VERSION ""

NS_ :

BS_:

BU_: Antilock_Brake_Module AudioControlModule AudioInterfaceModule Audio_Control_Module Audio_Interface_Module BluetoothPhoneModule Bluetooth_Phone_Module BodyElectricModule Body_Electronic_Module Data_Request Data_Response Diagnostic_Tester FrontDisplayInterfaceModule Front_Display_Interface_Module HVAC_Integrated_Module HvacIntegratedModule InstrumentCluster Instrument_Cluster NegativeResponseError OnBoardDiagnostics On_Board_Diagnostics ParkingAidModule Parking_Aid_Module PowertrainControlModule Powertrain_Control_Module RestraintsControlModule Restraints_Control_Module SteeringAngleSensor Steering_Angle_Sensor TDC Transmission_Control_Module Vector__XXX before

CM_ "FG Falcon Combined CAN DBC. Generated from uploaded highSpeedCAN.dbc and BigFalconSheet(1).xlsx. Byte-level overview signals are conservative placeholders where exact scaling/bit layout was not available.";
BA_DEF_ BO_  "Bus" STRING ;
BA_DEF_DEF_  "Bus" "" ;

VAL_TABLE_ Inst_Econ_Mode 1 "L per Hr" 0 "L per 100Km" ;
VAL_TABLE_ Transmission_Configuration 1 "Copperhead" 0 "Barra_E265" ;
VAL_TABLE_ Fuel_Type_And_Delivery 12 "Petrol LPG Dual Fuel" 11 "LPG EFI" 2 "Petrol EFI" ;
VAL_TABLE_ Induction_Type 9 "Unknown" 4 "None" 3 "Supercharged" 2 "Turbocharged" 1 "Naturally Aspirated" ;
VAL_TABLE_ Dash_Ind_State 2 "Flash" 1 "On" 0 "Off" ;
VAL_TABLE_ Gear_Position_Target 15 "Invalid" 12 "Reverse" 6 "Sixth" 5 "Fifth" 4 "Fourth" 3 "Third" 2 "Second" 1 "First" 0 "Neutral" ;
VAL_TABLE_ Required_NotRequired 1 "Not Required" 0 "Required" ;
VAL_TABLE_ Engaged_Disengaged 1 "Engaged" 0 "Disengaged" ;
VAL_TABLE_ Transmission_Shift_Map 7 "Cruise " 6 "Manual" 5 "Traction" 4 "Gradient" 3 "Hot" 2 "Not Used" 1 "Sports" 0 "Normal" ;
VAL_TABLE_ Gear_Position_Actual 15 "Gear Shift In Progress" 12 "Reverse" 6 "Sixth" 5 "Fifth" 4 "Fourth" 3 "Third" 2 "Second" 1 "First" 0 "Neutral" ;
VAL_TABLE_ Gear_Position_Selected 15 "Intermediate" 7 "Fifth" 6 "Second" 5 "Third" 4 "Fourth" 3 "Drive" 2 "Neutral" 1 "Reverse" 0 "Park" ;
VAL_TABLE_ Off_On 1 "On" 0 "Off" ;
VAL_TABLE_ Transmission_Mode 6 "Reserved - Creep" 5 "Economy" 4 "Reserved - Winter" 3 "Manual Shift Mode" 2 "Performance" 1 "ADP" 0 "Blank" ;
VAL_TABLE_ Trans_Gear_Pos 255 "Invalid" 241 "Neutral" 240 "Park" 19 "Forward Gear 9" 18 "Forward Gear 8" 17 "Forward Gear 7" 16 "Forward Gear 6" 11 "Reserved" 10 "Reverse" 6 "Forward Gear D" 5 "Forward Gear 5" 4 "Forward Gear 4" 3 "Forward Gear 3" 2 "Forward Gear 2" 1 "Forward Gear 1" 0 "Blank" ;
VAL_TABLE_ Eng_Crank_Status 3 "Low Voltage Crank Attempt" 2 "Crank In Progress" 1 "Crank Pending" 0 "No Action" ;
VAL_TABLE_ Torque_Type 1 "Engine Torque" 0 "Axle Torque" ;
VAL_TABLE_ Brake_State 3 "Reserved2" 2 "Reserved1" 1 "Brake Pedal Pressed" 0 "Brake Pedal Off" ;
VAL_TABLE_ Cruise_Status 7 "Cruise Active" 2 "Cruise Resume" 1 "Cruise On" 0 "Cruise Off" ;
VAL_TABLE_ Active_Inactive 1 "Active" 0 "Inactive" ;
VAL_TABLE_ True_False 1 "True" 0 "False" ;

BO_ 0 AudioInterfaceModule: 8 AudioInterfaceModule
 SG_ IPOD_FRMVER : 0|8@1+ (1,0) [0|0] "" AudioInterfaceModule
 SG_ AUTHENT_DEVER : 0|8@1+ (1,0) [0|0] "" AudioInterfaceModule
 SG_ CON_DEVERR : 0|8@1+ (1,0) [0|0] "" AudioInterfaceModule
 SG_ CON_DEVMODID : 0|8@1+ (1,0) [0|0] "" AudioInterfaceModule
 SG_ SEC_STAT : 0|8@1+ (1,0) [0|0] "" AudioInterfaceModule
 SG_ NUM_DTC : 0|8@1+ (1,0) [0|0] "" AudioInterfaceModule

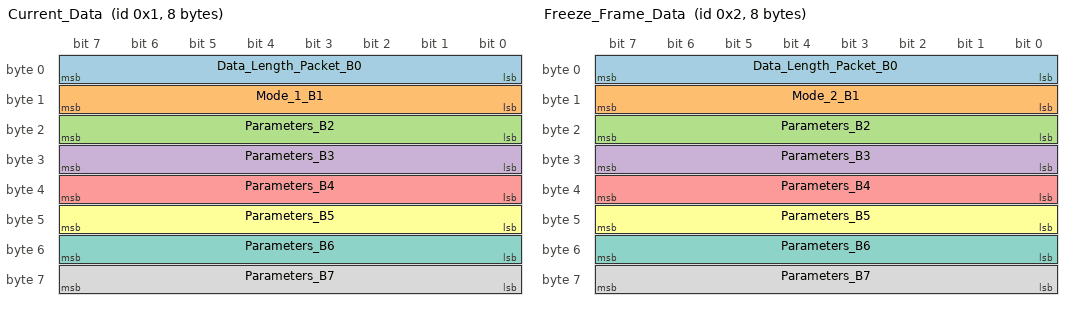
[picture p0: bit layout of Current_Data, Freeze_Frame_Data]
BO_ 1 Current_Data: 8 On_Board_Diagnostics
 SG_ Data_Length_Packet_B0 : 0|8@1+ (1,0) [0|255] "" Vector__XXX
 SG_ Mode_1_B1 : 8|8@1+ (1,0) [0|255] "" Vector__XXX
 SG_ Parameters_B2 : 16|8@1+ (1,0) [0|255] "" Vector__XXX
 SG_ Parameters_B3 : 24|8@1+ (1,0) [0|255] "" Vector__XXX
 SG_ Parameters_B4 : 32|8@1+ (1,0) [0|255] "" Vector__XXX
 SG_ Parameters_B5 : 40|8@1+ (1,0) [0|255] "" Vector__XXX
 SG_ Parameters_B6 : 48|8@1+ (1,0) [0|255] "" Vector__XXX
 SG_ Parameters_B7 : 56|8@1+ (1,0) [0|255] "" Vector__XXX

BO_ 2 Freeze_Frame_Data: 8 On_Board_Diagnostics
 SG_ Data_Length_Packet_B0 : 0|8@1+ (1,0) [0|255] "" Vector__XXX
 SG_ Mode_2_B1 : 8|8@1+ (1,0) [0|255] "" Vector__XXX
 SG_ Parameters_B2 : 16|8@1+ (1,0) [0|255] "" Vector__XXX
 SG_ Parameters_B3 : 24|8@1+ (1,0) [0|255] "" Vector__XXX
 SG_ Parameters_B4 : 32|8@1+ (1,0) [0|255] "" Vector__XXX
 SG_ Parameters_B5 : 40|8@1+ (1,0) [0|255] "" Vector__XXX
 SG_ Parameters_B6 : 48|8@1+ (1,0) [0|255] "" Vector__XXX
 SG_ Parameters_B7 : 56|8@1+ (1,0) [0|255] "" Vector__XXX

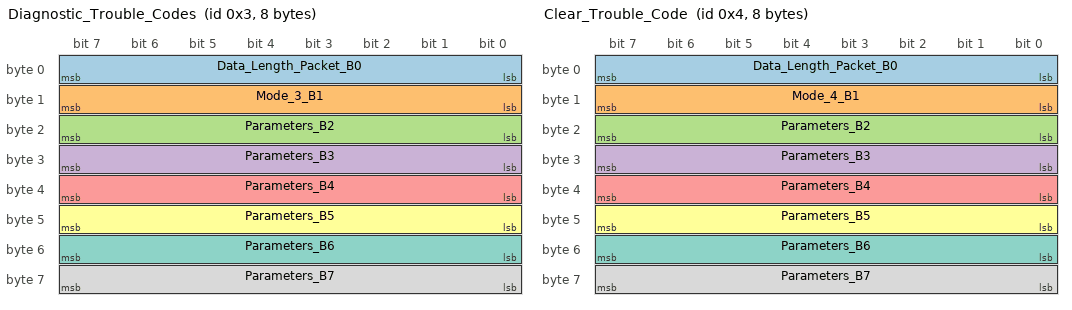
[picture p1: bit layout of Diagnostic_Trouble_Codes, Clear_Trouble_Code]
BO_ 3 Diagnostic_Trouble_Codes: 8 On_Board_Diagnostics
 SG_ Data_Length_Packet_B0 : 0|8@1+ (1,0) [0|255] "" Vector__XXX
 SG_ Mode_3_B1 : 8|8@1+ (1,0) [0|255] "" Vector__XXX
 SG_ Parameters_B2 : 16|8@1+ (1,0) [0|255] "" Vector__XXX
 SG_ Parameters_B3 : 24|8@1+ (1,0) [0|255] "" Vector__XXX
 SG_ Parameters_B4 : 32|8@1+ (1,0) [0|255] "" Vector__XXX
 SG_ Parameters_B5 : 40|8@1+ (1,0) [0|255] "" Vector__XXX
 SG_ Parameters_B6 : 48|8@1+ (1,0) [0|255] "" Vector__XXX
 SG_ Parameters_B7 : 56|8@1+ (1,0) [0|255] "" Vector__XXX

BO_ 4 Clear_Trouble_Code: 8 On_Board_Diagnostics
 SG_ Data_Length_Packet_B0 : 0|8@1+ (1,0) [0|255] "" Vector__XXX
 SG_ Mode_4_B1 : 8|8@1+ (1,0) [0|255] "" Vector__XXX
 SG_ Parameters_B2 : 16|8@1+ (1,0) [0|255] "" Vector__XXX
 SG_ Parameters_B3 : 24|8@1+ (1,0) [0|255] "" Vector__XXX
 SG_ Parameters_B4 : 32|8@1+ (1,0) [0|255] "" Vector__XXX
 SG_ Parameters_B5 : 40|8@1+ (1,0) [0|255] "" Vector__XXX
 SG_ Parameters_B6 : 48|8@1+ (1,0) [0|255] "" Vector__XXX
 SG_ Parameters_B7 : 56|8@1+ (1,0) [0|255] "" Vector__XXX

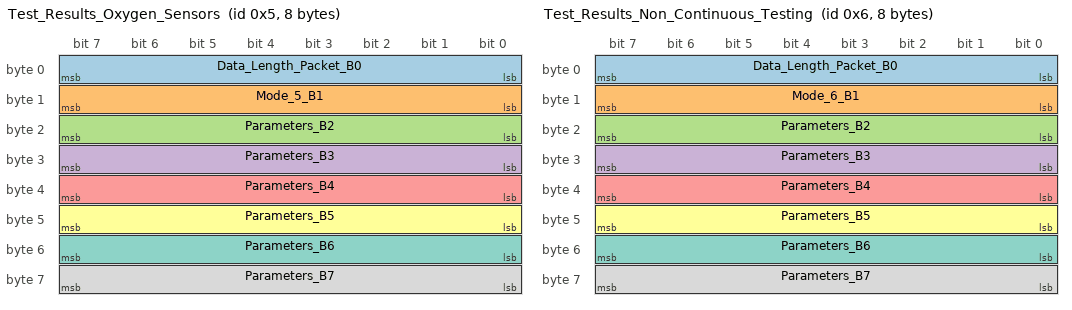
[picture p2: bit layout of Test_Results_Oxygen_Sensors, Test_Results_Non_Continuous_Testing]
BO_ 5 Test_Results_Oxygen_Sensors: 8 On_Board_Diagnostics
 SG_ Data_Length_Packet_B0 : 0|8@1+ (1,0) [0|255] "" Vector__XXX
 SG_ Mode_5_B1 : 8|8@1+ (1,0) [0|255] "" Vector__XXX
 SG_ Parameters_B2 : 16|8@1+ (1,0) [0|255] "" Vector__XXX
 SG_ Parameters_B3 : 24|8@1+ (1,0) [0|255] "" Vector__XXX
 SG_ Parameters_B4 : 32|8@1+ (1,0) [0|255] "" Vector__XXX
 SG_ Parameters_B5 : 40|8@1+ (1,0) [0|255] "" Vector__XXX
 SG_ Parameters_B6 : 48|8@1+ (1,0) [0|255] "" Vector__XXX
 SG_ Parameters_B7 : 56|8@1+ (1,0) [0|255] "" Vector__XXX

BO_ 6 Test_Results_Non_Continuous_Testing: 8 On_Board_Diagnostics
 SG_ Data_Length_Packet_B0 : 0|8@1+ (1,0) [0|255] "" Vector__XXX
 SG_ Mode_6_B1 : 8|8@1+ (1,0) [0|255] "" Vector__XXX
 SG_ Parameters_B2 : 16|8@1+ (1,0) [0|255] "" Vector__XXX
 SG_ Parameters_B3 : 24|8@1+ (1,0) [0|255] "" Vector__XXX
 SG_ Parameters_B4 : 32|8@1+ (1,0) [0|255] "" Vector__XXX
 SG_ Parameters_B5 : 40|8@1+ (1,0) [0|255] "" Vector__XXX
 SG_ Parameters_B6 : 48|8@1+ (1,0) [0|255] "" Vector__XXX
 SG_ Parameters_B7 : 56|8@1+ (1,0) [0|255] "" Vector__XXX

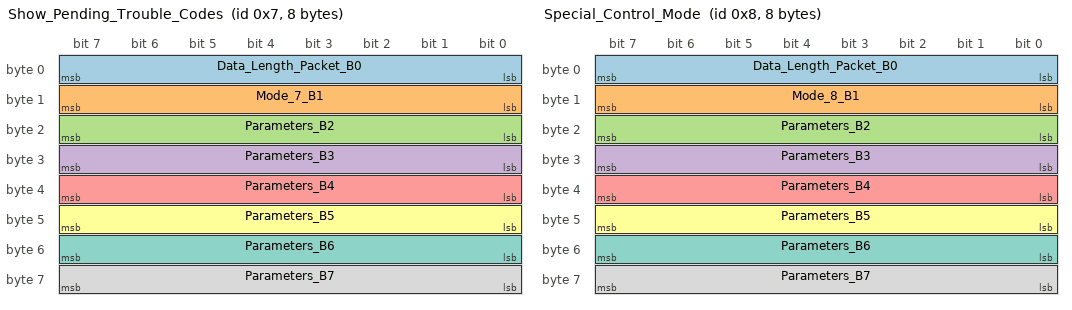
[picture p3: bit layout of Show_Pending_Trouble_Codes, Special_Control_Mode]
BO_ 7 Show_Pending_Trouble_Codes: 8 On_Board_Diagnostics
 SG_ Data_Length_Packet_B0 : 0|8@1+ (1,0) [0|255] "" Vector__XXX
 SG_ Mode_7_B1 : 8|8@1+ (1,0) [0|255] "" Vector__XXX
 SG_ Parameters_B2 : 16|8@1+ (1,0) [0|255] "" Vector__XXX
 SG_ Parameters_B3 : 24|8@1+ (1,0) [0|255] "" Vector__XXX
 SG_ Parameters_B4 : 32|8@1+ (1,0) [0|255] "" Vector__XXX
 SG_ Parameters_B5 : 40|8@1+ (1,0) [0|255] "" Vector__XXX
 SG_ Parameters_B6 : 48|8@1+ (1,0) [0|255] "" Vector__XXX
 SG_ Parameters_B7 : 56|8@1+ (1,0) [0|255] "" Vector__XXX

BO_ 8 Special_Control_Mode: 8 On_Board_Diagnostics
 SG_ Data_Length_Packet_B0 : 0|8@1+ (1,0) [0|255] "" Vector__XXX
 SG_ Mode_8_B1 : 8|8@1+ (1,0) [0|255] "" Vector__XXX
 SG_ Parameters_B2 : 16|8@1+ (1,0) [0|255] "" Vector__XXX
 SG_ Parameters_B3 : 24|8@1+ (1,0) [0|255] "" Vector__XXX
 SG_ Parameters_B4 : 32|8@1+ (1,0) [0|255] "" Vector__XXX
 SG_ Parameters_B5 : 40|8@1+ (1,0) [0|255] "" Vector__XXX
 SG_ Parameters_B6 : 48|8@1+ (1,0) [0|255] "" Vector__XXX
 SG_ Parameters_B7 : 56|8@1+ (1,0) [0|255] "" Vector__XXX

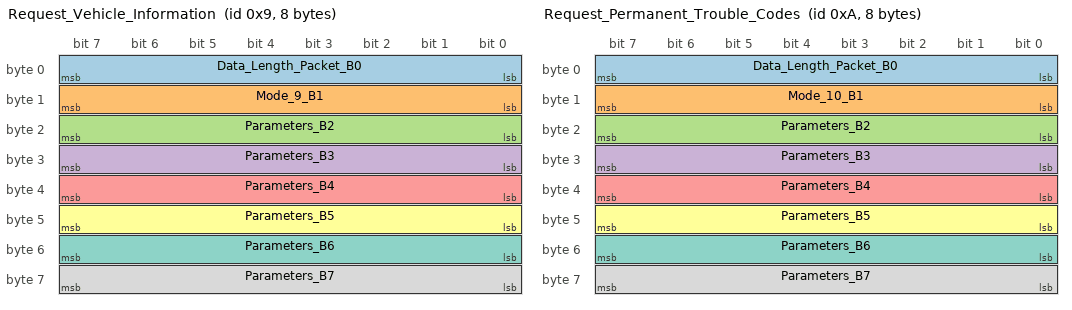
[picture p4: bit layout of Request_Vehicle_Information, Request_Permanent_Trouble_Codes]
BO_ 9 Request_Vehicle_Information: 8 On_Board_Diagnostics
 SG_ Data_Length_Packet_B0 : 0|8@1+ (1,0) [0|255] "" Vector__XXX
 SG_ Mode_9_B1 : 8|8@1+ (1,0) [0|255] "" Vector__XXX
 SG_ Parameters_B2 : 16|8@1+ (1,0) [0|255] "" Vector__XXX
 SG_ Parameters_B3 : 24|8@1+ (1,0) [0|255] "" Vector__XXX
 SG_ Parameters_B4 : 32|8@1+ (1,0) [0|255] "" Vector__XXX
 SG_ Parameters_B5 : 40|8@1+ (1,0) [0|255] "" Vector__XXX
 SG_ Parameters_B6 : 48|8@1+ (1,0) [0|255] "" Vector__XXX
 SG_ Parameters_B7 : 56|8@1+ (1,0) [0|255] "" Vector__XXX

BO_ 10 Request_Permanent_Trouble_Codes: 8 On_Board_Diagnostics
 SG_ Data_Length_Packet_B0 : 0|8@1+ (1,0) [0|255] "" Vector__XXX
 SG_ Mode_10_B1 : 8|8@1+ (1,0) [0|255] "" Vector__XXX
 SG_ Parameters_B2 : 16|8@1+ (1,0) [0|255] "" Vector__XXX
 SG_ Parameters_B3 : 24|8@1+ (1,0) [0|255] "" Vector__XXX
 SG_ Parameters_B4 : 32|8@1+ (1,0) [0|255] "" Vector__XXX
 SG_ Parameters_B5 : 40|8@1+ (1,0) [0|255] "" Vector__XXX
 SG_ Parameters_B6 : 48|8@1+ (1,0) [0|255] "" Vector__XXX
 SG_ Parameters_B7 : 56|8@1+ (1,0) [0|255] "" Vector__XXX

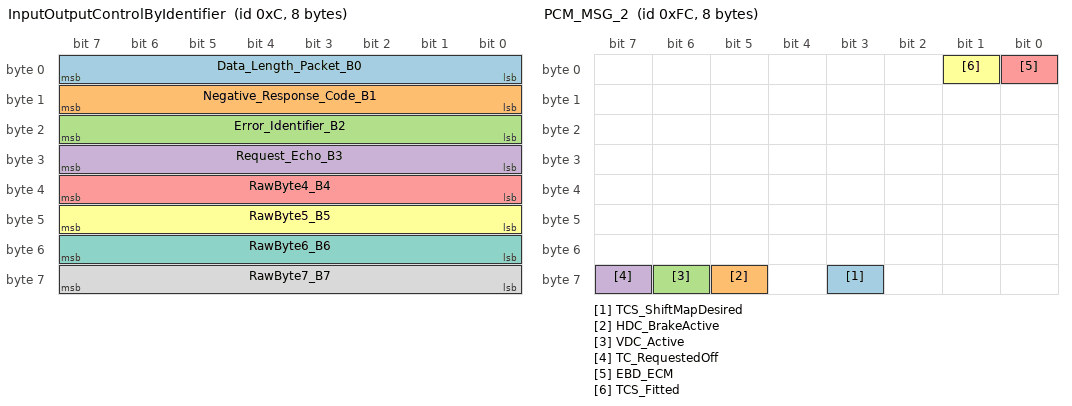
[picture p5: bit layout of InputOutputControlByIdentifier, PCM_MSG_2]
BO_ 12 InputOutputControlByIdentifier: 8 NegativeResponseError
 SG_ Data_Length_Packet_B0 : 0|8@1+ (1,0) [0|255] "" Vector__XXX
 SG_ Negative_Response_Code_B1 : 8|8@1+ (1,0) [0|255] "" Vector__XXX
 SG_ Error_Identifier_B2 : 16|8@1+ (1,0) [0|255] "" Vector__XXX
 SG_ Request_Echo_B3 : 24|8@1+ (1,0) [0|255] "" Vector__XXX
 SG_ RawByte4_B4 : 32|8@1+ (1,0) [0|255] "" Vector__XXX
 SG_ RawByte5_B5 : 40|8@1+ (1,0) [0|255] "" Vector__XXX
 SG_ RawByte6_B6 : 48|8@1+ (1,0) [0|255] "" Vector__XXX
 SG_ RawByte7_B7 : 56|8@1+ (1,0) [0|255] "" Vector__XXX

BO_ 80 SteeringAngleSensor: 8 SteeringAngleSensor

BO_ 112 YAW_MSG_1: 8 Vector__XXX

BO_ 117 YAW_MSG_2: 8 Vector__XXX

BO_ 128 SAS_MSG_1: 8 Vector__XXX

BO_ 133 YAW_MSG_3: 8 Vector__XXX

BO_ 144 SAS_MSG_2: 8 Vector__XXX
 SG_ Steering_Wheel_Angle : 7|16@0- (0.1,0) [0|0] "deg" Vector__XXX

BO_ 151 PCM_MSG_1: 8 Vector__XXX
 SG_ Indicated_Eng_Torque : 7|16@0+ (1,0) [0|0] "Nm" Vector__XXX
 SG_ Eng_Friction_Torque : 23|16@0+ (1,0) [0|0] "Nm" Vector__XXX
 SG_ Driver_Demand_Torque : 55|16@0+ (1,0) [0|0] "Nm" Vector__XXX
 SG_ Actual_Eng_Torque : 39|16@0+ (1,0) [0|0] "Nm" Vector__XXX

BO_ 201 TCM_MSG_1: 8 Vector__XXX
 SG_ Transmission_Output_Speed : 55|16@0+ (1,0) [0|0] "rpm" Vector__XXX
 SG_ Transmission_Input_Speed : 39|16@0+ (1,0) [0|0] "rpm" Vector__XXX
 SG_ Torque_Conv_Slip : 31|8@0+ (1,0) [0|0] "" Vector__XXX
 SG_ Transmission_Torque_Limit : 23|8@0+ (4,0) [0|0] "Nm" Vector__XXX
 SG_ Torque_Reduction : 7|16@0+ (1,0) [0|0] "" Vector__XXX

BO_ 252 PCM_MSG_2: 8 Vector__XXX
 SG_ TCS_ShiftMapDesired : 59|1@0+ (1,0) [0|0] "" Vector__XXX
 SG_ HDC_BrakeActive : 61|1@0+ (1,0) [0|0] "" Vector__XXX
 SG_ VDC_Active : 62|1@0+ (1,0) [0|0] "" Vector__XXX
 SG_ TC_RequestedOff : 63|1@0+ (1,0) [0|0] "" Vector__XXX
 SG_ EBD_ECM : 0|1@0+ (1,0) [0|0] "" Vector__XXX
 SG_ TCS_Fitted : 1|1@0+ (1,0) [0|0] "" Vector__XXX

BO_ 288 PCM_MSG_3: 8 Vector__XXX
 SG_ Indicated_Eng_Torque : 7|16@0+ (1,0) [0|0] "Nm" Vector__XXX
 SG_ Estimated_Eng_Torque : 23|16@0+ (1,0) [0|0] "Nm" Vector__XXX

BO_ 296 BEM_MSG_3: 8 Vector__XXX
 SG_ Interior_Dimmer_Low : 15|8@0+ (1,0) [0|0] "" Vector__XXX
 SG_ Interior_Dimmer_High : 23|8@0+ (1,0) [0|0] "" Vector__XXX
 SG_ Lights_Auto : 0|1@0+ (1,0) [0|0] "" Vector__XXX
 SG_ Lights_Fog : 2|1@0+ (1,0) [0|0] "" Vector__XXX
 SG_ Lights_Parker : 1|1@0+ (1,0) [0|0] "" Vector__XXX
 SG_ Lights_HighBeam : 3|1@0+ (1,0) [0|0] "" Vector__XXX
 SG_ Right_Indicator : 28|1@0+ (1,0) [0|0] "" Vector__XXX
 SG_ Left_Indicator : 27|1@0+ (1,0) [0|0] "" Vector__XXX
 SG_ HighBeamStatus : 0|1@1+ (1,0) [0|0] "" BodyElectricModule
 SG_ IllumLevelDisplay : 8|8@1+ (1,0) [0|0] "" FrontDisplayInterfaceModule
 SG_ IllumLevelSwitch : 24|8@1+ (1,0) [0|0] "" BodyElectricModule
 SG_ AutoHeadlampSwitchStatus : 0|8@1+ (1,0) [0|0] "" BodyElectricModule
 SG_ FogLampStatus : 0|8@1+ (1,0) [0|0] "" BodyElectricModule
 SG_ ParkAndLowBeamStatus : 0|1@1+ (1,0) [0|0] "" BodyElectricModule
 SG_ TurnStalkSwitchSatus : 16|8@1+ (1,0) [0|0] "" BodyElectricModule
 SG_ RearBeltMinderStatus : 56|8@1+ (1,0) [0|0] "" RestraintsControlModule

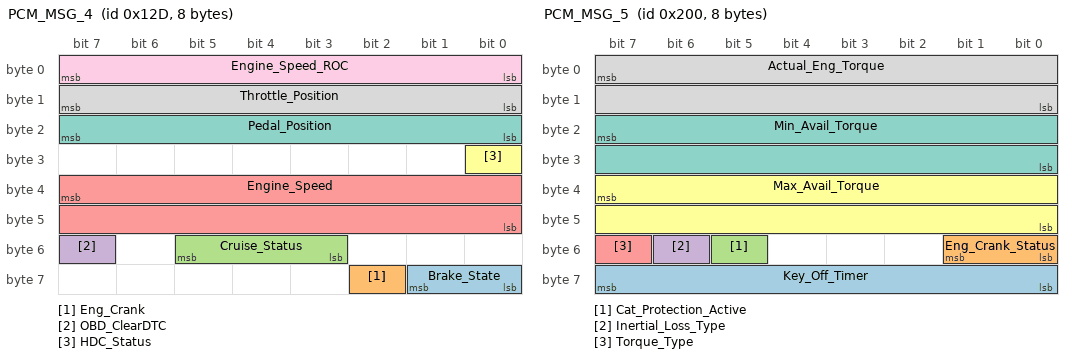
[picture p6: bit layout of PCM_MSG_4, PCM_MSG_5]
BO_ 301 PCM_MSG_4: 8 Vector__XXX
 SG_ Brake_State : 57|2@0+ (1,0) [0|0] "" Vector__XXX
 SG_ Eng_Crank : 58|1@0+ (1,0) [0|0] "" Vector__XXX
 SG_ Cruise_Status : 53|3@0+ (1,0) [0|0] "" Vector__XXX
 SG_ OBD_ClearDTC : 55|1@0+ (1,0) [0|0] "" Vector__XXX
 SG_ Engine_Speed : 39|16@0+ (0.25,0) [0|0] "rpm" Vector__XXX
 SG_ HDC_Status : 24|1@0+ (1,0) [0|0] "" Vector__XXX
 SG_ Pedal_Position : 23|8@0+ (0.5,0) [0|0] "%" Vector__XXX
 SG_ Throttle_Position : 15|8@0+ (0.5,0) [0|0] "%" Vector__XXX
 SG_ Engine_Speed_ROC : 7|8@0+ (0.015625,-2) [0|0] "rpm/s" Vector__XXX

BO_ 471 FE_9D_DF_E6_63_F4_B6: 7 Instrument_Cluster
 SG_ RawByte0_B0 : 0|8@1+ (1,0) [0|255] "" Vector__XXX
 SG_ RawByte1_B1 : 8|8@1+ (1,0) [0|255] "" Vector__XXX
 SG_ RawByte2_B2 : 16|8@1+ (1,0) [0|255] "" Vector__XXX
 SG_ RawByte3_B3 : 24|8@1+ (1,0) [0|255] "" Vector__XXX
 SG_ RawByte4_B4 : 32|8@1+ (1,0) [0|255] "" Vector__XXX
 SG_ RawByte5_B5 : 40|8@1+ (1,0) [0|255] "" Vector__XXX
 SG_ RawByte6_B6 : 48|8@1+ (1,0) [0|255] "" Vector__XXX
 SG_ Remote_Request_Frame_B0 : 0|8@1+ (1,0) [0|255] "" Vector__XXX

BO_ 512 PCM_MSG_5: 8 Vector__XXX
 SG_ Key_Off_Timer : 63|8@0+ (1,0) [0|0] "Min" Vector__XXX
 SG_ Eng_Crank_Status : 49|2@0+ (1,0) [0|0] "" Vector__XXX
 SG_ Cat_Protection_Active : 53|1@0+ (1,0) [0|0] "" Vector__XXX
 SG_ Inertial_Loss_Type : 54|1@0+ (1,0) [0|0] "" Vector__XXX
 SG_ Torque_Type : 55|1@0+ (1,0) [0|0] "" Vector__XXX
 SG_ Max_Avail_Torque : 39|16@0+ (1,-512) [0|0] "Nm" Vector__XXX
 SG_ Min_Avail_Torque : 23|16@0+ (1,-512) [0|0] "Nm" Vector__XXX
 SG_ Actual_Eng_Torque : 7|16@0+ (1,-512) [0|0] "Nm" Vector__XXX

BO_ 519 PCM_MSG_6: 8 Vector__XXX
 SG_ Throttle_Position_ROC : 63|8@0- (1,0) [0|0] "%/s" Vector__XXX
 SG_ Throttle_Position : 55|8@0+ (0.5,0) [0|0] "%" Vector__XXX
 SG_ Vehicle_Speed : 39|16@0+ (0.0078125,0) [0|0] "km/h" Vector__XXX
 SG_ Engine_Speed_ROC : 23|16@0- (0.25,0) [0|0] "rpm/s" Vector__XXX
 SG_ Engine_Speed : 7|16@0+ (0.25,0) [0|0] "rpm" Vector__XXX

BO_ 528 ABS_MSG_1: 8 Vector__XXX
 SG_ Gear_Shift_Inhibit : 35|1@0+ (1,0) [0|0] "" Vector__XXX
 SG_ BTM_Clear_EngOff_Timer : 36|1@0+ (1,0) [0|0] "" Vector__XXX
 SG_ HDC_Failed : 37|1@0+ (1,0) [0|0] "" Vector__XXX
 SG_ HDC_Active : 38|1@0+ (1,0) [0|0] "" Vector__XXX
 SG_ HDC_Enabled : 39|1@0+ (1,0) [0|0] "" Vector__XXX
 SG_ VDC_Failed : 24|1@0+ (1,0) [0|0] "" Vector__XXX
 SG_ VDC_Active : 25|1@0+ (1,0) [0|0] "" Vector__XXX
 SG_ VDC_Disabled_ByUser : 26|1@0+ (1,0) [0|0] "" Vector__XXX
 SG_ TCS_Failed : 27|1@0+ (1,0) [0|0] "" Vector__XXX
 SG_ TCS_Active : 28|1@0+ (1,0) [0|0] "" Vector__XXX
 SG_ TCS_Disabled_ByUser : 29|1@0+ (1,0) [0|0] "" Vector__XXX
 SG_ ABS_Failed : 30|1@0+ (1,0) [0|0] "" Vector__XXX
 SG_ EBD_Failed : 31|1@0+ (1,0) [0|0] "" Vector__XXX
 SG_ ABS_Active : 16|1@0+ (1,0) [0|0] "" Vector__XXX
 SG_ Split_SlowFast_Torque_Req : 17|1@0+ (1,0) [0|0] "" Vector__XXX
 SG_ ABD_Fitted : 18|1@0+ (1,0) [0|0] "" Vector__XXX
 SG_ VDC_Fitted : 19|1@0+ (1,0) [0|0] "" Vector__XXX
 SG_ TCS_Fitted : 20|1@0+ (1,0) [0|0] "" Vector__XXX
 SG_ ABS_Fitted : 21|1@0+ (1,0) [0|0] "" Vector__XXX
 SG_ EBD_Fitted : 22|1@0+ (1,0) [0|0] "" Vector__XXX
 SG_ Torque_Type : 23|1@0+ (1,0) [0|0] "" Vector__XXX
 SG_ Desired_Torque_Command_Slow : 47|16@0+ (1,-512) [0|0] "Nm" Vector__XXX
 SG_ Desired_Torque_Command : 7|16@0+ (1,-512) [0|0] "Nm" Vector__XXX

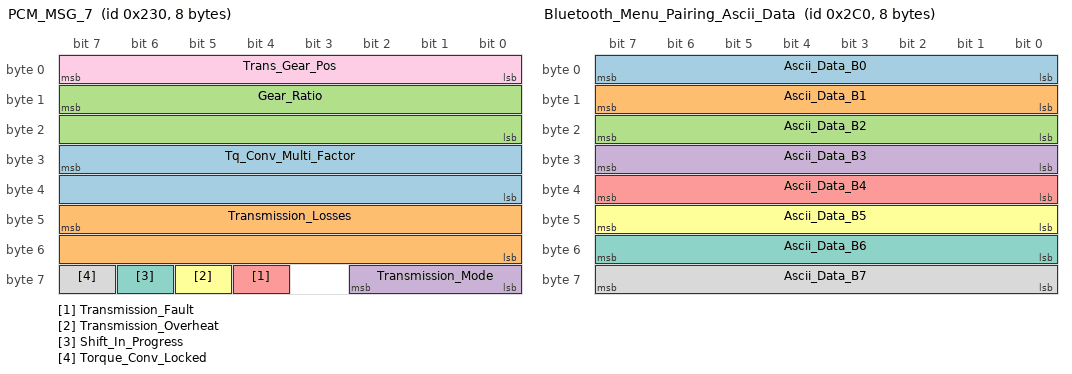
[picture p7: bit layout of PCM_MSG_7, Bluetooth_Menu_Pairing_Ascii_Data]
BO_ 560 PCM_MSG_7: 8 Vector__XXX
 SG_ Tq_Conv_Multi_Factor : 31|16@0+ (6.1035E-005,0.01) [0|0] "ratio" Vector__XXX
 SG_ Transmission_Losses : 47|16@0+ (1,0) [0|0] "" Vector__XXX
 SG_ Gear_Ratio : 15|16@0+ (6.1035E-005,0) [0|0] "ratio" Vector__XXX
 SG_ Transmission_Mode : 58|3@0+ (1,0) [0|0] "" Vector__XXX
 SG_ Transmission_Fault : 60|1@0+ (1,0) [0|0] "" Vector__XXX
 SG_ Transmission_Overheat : 61|1@0+ (1,0) [0|0] "" Vector__XXX
 SG_ Shift_In_Progress : 62|1@0+ (1,0) [0|0] "" Vector__XXX
 SG_ Torque_Conv_Locked : 63|1@0+ (1,0) [0|0] "" Vector__XXX
 SG_ Trans_Gear_Pos : 7|8@0+ (1,0) [0|0] "" Vector__XXX

BO_ 704 Bluetooth_Menu_Pairing_Ascii_Data: 8 Bluetooth_Phone_Module
 SG_ Ascii_Data_B0 : 0|8@1+ (1,0) [0|255] "" Vector__XXX
 SG_ Ascii_Data_B1 : 8|8@1+ (1,0) [0|255] "" Vector__XXX
 SG_ Ascii_Data_B2 : 16|8@1+ (1,0) [0|255] "" Vector__XXX
 SG_ Ascii_Data_B3 : 24|8@1+ (1,0) [0|255] "" Vector__XXX
 SG_ Ascii_Data_B4 : 32|8@1+ (1,0) [0|255] "" Vector__XXX
 SG_ Ascii_Data_B5 : 40|8@1+ (1,0) [0|255] "" Vector__XXX
 SG_ Ascii_Data_B6 : 48|8@1+ (1,0) [0|255] "" Vector__XXX
 SG_ Ascii_Data_B7 : 56|8@1+ (1,0) [0|255] "" Vector__XXX

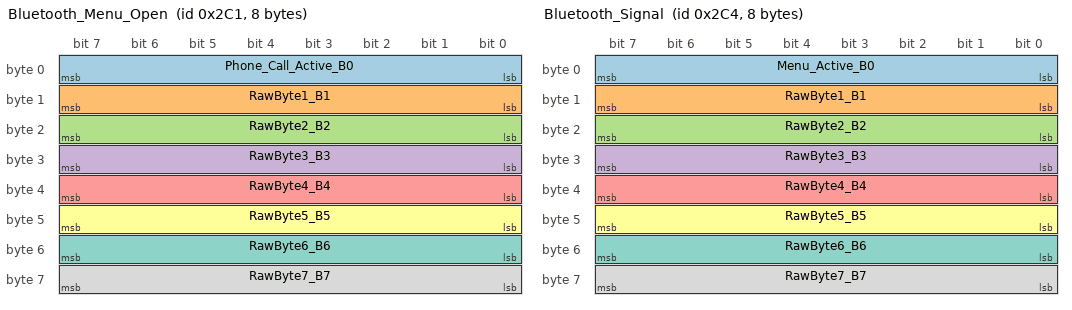
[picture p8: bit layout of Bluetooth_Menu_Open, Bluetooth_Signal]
BO_ 705 Bluetooth_Menu_Open: 8 Bluetooth_Phone_Module
 SG_ Phone_Call_Active_B0 : 0|8@1+ (1,0) [0|255] "" Vector__XXX
 SG_ RawByte1_B1 : 8|8@1+ (1,0) [0|255] "" Vector__XXX
 SG_ RawByte2_B2 : 16|8@1+ (1,0) [0|255] "" Vector__XXX
 SG_ RawByte3_B3 : 24|8@1+ (1,0) [0|255] "" Vector__XXX
 SG_ RawByte4_B4 : 32|8@1+ (1,0) [0|255] "" Vector__XXX
 SG_ RawByte5_B5 : 40|8@1+ (1,0) [0|255] "" Vector__XXX
 SG_ RawByte6_B6 : 48|8@1+ (1,0) [0|255] "" Vector__XXX
 SG_ RawByte7_B7 : 56|8@1+ (1,0) [0|255] "" Vector__XXX

BO_ 708 Bluetooth_Signal: 8 Bluetooth_Phone_Module
 SG_ Menu_Active_B0 : 0|8@1+ (1,0) [0|255] "" Vector__XXX
 SG_ RawByte1_B1 : 8|8@1+ (1,0) [0|255] "" Vector__XXX
 SG_ RawByte2_B2 : 16|8@1+ (1,0) [0|255] "" Vector__XXX
 SG_ RawByte3_B3 : 24|8@1+ (1,0) [0|255] "" Vector__XXX
 SG_ RawByte4_B4 : 32|8@1+ (1,0) [0|255] "" Vector__XXX
 SG_ RawByte5_B5 : 40|8@1+ (1,0) [0|255] "" Vector__XXX
 SG_ RawByte6_B6 : 48|8@1+ (1,0) [0|255] "" Vector__XXX
 SG_ RawByte7_B7 : 56|8@1+ (1,0) [0|255] "" Vector__XXX

BO_ 714 MSG1: 8 BluetoothPhoneModule
 SG_ BpmContinuousTroubleCodes : 0|8@1+ (1,0) [0|255] "" BluetoothPhoneModule
 SG_ BpmOperatingState : 0|8@1+ (1,0) [0|255] "" BluetoothPhoneModule
 SG_ BpmOnDemandDtcs : 0|8@1+ (1,0) [0|255] "" BluetoothPhoneModule
 SG_ SecurityStatusBpm : 8|8@1+ (1,0) [0|255] "" BluetoothPhoneModule
 SG_ BTH_CONTD : 0|8@1+ (1,0) [0|255] "" BluetoothPhoneModule

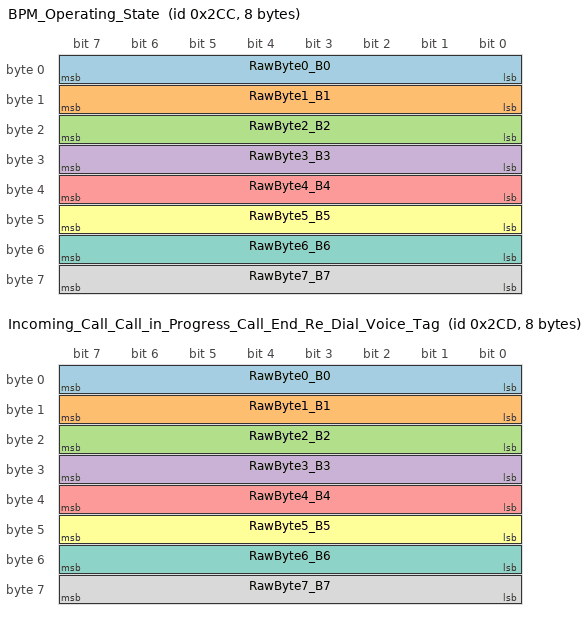
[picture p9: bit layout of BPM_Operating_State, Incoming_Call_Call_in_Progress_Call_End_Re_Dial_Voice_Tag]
BO_ 716 BPM_Operating_State: 8 Bluetooth_Phone_Module
 SG_ RawByte0_B0 : 0|8@1+ (1,0) [0|255] "" Vector__XXX
 SG_ RawByte1_B1 : 8|8@1+ (1,0) [0|255] "" Vector__XXX
 SG_ RawByte2_B2 : 16|8@1+ (1,0) [0|255] "" Vector__XXX
 SG_ RawByte3_B3 : 24|8@1+ (1,0) [0|255] "" Vector__XXX
 SG_ RawByte4_B4 : 32|8@1+ (1,0) [0|255] "" Vector__XXX
 SG_ RawByte5_B5 : 40|8@1+ (1,0) [0|255] "" Vector__XXX
 SG_ RawByte6_B6 : 48|8@1+ (1,0) [0|255] "" Vector__XXX
 SG_ RawByte7_B7 : 56|8@1+ (1,0) [0|255] "" Vector__XXX

BO_ 717 Incoming_Call_Call_in_Progress_Call_End_Re_Dial_Voice_Tag: 8 Bluetooth_Phone_Module
 SG_ RawByte0_B0 : 0|8@1+ (1,0) [0|255] "" Vector__XXX
 SG_ RawByte1_B1 : 8|8@1+ (1,0) [0|255] "" Vector__XXX
 SG_ RawByte2_B2 : 16|8@1+ (1,0) [0|255] "" Vector__XXX
 SG_ RawByte3_B3 : 24|8@1+ (1,0) [0|255] "" Vector__XXX
 SG_ RawByte4_B4 : 32|8@1+ (1,0) [0|255] "" Vector__XXX
 SG_ RawByte5_B5 : 40|8@1+ (1,0) [0|255] "" Vector__XXX
 SG_ RawByte6_B6 : 48|8@1+ (1,0) [0|255] "" Vector__XXX
 SG_ RawByte7_B7 : 56|8@1+ (1,0) [0|255] "" Vector__XXX

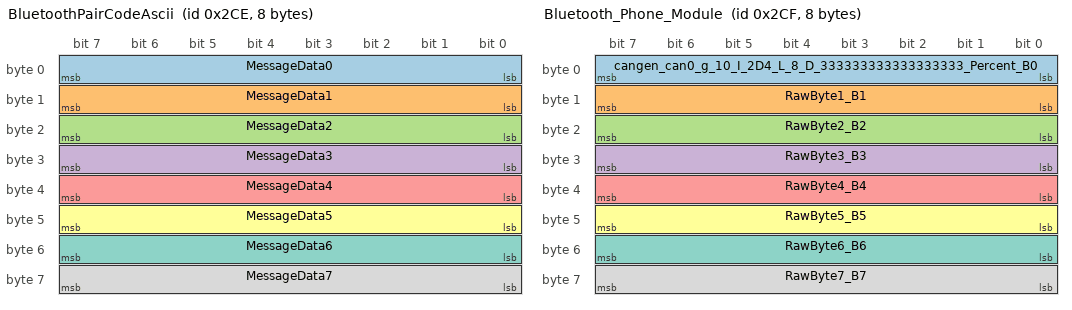
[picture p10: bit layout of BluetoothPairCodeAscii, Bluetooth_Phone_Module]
BO_ 718 BluetoothPairCodeAscii: 8 BluetoothPhoneModule
 SG_ MessageData0 : 0|8@1+ (1,0) [0|255] "" FrontDisplayInterfaceModule
 SG_ MessageData1 : 8|8@1+ (1,0) [0|255] "" FrontDisplayInterfaceModule
 SG_ MessageData2 : 16|8@1+ (1,0) [0|255] "" FrontDisplayInterfaceModule
 SG_ MessageData3 : 24|8@1+ (1,0) [0|255] "" FrontDisplayInterfaceModule
 SG_ MessageData4 : 32|8@1+ (1,0) [0|255] "" FrontDisplayInterfaceModule
 SG_ MessageData5 : 40|8@1+ (1,0) [0|255] "" FrontDisplayInterfaceModule
 SG_ MessageData6 : 48|8@1+ (1,0) [0|255] "" FrontDisplayInterfaceModule
 SG_ MessageData7 : 56|8@1+ (1,0) [0|255] "" FrontDisplayInterfaceModule

BO_ 719 Bluetooth_Phone_Module: 8 Bluetooth_Phone_Module
 SG_ cangen_can0_g_10_I_2D4_L_8_D_333333333333333333_Percent_B0 : 0|8@1+ (1,0) [0|255] "" Vector__XXX
 SG_ RawByte1_B1 : 8|8@1+ (1,0) [0|255] "" Vector__XXX
 SG_ RawByte2_B2 : 16|8@1+ (1,0) [0|255] "" Vector__XXX
 SG_ RawByte3_B3 : 24|8@1+ (1,0) [0|255] "" Vector__XXX
 SG_ RawByte4_B4 : 32|8@1+ (1,0) [0|255] "" Vector__XXX
 SG_ RawByte5_B5 : 40|8@1+ (1,0) [0|255] "" Vector__XXX
 SG_ RawByte6_B6 : 48|8@1+ (1,0) [0|255] "" Vector__XXX
 SG_ RawByte7_B7 : 56|8@1+ (1,0) [0|255] "" Vector__XXX

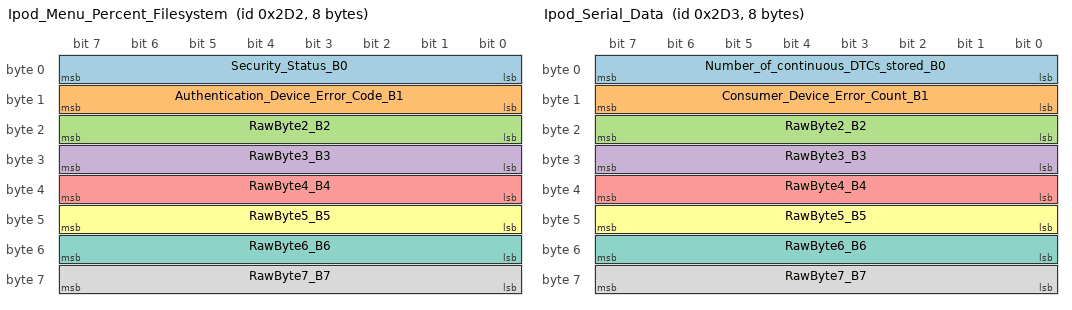
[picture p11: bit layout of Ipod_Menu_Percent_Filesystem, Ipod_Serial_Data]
BO_ 722 Ipod_Menu_Percent_Filesystem: 8 Audio_Interface_Module
 SG_ Security_Status_B0 : 0|8@1+ (1,0) [0|255] "" Vector__XXX
 SG_ Authentication_Device_Error_Code_B1 : 8|8@1+ (1,0) [0|255] "" Vector__XXX
 SG_ RawByte2_B2 : 16|8@1+ (1,0) [0|255] "" Vector__XXX
 SG_ RawByte3_B3 : 24|8@1+ (1,0) [0|255] "" Vector__XXX
 SG_ RawByte4_B4 : 32|8@1+ (1,0) [0|255] "" Vector__XXX
 SG_ RawByte5_B5 : 40|8@1+ (1,0) [0|255] "" Vector__XXX
 SG_ RawByte6_B6 : 48|8@1+ (1,0) [0|255] "" Vector__XXX
 SG_ RawByte7_B7 : 56|8@1+ (1,0) [0|255] "" Vector__XXX

BO_ 723 Ipod_Serial_Data: 8 Audio_Interface_Module
 SG_ Number_of_continuous_DTCs_stored_B0 : 0|8@1+ (1,0) [0|255] "" Vector__XXX
 SG_ Consumer_Device_Error_Count_B1 : 8|8@1+ (1,0) [0|255] "" Vector__XXX
 SG_ RawByte2_B2 : 16|8@1+ (1,0) [0|255] "" Vector__XXX
 SG_ RawByte3_B3 : 24|8@1+ (1,0) [0|255] "" Vector__XXX
 SG_ RawByte4_B4 : 32|8@1+ (1,0) [0|255] "" Vector__XXX
 SG_ RawByte5_B5 : 40|8@1+ (1,0) [0|255] "" Vector__XXX
 SG_ RawByte6_B6 : 48|8@1+ (1,0) [0|255] "" Vector__XXX
 SG_ RawByte7_B7 : 56|8@1+ (1,0) [0|255] "" Vector__XXX

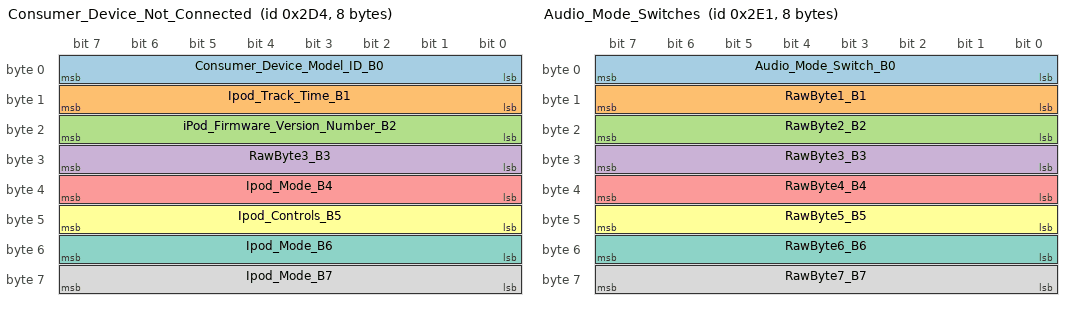
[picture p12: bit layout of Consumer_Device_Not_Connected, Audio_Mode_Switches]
BO_ 724 Consumer_Device_Not_Connected: 8 Audio_Interface_Module
 SG_ Consumer_Device_Model_ID_B0 : 0|8@1+ (1,0) [0|255] "" Vector__XXX
 SG_ Ipod_Track_Time_B1 : 8|8@1+ (1,0) [0|255] "" Vector__XXX
 SG_ iPod_Firmware_Version_Number_B2 : 16|8@1+ (1,0) [0|255] "" Vector__XXX
 SG_ RawByte3_B3 : 24|8@1+ (1,0) [0|255] "" Vector__XXX
 SG_ Ipod_Mode_B4 : 32|8@1+ (1,0) [0|255] "" Vector__XXX
 SG_ Ipod_Controls_B5 : 40|8@1+ (1,0) [0|255] "" Vector__XXX
 SG_ Ipod_Mode_B6 : 48|8@1+ (1,0) [0|255] "" Vector__XXX
 SG_ Ipod_Mode_B7 : 56|8@1+ (1,0) [0|255] "" Vector__XXX

BO_ 725 MessageLabel: 8 Vector__XXX

BO_ 737 Audio_Mode_Switches: 8 Audio_Control_Module
 SG_ Audio_Mode_Switch_B0 : 0|8@1+ (1,0) [0|255] "" Vector__XXX
 SG_ RawByte1_B1 : 8|8@1+ (1,0) [0|255] "" Vector__XXX
 SG_ RawByte2_B2 : 16|8@1+ (1,0) [0|255] "" Vector__XXX
 SG_ RawByte3_B3 : 24|8@1+ (1,0) [0|255] "" Vector__XXX
 SG_ RawByte4_B4 : 32|8@1+ (1,0) [0|255] "" Vector__XXX
 SG_ RawByte5_B5 : 40|8@1+ (1,0) [0|255] "" Vector__XXX
 SG_ RawByte6_B6 : 48|8@1+ (1,0) [0|255] "" Vector__XXX
 SG_ RawByte7_B7 : 56|8@1+ (1,0) [0|255] "" Vector__XXX

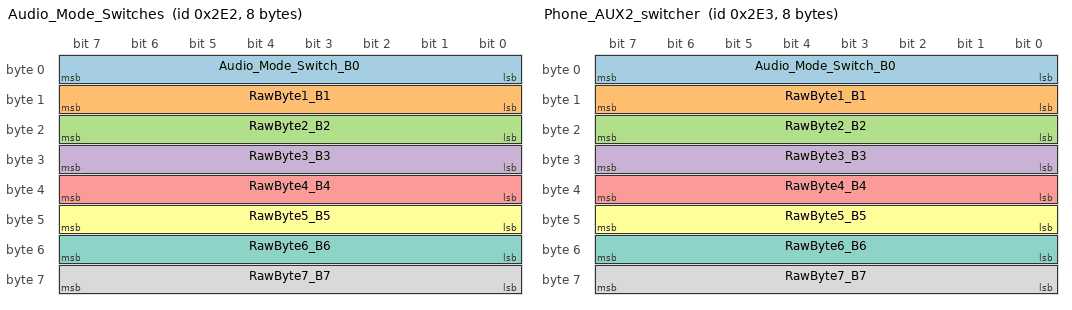
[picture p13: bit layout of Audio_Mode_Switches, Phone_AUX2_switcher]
BO_ 738 Audio_Mode_Switches: 8 Audio_Control_Module
 SG_ Audio_Mode_Switch_B0 : 0|8@1+ (1,0) [0|255] "" Vector__XXX
 SG_ RawByte1_B1 : 8|8@1+ (1,0) [0|255] "" Vector__XXX
 SG_ RawByte2_B2 : 16|8@1+ (1,0) [0|255] "" Vector__XXX
 SG_ RawByte3_B3 : 24|8@1+ (1,0) [0|255] "" Vector__XXX
 SG_ RawByte4_B4 : 32|8@1+ (1,0) [0|255] "" Vector__XXX
 SG_ RawByte5_B5 : 40|8@1+ (1,0) [0|255] "" Vector__XXX
 SG_ RawByte6_B6 : 48|8@1+ (1,0) [0|255] "" Vector__XXX
 SG_ RawByte7_B7 : 56|8@1+ (1,0) [0|255] "" Vector__XXX

BO_ 739 Phone_AUX2_switcher: 8 Audio_Control_Module
 SG_ Audio_Mode_Switch_B0 : 0|8@1+ (1,0) [0|255] "" Vector__XXX
 SG_ RawByte1_B1 : 8|8@1+ (1,0) [0|255] "" Vector__XXX
 SG_ RawByte2_B2 : 16|8@1+ (1,0) [0|255] "" Vector__XXX
 SG_ RawByte3_B3 : 24|8@1+ (1,0) [0|255] "" Vector__XXX
 SG_ RawByte4_B4 : 32|8@1+ (1,0) [0|255] "" Vector__XXX
 SG_ RawByte5_B5 : 40|8@1+ (1,0) [0|255] "" Vector__XXX
 SG_ RawByte6_B6 : 48|8@1+ (1,0) [0|255] "" Vector__XXX
 SG_ RawByte7_B7 : 56|8@1+ (1,0) [0|255] "" Vector__XXX

BO_ 742 AudioTunedFreqRadioDataService: 8 AudioControlModule
 SG_ AudioFMFrequencyStep : 8|8@1+ (0.01,0) [0|255] "" InstrumentCluster
 SG_ AudioTunedFreqency : 0|8@1+ (2,0) [0|255] "" InstrumentCluster
 SG_ AudioTunerBandPreset : 16|8@1+ (1,0) [0|255] "" InstrumentCluster
 SG_ RDS_PSN_State : 56|8@1+ (1,0) [0|0] "" FrontDisplayInterfaceModule

BO_ 748 MessageLabel: 8 Vector__XXX

BO_ 751 Unknown: 8 AudioControlModule

BO_ 754 SWCMediaControlBtns: 8 AudioControlModule
 SG_ AudioCurrentMediaMode : 48|8@1+ (1,0) [0|0] "" FrontDisplayInterfaceModule
 SG_ SteeringWheelControlsLeft_ms : 56|8@1+ (1,0) [0|255] "ACTIVE/INACTIVE" FrontDisplayInterfaceModule
 SG_ AudioVolumeLevel : 0|8@1+ (2,0) [0|15] "Vol" FrontDisplayInterfaceModule

BO_ 756 RDS_MESSAGE: 8 AudioControlModule
 SG_ RDS_MessageData0 : 0|8@1+ (1,0) [0|255] "" FrontDisplayInterfaceModule
 SG_ RDS_MessageData1 : 8|8@1+ (1,0) [0|255] "" FrontDisplayInterfaceModule
 SG_ RDS_MessageData2 : 16|8@1+ (1,0) [0|255] "" FrontDisplayInterfaceModule
 SG_ RDS_MessageData3 : 24|8@1+ (1,0) [0|255] "" FrontDisplayInterfaceModule
 SG_ RDS_MessageData4 : 32|8@1+ (1,0) [0|255] "" FrontDisplayInterfaceModule
 SG_ RDS_MessageData5 : 40|8@1+ (1,0) [0|255] "" FrontDisplayInterfaceModule
 SG_ RDS_MessageData6 : 48|8@1+ (1,0) [0|255] "" FrontDisplayInterfaceModule
 SG_ RDS_MessageData7 : 56|8@1+ (1,0) [0|255] "" FrontDisplayInterfaceModule

BO_ 757 RDS_MESSAGE: 8 AudioControlModule
 SG_ RDS_MessageData0 : 0|8@1+ (1,0) [0|255] "" FrontDisplayInterfaceModule
 SG_ RDS_MessageData1 : 8|8@1+ (1,0) [0|255] "" FrontDisplayInterfaceModule
 SG_ RDS_MessageData2 : 16|8@1+ (1,0) [0|255] "" FrontDisplayInterfaceModule
 SG_ RDS_MessageData3 : 24|8@1+ (1,0) [0|255] "" FrontDisplayInterfaceModule
 SG_ RDS_MessageData4 : 32|8@1+ (1,0) [0|255] "" FrontDisplayInterfaceModule
 SG_ RDS_MessageData5 : 40|8@1+ (1,0) [0|255] "" FrontDisplayInterfaceModule
 SG_ RDS_MessageData6 : 48|8@1+ (1,0) [0|255] "" FrontDisplayInterfaceModule
 SG_ RDS_MessageData7 : 56|8@1+ (1,0) [0|255] "" FrontDisplayInterfaceModule

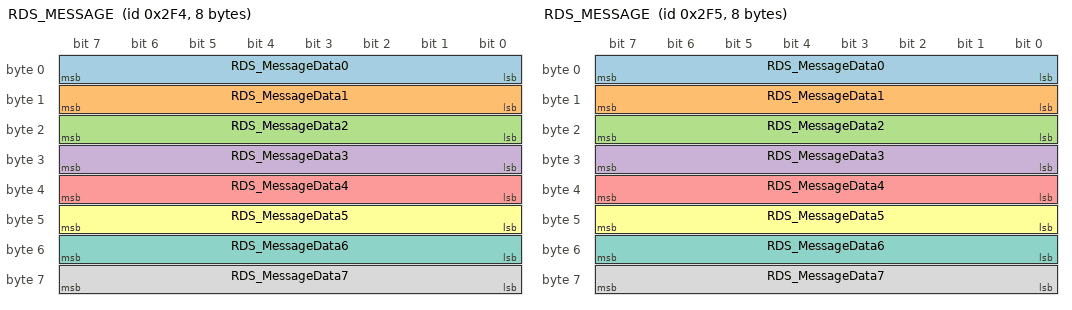
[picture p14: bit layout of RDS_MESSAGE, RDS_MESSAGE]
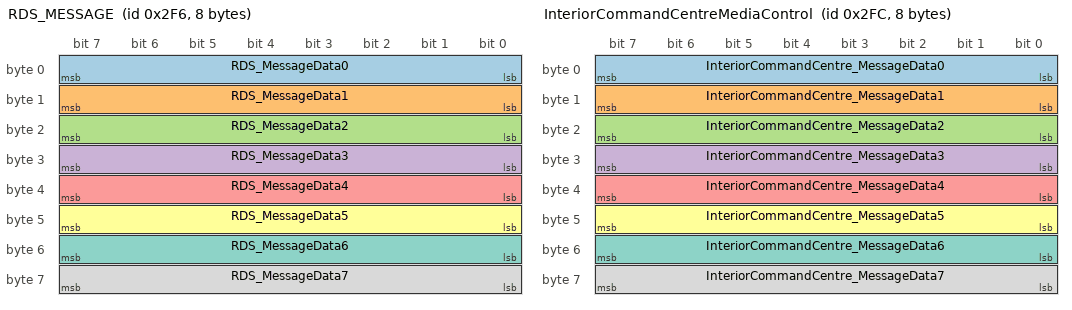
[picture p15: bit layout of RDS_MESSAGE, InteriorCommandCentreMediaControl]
BO_ 758 RDS_MESSAGE: 8 AudioControlModule
 SG_ RDS_MessageData0 : 0|8@1+ (1,0) [0|255] "" FrontDisplayInterfaceModule
 SG_ RDS_MessageData1 : 8|8@1+ (1,0) [0|255] "" FrontDisplayInterfaceModule
 SG_ RDS_MessageData2 : 16|8@1+ (1,0) [0|255] "" FrontDisplayInterfaceModule
 SG_ RDS_MessageData3 : 24|8@1+ (1,0) [0|255] "" FrontDisplayInterfaceModule
 SG_ RDS_MessageData4 : 32|8@1+ (1,0) [0|255] "" FrontDisplayInterfaceModule
 SG_ RDS_MessageData5 : 40|8@1+ (1,0) [0|255] "" FrontDisplayInterfaceModule
 SG_ RDS_MessageData6 : 48|8@1+ (1,0) [0|255] "" FrontDisplayInterfaceModule
 SG_ RDS_MessageData7 : 56|8@1+ (1,0) [0|255] "" FrontDisplayInterfaceModule

BO_ 761 CdMp3Data: 8 FrontDisplayInterfaceModule

BO_ 764 InteriorCommandCentreMediaControl: 8 FrontDisplayInterfaceModule
 SG_ InteriorCommandCentre_MessageData0 : 0|8@1+ (1,0) [0|255] "" FrontDisplayInterfaceModule
 SG_ InteriorCommandCentre_MessageData1 : 8|8@1+ (1,0) [0|255] "" FrontDisplayInterfaceModule
 SG_ InteriorCommandCentre_MessageData2 : 16|8@1+ (1,0) [0|255] "" FrontDisplayInterfaceModule
 SG_ InteriorCommandCentre_MessageData3 : 24|8@1+ (1,0) [0|255] "" FrontDisplayInterfaceModule
 SG_ InteriorCommandCentre_MessageData4 : 32|8@1+ (1,0) [0|255] "" FrontDisplayInterfaceModule
 SG_ InteriorCommandCentre_MessageData5 : 40|8@1+ (1,0) [0|255] "" FrontDisplayInterfaceModule
 SG_ InteriorCommandCentre_MessageData6 : 48|8@1+ (1,0) [0|255] "" FrontDisplayInterfaceModule
 SG_ InteriorCommandCentre_MessageData7 : 56|8@1+ (1,0) [0|255] "" FrontDisplayInterfaceModule

BO_ 775 ICC_MSG_1: 8 Vector__XXX
 SG_ Reset_Trip_Timer : 32|1@0+ (1,0) [0|0] "" Vector__XXX
 SG_ Reset_Avg_Fuel : 33|1@0+ (1,0) [0|0] "" Vector__XXX
 SG_ Reset_Avg_Speed : 35|1@0+ (1,0) [0|0] "" Vector__XXX
 SG_ Overspeed_Down : 36|1@0+ (1,0) [0|0] "" Vector__XXX
 SG_ Overspeed_Up : 37|1@0+ (1,0) [0|0] "" Vector__XXX
 SG_ M_Overspeed_On : 38|1@0+ (1,0) [0|0] "" Vector__XXX
 SG_ Overspeed_Active_Adjust : 39|1@0+ (1,0) [0|0] "" Vector__XXX
 SG_ Blower_Position : 55|8@0+ (1,0) [0|0] "" Vector__XXX
 SG_ Temperature_Position : 47|8@0+ (1,0) [0|0] "" Vector__XXX
 SG_ Diff_Lock_Switch : 27|1@0+ (1,0) [0|0] "" Vector__XXX
 SG_ Traction_VDC_Switch : 28|1@0+ (1,0) [0|0] "" Vector__XXX
 SG_ Driver_Temp_Down_Switch : 22|1@0+ (1,0) [0|0] "" Vector__XXX
 SG_ Driver_Temp_Up_Switch : 23|1@0+ (1,0) [0|0] "" Vector__XXX
 SG_ Pass_Temp_Down_Switch : 8|1@0+ (1,0) [0|0] "" Vector__XXX
 SG_ Pass_Temp_Up_Switch : 9|1@0+ (1,0) [0|0] "" Vector__XXX
 SG_ Fan_Spd_Down_Switch : 10|1@0+ (1,0) [0|0] "" Vector__XXX
 SG_ Fan_Spd_Up_Switch : 11|1@0+ (1,0) [0|0] "" Vector__XXX
 SG_ Climate_Ctrl_Off_Switch : 12|1@0+ (1,0) [0|0] "" Vector__XXX
 SG_ Auto_ACC_On_Switch : 13|1@0+ (1,0) [0|0] "" Vector__XXX
 SG_ Air_Dist_Down_Switch : 14|1@0+ (1,0) [0|0] "" Vector__XXX
 SG_ Air_Dist_Up_Switch : 15|1@0+ (1,0) [0|0] "" Vector__XXX
 SG_ Screen_Floor_Switch : 0|1@0+ (1,0) [0|0] "" Vector__XXX
 SG_ Screen_Switch : 1|1@0+ (1,0) [0|0] "" Vector__XXX
 SG_ Face_Floor_Switch : 2|1@0+ (1,0) [0|0] "" Vector__XXX
 SG_ Floor_Switch : 3|1@0+ (1,0) [0|0] "" Vector__XXX
 SG_ Face_Switch : 4|1@0+ (1,0) [0|0] "" Vector__XXX
 SG_ Recirc_Switch : 6|1@0+ (1,0) [0|0] "" Vector__XXX
 SG_ AC_Switch : 7|1@0+ (1,0) [0|0] "" Vector__XXX
 SG_ InteriorCommandCentreBem_MessageData0 : 0|8@1+ (1,0) [0|255] "" BodyElectricModule
 SG_ InteriorCommandCentreBem_MessageData1 : 8|8@1+ (1,0) [0|255] "" BodyElectricModule
 SG_ InteriorCommandCentreBem_MessageData2 : 16|8@1+ (1,0) [0|255] "" BodyElectricModule
 SG_ InteriorCommandCentreBem_MessageData3 : 24|8@1+ (1,0) [0|255] "" BodyElectricModule
 SG_ InteriorCommandCentreBem_MessageData4 : 32|8@1+ (1,0) [0|255] "" BodyElectricModule
 SG_ InteriorCommandCentreBem_MessageData5 : 40|8@1+ (1,0) [0|255] "" BodyElectricModule
 SG_ InteriorCommandCentreBem_MessageData6 : 48|8@1+ (1,0) [0|255] "" BodyElectricModule
 SG_ InteriorCommandCentreBem_MessageData7 : 56|8@1+ (1,0) [0|255] "" BodyElectricModule
 SG_ IllumBatsaverRequest_MS_0x307 : 16|8@1+ (1,0) [0|255] "" BodyElectricModule

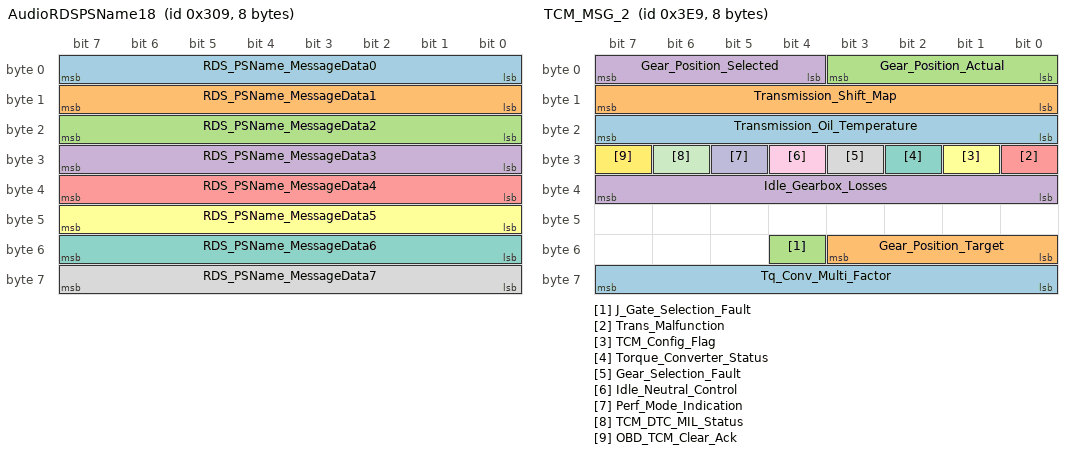
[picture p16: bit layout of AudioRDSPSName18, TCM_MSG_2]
BO_ 777 AudioRDSPSName18: 8 AudioControlModule
 SG_ RDS_PSName_MessageData0 : 0|8@1+ (1,0) [0|255] "" FrontDisplayInterfaceModule
 SG_ RDS_PSName_MessageData1 : 8|8@1+ (1,0) [0|255] "" FrontDisplayInterfaceModule
 SG_ RDS_PSName_MessageData2 : 16|8@1+ (1,0) [0|255] "" FrontDisplayInterfaceModule
 SG_ RDS_PSName_MessageData3 : 24|8@1+ (1,0) [0|255] "" FrontDisplayInterfaceModule
 SG_ RDS_PSName_MessageData4 : 32|8@1+ (1,0) [0|255] "" FrontDisplayInterfaceModule
 SG_ RDS_PSName_MessageData5 : 40|8@1+ (1,0) [0|255] "" FrontDisplayInterfaceModule
 SG_ RDS_PSName_MessageData6 : 48|8@1+ (1,0) [0|255] "" FrontDisplayInterfaceModule
 SG_ RDS_PSName_MessageData7 : 56|8@1+ (1,0) [0|255] "" FrontDisplayInterfaceModule

BO_ 779 Unknown: 8 BodyElectricModule
 SG_ CCNTABS : 46|8@1+ (1,0) [0|0] "" Vector__XXX

BO_ 781 CD_TRACK_TYPE_PLAYING: 8 AudioControlModule
 SG_ CD_PlayingNow : 16|8@1+ (1,0) [0|0] "" FrontDisplayInterfaceModule
 SG_ CD_TrackNumber : 8|8@1+ (1,0) [0|0] "" FrontDisplayInterfaceModule
 SG_ CD_Type : 0|8@1+ (1,0) [0|0] "" FrontDisplayInterfaceModule

BO_ 783 Unknown: 8 BodyElectricModule

BO_ 785 BeltMinderStatus: 8 BodyElectricModule
 SG_ RearBeltMinderStatus : 0|8@1+ (1,0) [0|0] "" BodyElectricModule
 SG_ SeatbeltIndicatorState : 48|8@1+ (1,0) [0|0] "" BodyElectricModule
 SG_ SeatBeltStatusFrontLeft : 32|8@1+ (1,0) [0|0] "" BodyElectricModule
 SG_ SeatBeltStatusFrontRight : 0|8@1+ (1,0) [0|0] "" BodyElectricModule
 SG_ SeatBeltStatusRearLeft : 16|8@1+ (1,0) [0|0] "" BodyElectricModule
 SG_ SeatBeltStatusRearRight : 16|8@1+ (1,0) [0|0] "" BodyElectricModule

BO_ 787 IntActTemp: 8 FrontDisplayInterfaceModule
 SG_ InteriorActualTemperature : 0|8@1+ (0.166667,0) [0|255] "Degrees_C" HvacIntegratedModule

BO_ 789 MenuOptionsICC: 8 FrontDisplayInterfaceModule
 SG_ CycleLockSetting : 0|8@1+ (1,0) [0|255] "" BodyElectricModule
 SG_ Ignition : 16|8@1+ (1,0) [0|0] "" BodyElectricModule
 SG_ FollowMeHomeLighting : 24|8@1+ (0.1,0) [0|255] "" BodyElectricModule
 SG_ InteriorLightStatus : 0|8@1+ (1,0) [0|0] "" FrontDisplayInterfaceModule
 SG_ CabLightSetting : 8|8@1+ (1,0) [0|255] "" FrontDisplayInterfaceModule
 SG_ IgnitionState : 8|8@1+ (1,0) [0|0] "" BodyElectricModule
 SG_ AutoHeadlightAdjustment : 32|8@1+ (1,0) [0|255] "" BodyElectricModule

BO_ 791 VehicleIdentificationNumber: 8 BodyElectricModule
 SG_ VIN : 0|63@1+ (1,0) [0|0] "" AudioControlModule

BO_ 816 ParkBrakeOn_MS: 8 InstrumentCluster

BO_ 829 Unknown: 8 AudioControlModule

BO_ 832 CLU_MSG_2: 8 Vector__XXX
 SG_ FuelCutOffStatus : 8|8@1+ (1,0) [0|255] "" InstrumentCluster
 SG_ SeatBeltWarningRequest : 8|8@1+ (1,0) [0|255] "" InstrumentCluster
 SG_ SeatBeltChineRequest : 8|8@1+ (1,0) [0|255] "" InstrumentCluster
 SG_ AirBagFault : 8|8@1+ (1,0) [0|255] "" InstrumentCluster
 SG_ AirBagWarningLight : 8|8@1+ (1,0) [0|255] "" InstrumentCluster

BO_ 848 CLU_MSG_3: 8 Vector__XXX

BO_ 851 HIM_MSG_1: 8 Vector__XXX
 SG_ Blower_Speed : 59|4@0+ (1,0) [0|0] "" Vector__XXX
 SG_ AC_Max_Request : 60|1@0+ (1,0) [0|0] "" Vector__XXX
 SG_ AC_Clutch_Request : 63|1@0+ (1,0) [0|0] "" Vector__XXX
 SG_ Blower_Voltage : 55|8@0+ (0.1,0) [0|0] "V" Vector__XXX
 SG_ Evap_Temp : 47|8@0+ (0.33333333333333,-30) [0|0] "C" Vector__XXX
 SG_ Ambient_Temp : 39|8@0+ (1,0) [0|0] "" Vector__XXX
 SG_ Driver_Temp : 31|8@0+ (1,0) [0|0] "" Vector__XXX
 SG_ Passenger_Temp : 23|8@0+ (1,0) [0|0] "" Vector__XXX
 SG_ Off_Seg : 8|1@0+ (1,0) [0|0] "" Vector__XXX
 SG_ Semi_Seg : 9|1@0+ (1,0) [0|0] "" Vector__XXX
 SG_ Auto_Seg : 10|1@0+ (1,0) [0|0] "" Vector__XXX
 SG_ Driver_Seg : 11|1@0+ (1,0) [0|0] "" Vector__XXX
 SG_ Pass_Seg : 12|1@0+ (1,0) [0|0] "" Vector__XXX
 SG_ Driver_Temp_Seg : 13|1@0+ (1,0) [0|0] "" Vector__XXX
 SG_ Pass_Temp_Seg : 14|1@0+ (1,0) [0|0] "" Vector__XXX
 SG_ OS_Temp_Seg : 15|1@0+ (1,0) [0|0] "" Vector__XXX
 SG_ Fanblade_Seg : 0|1@0+ (1,0) [0|0] "" Vector__XXX
 SG_ Person_Seg : 1|1@0+ (1,0) [0|0] "" Vector__XXX
 SG_ Screen_Seg : 2|1@0+ (1,0) [0|0] "" Vector__XXX
 SG_ Floor_Seg : 3|1@0+ (1,0) [0|0] "" Vector__XXX
 SG_ Face_Seg : 4|1@0+ (1,0) [0|0] "" Vector__XXX
 SG_ Fresh_Seg : 5|1@0+ (1,0) [0|0] "" Vector__XXX
 SG_ Recirc_Seg : 6|1@0+ (1,0) [0|0] "" Vector__XXX
 SG_ AC_Seg : 7|1@0+ (1,0) [0|0] "" Vector__XXX
 SG_ VentStatus_B0 : 0|8@1+ (1,0) [0|255] "" Vector__XXX
 SG_ PassengerTargetTemp_B1 : 8|8@1+ (1,0) [0|255] "" Vector__XXX
 SG_ PassengerTemp_B2 : 16|8@1+ (1,0) [0|255] "" Vector__XXX
 SG_ DriverTargetTemp_B3 : 24|8@1+ (1,0) [0|255] "" Vector__XXX
 SG_ DriverTemp_B4 : 32|8@1+ (1,0) [0|255] "" Vector__XXX
 SG_ ExteriorAmbientTemp_B5 : 40|8@1+ (1,0) [0|255] "" Vector__XXX
 SG_ FanSpeedActual_B6 : 48|8@1+ (1,0) [0|255] "" Vector__XXX
 SG_ FanSpeedTarget_B7 : 56|8@1+ (1,0) [0|255] "" Vector__XXX

BO_ 864 ReverseParkingSenseSystem: 8 ParkingAidModule
 SG_ PRK_BRAKE : 16|8@1+ (1,0) [0|0] "" ParkingAidModule
 SG_ RC_DIST : 8|8@1+ (1,0) [0|0] "" ParkingAidModule
 SG_ REAR_SENS : 58|8@1+ (1,0) [0|0] "" ParkingAidModule
 SG_ REAR_TONE : 40|8@1+ (1,0) [0|0] "" ParkingAidModule
 SG_ VBAT : 0|8@1+ (1,0) [0|0] "" ParkingAidModule
 SG_ TRAILINS : 0|8@1+ (1,0) [0|0] "" ParkingAidModule
 SG_ TRANSRV : 0|8@1+ (1,0) [0|0] "" ParkingAidModule
 SG_ SYS_OZ : 16|8@1+ (1,0) [0|0] "" ParkingAidModule
 SG_ RM_DIST : 24|8@1+ (1,0) [0|0] "" ParkingAidModule
 SG_ PARK_SYS : 0|8@1+ (1,0) [0|0] "" ParkingAidModule

BO_ 869 ReverseGearEngaged: 8 BodyElectricModule
 SG_ ReverseGearSelected : 0|8@1+ (1,0) [0|0] "" ParkingAidModule

BO_ 1001 TCM_MSG_2: 8 Vector__XXX
 SG_ Tq_Conv_Multi_Factor : 63|8@0+ (0.01,0.01) [0|0] "ratio" Vector__XXX
 SG_ Gear_Position_Target : 51|4@0+ (1,0) [0|0] "" Vector__XXX
 SG_ J_Gate_Selection_Fault : 52|1@0+ (1,0) [0|0] "" Vector__XXX
 SG_ Idle_Gearbox_Losses : 39|8@0+ (1,0) [0|0] "Nm" Vector__XXX
 SG_ Trans_Malfunction : 24|1@0+ (1,0) [0|0] "" Vector__XXX
 SG_ TCM_Config_Flag : 25|1@0+ (1,0) [0|0] "" Vector__XXX
 SG_ Torque_Converter_Status : 26|1@0+ (1,0) [0|0] "" Vector__XXX
 SG_ Gear_Selection_Fault : 27|1@0+ (1,0) [0|0] "" Vector__XXX
 SG_ Idle_Neutral_Control : 28|1@0+ (1,0) [0|0] "" Vector__XXX
 SG_ Perf_Mode_Indication : 29|1@0+ (1,0) [0|0] "" Vector__XXX
 SG_ TCM_DTC_MIL_Status : 30|1@0+ (1,0) [0|0] "" Vector__XXX
 SG_ OBD_TCM_Clear_Ack : 31|1@0+ (1,0) [0|0] "" Vector__XXX
 SG_ Transmission_Oil_Temperature : 23|8@0+ (1,-40) [0|0] "C" Vector__XXX
 SG_ Transmission_Shift_Map : 15|8@0+ (1,0) [0|0] "" Vector__XXX
 SG_ Gear_Position_Actual : 3|4@0+ (1,0) [0|0] "" Vector__XXX
 SG_ Gear_Position_Selected : 7|4@0+ (1,0) [0|0] "" Vector__XXX

BO_ 1027 BEM_MSG_1: 8 Vector__XXX
 SG_ Sun_Load_Passenger : 39|8@0+ (1,0) [0|0] "C" Vector__XXX
 SG_ Sun_Load_Driver : 31|8@0+ (1,0) [0|0] "C" Vector__XXX
 SG_ Cabin_Temperature : 23|8@0+ (0.5,-40) [0|0] "C" Vector__XXX
 SG_ Priority_Key_1 : 9|1@0+ (1,0) [0|0] "" Vector__XXX
 SG_ Priority_Key_2 : 10|1@0+ (1,0) [0|0] "" Vector__XXX
 SG_ Lights_On_Warning : 14|1@0+ (1,0) [0|0] "" Vector__XXX
 SG_ Trailer_Connected : 0|1@0+ (1,0) [0|0] "" Vector__XXX
 SG_ Accessories_Switch : 1|1@0+ (1,0) [0|0] "" Vector__XXX
 SG_ Rear_Demist : 2|1@0+ (1,0) [0|0] "" Vector__XXX
 SG_ Rear_Door_Ajar : 3|1@0+ (1,0) [0|0] "" Vector__XXX
 SG_ LR_Door_Ajar : 4|1@0+ (1,0) [0|0] "" Vector__XXX
 SG_ RR_Door_Ajar : 5|1@0+ (1,0) [0|0] "" Vector__XXX
 SG_ LF_Door_Ajar : 6|1@0+ (1,0) [0|0] "" Vector__XXX
 SG_ RF_Door_Ajar : 7|1@0+ (1,0) [0|0] "" Vector__XXX
 SG_ DoorStatus_Accessories_TrailerConnected_B0 : 0|8@1+ (1,0) [0|255] "" Vector__XXX
 SG_ PriorityKey_LightsOn_RearDemist_B1 : 8|8@1+ (1,0) [0|255] "" Vector__XXX
 SG_ CabinTemperature_B2 : 16|8@1+ (1,0) [0|255] "" Vector__XXX
 SG_ SunloadDriver_B3 : 24|8@1+ (1,0) [0|255] "" Vector__XXX
 SG_ SunloadPassenger_B4 : 32|8@1+ (1,0) [0|255] "" Vector__XXX
 SG_ Boot_B5 : 40|8@1+ (1,0) [0|255] "" Vector__XXX
 SG_ Windscreen_Wipers_B6 : 48|8@1+ (1,0) [0|255] "" Vector__XXX
 SG_ Locking_State_B7 : 56|8@1+ (1,0) [0|255] "" Vector__XXX

BO_ 1030 SeatBeltStatus: 8 BodyElectricModule
 SG_ SeatBeltStatusFrontRight : 0|8@1+ (1,0) [0|0] "" InstrumentCluster
 SG_ SeatBeltStatusFrontLeft : 32|8@1+ (1,0) [0|0] "" InstrumentCluster
 SG_ SeatBeltStatusRearLeft : 16|8@1+ (1,0) [0|0] "" InstrumentCluster
 SG_ SeatBeltStatusRearRight : 16|8@1+ (1,0) [0|0] "" InstrumentCluster
 SG_ SeatBeltStatusRearCentre : 16|8@1+ (1,0) [0|0] "" InstrumentCluster
 SG_ IgnitionState : 8|8@1+ (1,0) [0|0] "" BodyElectricModule
 SG_ InteriorLightStatus : 16|8@1+ (1,0) [0|0] "" BodyElectricModule

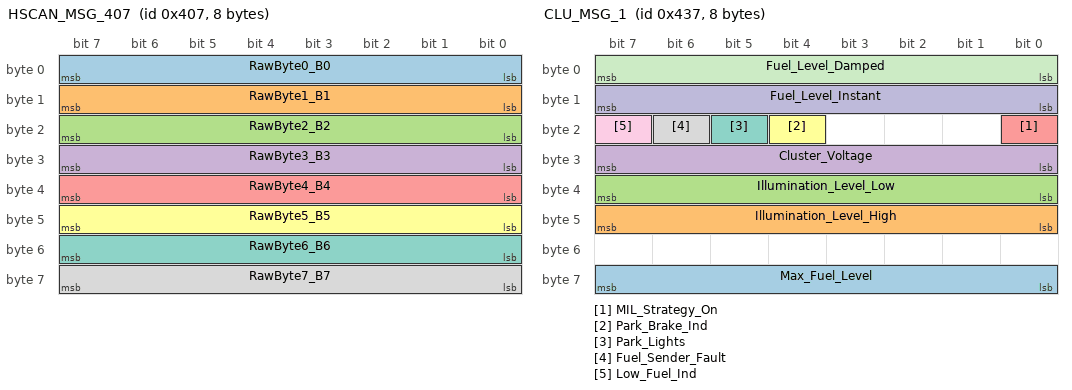
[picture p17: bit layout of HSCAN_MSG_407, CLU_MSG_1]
BO_ 1031 HSCAN_MSG_407: 8 Body_Electronic_Module
 SG_ RawByte0_B0 : 0|8@1+ (1,0) [0|255] "" Vector__XXX
 SG_ RawByte1_B1 : 8|8@1+ (1,0) [0|255] "" Vector__XXX
 SG_ RawByte2_B2 : 16|8@1+ (1,0) [0|255] "" Vector__XXX
 SG_ RawByte3_B3 : 24|8@1+ (1,0) [0|255] "" Vector__XXX
 SG_ RawByte4_B4 : 32|8@1+ (1,0) [0|255] "" Vector__XXX
 SG_ RawByte5_B5 : 40|8@1+ (1,0) [0|255] "" Vector__XXX
 SG_ RawByte6_B6 : 48|8@1+ (1,0) [0|255] "" Vector__XXX
 SG_ RawByte7_B7 : 56|8@1+ (1,0) [0|255] "" Vector__XXX

BO_ 1033 AdditionalBodyInformation: 8 BodyElectricModule

BO_ 1061 PCM_MSG_15: 8 Vector__XXX
 SG_ Fuel_Level : 47|8@0+ (1,0) [0|0] "" Vector__XXX
 SG_ Inst_Fuel_Consumption : 55|16@0+ (1,0) [0|0] "" Vector__XXX
 SG_ Cruise_Set : 1|1@0+ (1,0) [0|0] "" Vector__XXX
 SG_ Cruise_Enable : 0|1@0+ (1,0) [0|0] "" Vector__XXX
 SG_ Cruise_Set_Speed : 15|16@0+ (1,0) [0|0] "km/h" Vector__XXX
 SG_ Boost_Pressure : 31|16@0+ (1,0) [0|0] "kPa" Vector__XXX

BO_ 1063 PCM_MSG_8: 8 Vector__XXX
 SG_ Immobiliser_Ind : 53|2@0+ (1,0) [0|0] "" Vector__XXX
 SG_ Fuel_Pulse : 63|8@0+ (7.88519E-005,0) [0|0] "L" Vector__XXX
 SG_ DTC_Logging : 48|1@0+ (1,0) [0|0] "" Vector__XXX
 SG_ AC_Shed_Load : 49|1@0+ (1,0) [0|0] "" Vector__XXX
 SG_ MIL_Ind : 51|2@0+ (1,0) [0|0] "" Vector__XXX
 SG_ ETC_Warning_Ind : 55|2@0+ (1,0) [0|0] "" Vector__XXX
 SG_ AC_Compressor_State : 40|1@0+ (1,0) [0|0] "" Vector__XXX
 SG_ Idle_Mode : 41|1@0+ (1,0) [0|0] "" Vector__XXX
 SG_ Diff_Lock_Ind : 42|1@0+ (1,0) [0|0] "" Vector__XXX
 SG_ Engine_Overheat_Warn_Ind : 43|1@0+ (1,0) [0|0] "" Vector__XXX
 SG_ Oil_Pressure_Warn_Ind : 44|1@0+ (1,0) [0|0] "" Vector__XXX
 SG_ Alternator_Fail_Ind : 45|1@0+ (1,0) [0|0] "" Vector__XXX
 SG_ Cruise_Set_Ind : 46|1@0+ (1,0) [0|0] "" Vector__XXX
 SG_ Oil_Low_Ind : 47|1@0+ (1,0) [0|0] "" Vector__XXX
 SG_ Odometer_Count : 39|8@0+ (0.000201167,0) [0|0] "km" Vector__XXX
 SG_ PCM_Battery_Voltage : 31|8@0+ (0.1,0) [0|0] "V" Vector__XXX
 SG_ AC_Pressure : 11|12@0+ (1,-100) [0|0] "kPa" Vector__XXX
 SG_ Eng_Oil_Pressure : 15|4@0+ (1,0) [0|0] "" Vector__XXX
 SG_ Coolant_Temperature : 7|8@0+ (1,-40) [0|0] "C" Vector__XXX

BO_ 1079 CLU_MSG_1: 8 Vector__XXX
 SG_ Max_Fuel_Level : 63|8@0+ (0.51,0) [0|0] "L" Vector__XXX
 SG_ Illumination_Level_High : 47|8@0+ (1,0) [0|0] "" Vector__XXX
 SG_ Illumination_Level_Low : 39|8@0+ (1,0) [0|0] "" Vector__XXX
 SG_ Cluster_Voltage : 31|8@0+ (0.1,0) [0|0] "V" Vector__XXX
 SG_ MIL_Strategy_On : 16|1@0+ (1,0) [0|0] "" Vector__XXX
 SG_ Park_Brake_Ind : 20|1@0+ (1,0) [0|0] "" Vector__XXX
 SG_ Park_Lights : 21|1@0+ (1,0) [0|0] "" Vector__XXX
 SG_ Fuel_Sender_Fault : 22|1@0+ (1,0) [0|0] "" Vector__XXX
 SG_ Low_Fuel_Ind : 23|1@0+ (1,0) [0|0] "" Vector__XXX
 SG_ Fuel_Level_Instant : 15|8@0+ (0.51,0) [0|0] "L" Vector__XXX
 SG_ Fuel_Level_Damped : 7|8@0+ (0.51,0) [0|0] "L" Vector__XXX

BO_ 1101 PCM_MSG_9: 8 Vector__XXX
 SG_ Baro_Pressure : 63|8@0+ (0.5,0) [0|0] "%" Vector__XXX
 SG_ Eng_Oil_Temperature : 55|8@0+ (1,-40) [0|0] "C" Vector__XXX
 SG_ Coolant_Temperature : 39|12@0+ (0.1,-40) [0|0] "C" Vector__XXX
 SG_ MIL_Status : 14|1@0+ (1,0) [0|0] "" Vector__XXX
 SG_ CylinderHeadTemp4 : 32|8@1+ (0.5,0) [0|255] "Degrees_C" PowertrainControlModule
 SG_ CylinderHeadTemp5 : 40|8@1+ (0.5,0) [0|255] "Degrees_C" PowertrainControlModule
 SG_ EngineOilTemperature6 : 48|8@1+ (0.5,0) [0|255] "Degrees_C" InstrumentCluster
 SG_ AtmosphericAbsolutePressure7 : 56|8@1+ (0.5,0) [0|255] "KPa" PowertrainControlModule

BO_ 1107 ODO_MSG_1: 8 Vector__XXX
 SG_ Odometer : 39|24@0+ (1,0) [0|0] "km" Vector__XXX
 SG_ RawByte0_B0 : 0|8@1+ (1,0) [0|255] "" Vector__XXX
 SG_ RawByte1_B1 : 8|8@1+ (1,0) [0|255] "" Vector__XXX
 SG_ RawByte2_B2 : 16|8@1+ (1,0) [0|255] "" Vector__XXX
 SG_ RawByte3_B3 : 24|8@1+ (1,0) [0|255] "" Vector__XXX
 SG_ RawByte4_B4 : 32|8@1+ (1,0) [0|255] "" Vector__XXX
 SG_ RawByte5_B5 : 40|8@1+ (1,0) [0|255] "" Vector__XXX
 SG_ RawByte6_B6 : 48|8@1+ (1,0) [0|255] "" Vector__XXX
 SG_ RawByte7_B7 : 56|8@1+ (1,0) [0|255] "" Vector__XXX

BO_ 1108 MessageLabel: 8 Vector__XXX

BO_ 1200 TCS_MSG_1: 8 Vector__XXX
 SG_ Wheel_Speed_RR : 55|16@0+ (0.01,0) [0|0] "km/h" Vector__XXX
 SG_ Wheel_Speed_RL : 39|16@0+ (0.01,0) [0|0] "km/h" Vector__XXX
 SG_ Wheel_Speed_FR : 23|16@0+ (0.01,0) [0|0] "km/h" Vector__XXX
 SG_ Wheel_Speed_FL : 7|16@0+ (0.01,0) [0|0] "km/h" Vector__XXX

BO_ 1216 PCM_MSG_10: 8 Vector__XXX
 SG_ Odometer : 7|24@0+ (0.1,0) [0|0] "Km" Vector__XXX

BO_ 1280 CLU_MSG_4: 8 Vector__XXX
 SG_ Travel_Time : 55|16@0+ (1,0) [0|0] "min" Vector__XXX
 SG_ Average_Economy_Mode : 15|8@0+ (1,0) [0|0] "" Vector__XXX
 SG_ Average_Economy : 23|8@0+ (1,0) [0|0] "" Vector__XXX
 SG_ Average_Speed : 7|8@0+ (1,0) [0|0] "km/h" Vector__XXX

BO_ 1281 MessageLabel: 8 Vector__XXX

BO_ 1292 ACM_KeepAlive: 8 AudioControlModule
 SG_ KeepAliveACM : 0|63@1+ (0,0) [0|0] "" InstrumentCluster

BO_ 1297 Unknown: 8 Vector__XXX

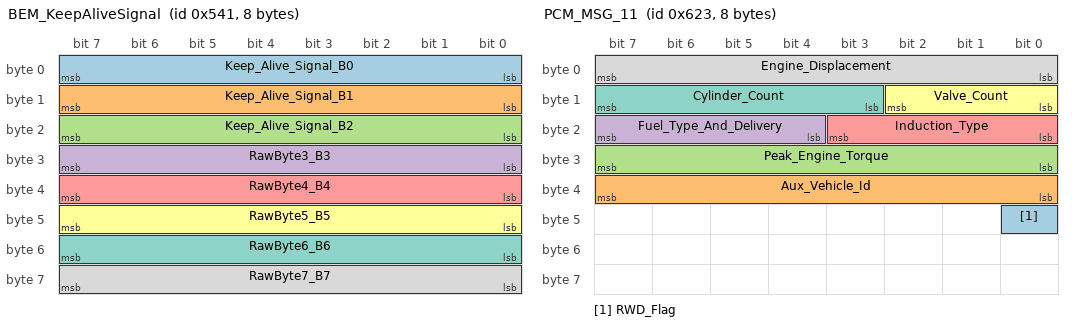
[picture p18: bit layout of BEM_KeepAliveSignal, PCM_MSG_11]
BO_ 1345 BEM_KeepAliveSignal: 8 Body_Electronic_Module
 SG_ Keep_Alive_Signal_B0 : 0|8@1+ (1,0) [0|255] "" Vector__XXX
 SG_ Keep_Alive_Signal_B1 : 8|8@1+ (1,0) [0|255] "" Vector__XXX
 SG_ Keep_Alive_Signal_B2 : 16|8@1+ (1,0) [0|255] "" Vector__XXX
 SG_ RawByte3_B3 : 24|8@1+ (1,0) [0|255] "" Vector__XXX
 SG_ RawByte4_B4 : 32|8@1+ (1,0) [0|255] "" Vector__XXX
 SG_ RawByte5_B5 : 40|8@1+ (1,0) [0|255] "" Vector__XXX
 SG_ RawByte6_B6 : 48|8@1+ (1,0) [0|255] "" Vector__XXX
 SG_ RawByte7_B7 : 56|8@1+ (1,0) [0|255] "" Vector__XXX

BO_ 1363 CLU_MSG_5: 8 Vector__XXX
 SG_ Odometer : 39|24@0+ (1,0) [0|0] "km" Vector__XXX
 SG_ Inst_Econ : 31|8@0+ (0.1,0) [0|0] "" Vector__XXX
 SG_ Inst_Econ_Mode : 23|1@0+ (1,0) [0|0] "" Vector__XXX
 SG_ Fuel_Range : 7|16@0+ (1,0) [0|0] "km" Vector__XXX

BO_ 1365 Unknown: 8 InstrumentCluster

BO_ 1372 FDIM_KeepAlive: 8 FrontDisplayInterfaceModule
 SG_ KeepAliveFDIM : 0|8@1+ (0.1,0) [0|0] "" InstrumentCluster

BO_ 1571 PCM_MSG_11: 8 Vector__XXX
 SG_ RWD_Flag : 40|1@0+ (1,0) [0|0] "" Vector__XXX
 SG_ Aux_Vehicle_Id : 39|8@0+ (1,0) [0|0] "" Vector__XXX
 SG_ Peak_Engine_Torque : 31|8@0+ (4,0) [0|0] "Nm" Vector__XXX
 SG_ Fuel_Type_And_Delivery : 23|4@0+ (1,0) [0|0] "" Vector__XXX
 SG_ Induction_Type : 19|4@0+ (1,0) [0|0] "" Vector__XXX
 SG_ Valve_Count : 10|3@0+ (1,0) [0|0] "" Vector__XXX
 SG_ Cylinder_Count : 15|5@0+ (1,0) [0|0] "" Vector__XXX
 SG_ Engine_Displacement : 7|8@0+ (0.1,0) [0|0] "L" Vector__XXX

BO_ 1600 PCM_MSG_12: 8 Vector__XXX
 SG_ RWD_Flag : 6|1@0+ (1,0) [0|0] "" Vector__XXX
 SG_ Forward_Gear_Count : 51|4@0+ (1,0) [0|0] "" Vector__XXX
 SG_ Transmission_Configuration : 54|1@0+ (1,0) [0|0] "" Vector__XXX
 SG_ Base_Torque_Split : 47|8@0+ (0.0078125,0) [0|0] "ratio" Vector__XXX
 SG_ Fraction_Portion_Ratio : 15|16@0+ (0.00012207,0) [0|0] "ratio" Vector__XXX
 SG_ Axle_Ratio : 31|16@0+ (0.00012207,0) [0|0] "ratio" Vector__XXX
 SG_ AutoTransTCMControl_Flag : 2|1@0+ (1,0) [0|0] "" Vector__XXX
 SG_ AutoTransPCMControl_Flag : 3|1@0+ (1,0) [0|0] "" Vector__XXX
 SG_ ManualTrans_Flag : 4|1@0+ (1,0) [0|0] "" Vector__XXX
 SG_ AWD_Flag : 5|1@0+ (1,0) [0|0] "" Vector__XXX
 SG_ FWD_Flag : 7|1@0+ (1,0) [0|0] "" Vector__XXX
 SG_ ManualTransFlag_B0 : 0|8@1+ (1,0) [0|255] "" Vector__XXX
 SG_ RawByte1_B1 : 8|8@1+ (1,0) [0|255] "" Vector__XXX
 SG_ RawByte2_B2 : 16|8@1+ (1,0) [0|255] "" Vector__XXX
 SG_ RawByte3_B3 : 24|8@1+ (1,0) [0|255] "" Vector__XXX
 SG_ RawByte4_B4 : 32|8@1+ (1,0) [0|255] "" Vector__XXX
 SG_ RawByte5_B5 : 40|8@1+ (1,0) [0|255] "" Vector__XXX
 SG_ RawByte6_B6 : 48|8@1+ (1,0) [0|255] "" Vector__XXX
 SG_ RawByte7_B7 : 56|8@1+ (1,0) [0|255] "" Vector__XXX

BO_ 1616 PCM_MSG_13: 8 Vector__XXX

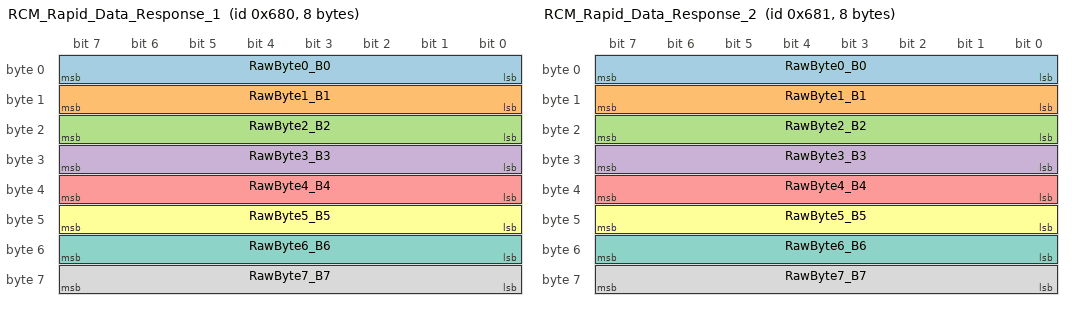
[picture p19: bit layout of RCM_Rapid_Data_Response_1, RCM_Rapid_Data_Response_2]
BO_ 1664 RCM_Rapid_Data_Response_1: 8 Restraints_Control_Module
 SG_ RawByte0_B0 : 0|8@1+ (1,0) [0|255] "" Vector__XXX
 SG_ RawByte1_B1 : 8|8@1+ (1,0) [0|255] "" Vector__XXX
 SG_ RawByte2_B2 : 16|8@1+ (1,0) [0|255] "" Vector__XXX
 SG_ RawByte3_B3 : 24|8@1+ (1,0) [0|255] "" Vector__XXX
 SG_ RawByte4_B4 : 32|8@1+ (1,0) [0|255] "" Vector__XXX
 SG_ RawByte5_B5 : 40|8@1+ (1,0) [0|255] "" Vector__XXX
 SG_ RawByte6_B6 : 48|8@1+ (1,0) [0|255] "" Vector__XXX
 SG_ RawByte7_B7 : 56|8@1+ (1,0) [0|255] "" Vector__XXX

BO_ 1665 RCM_Rapid_Data_Response_2: 8 Restraints_Control_Module
 SG_ RawByte0_B0 : 0|8@1+ (1,0) [0|255] "" Vector__XXX
 SG_ RawByte1_B1 : 8|8@1+ (1,0) [0|255] "" Vector__XXX
 SG_ RawByte2_B2 : 16|8@1+ (1,0) [0|255] "" Vector__XXX
 SG_ RawByte3_B3 : 24|8@1+ (1,0) [0|255] "" Vector__XXX
 SG_ RawByte4_B4 : 32|8@1+ (1,0) [0|255] "" Vector__XXX
 SG_ RawByte5_B5 : 40|8@1+ (1,0) [0|255] "" Vector__XXX
 SG_ RawByte6_B6 : 48|8@1+ (1,0) [0|255] "" Vector__XXX
 SG_ RawByte7_B7 : 56|8@1+ (1,0) [0|255] "" Vector__XXX

BO_ 1696 PCM_Rapid_Data_Response_1: 8 Powertrain_Control_Module
 SG_ PCM_Live_Data_Stream_B0 : 0|8@1+ (1,0) [0|255] "" Vector__XXX
 SG_ PCM_Live_Data_Stream_B1 : 8|8@1+ (1,0) [0|255] "" Vector__XXX
 SG_ PCM_Live_Data_Stream_B2 : 16|8@1+ (1,0) [0|255] "" Vector__XXX
 SG_ PCM_Live_Data_Stream_B3 : 24|8@1+ (1,0) [0|255] "" Vector__XXX
 SG_ PCM_Live_Data_Stream_B4 : 32|8@1+ (1,0) [0|255] "" Vector__XXX
 SG_ PCM_Live_Data_Stream_B5 : 40|8@1+ (1,0) [0|255] "" Vector__XXX
 SG_ PCM_Live_Data_Stream_B6 : 48|8@1+ (1,0) [0|255] "" Vector__XXX
 SG_ PCM_Live_Data_Stream_B7 : 56|8@1+ (1,0) [0|255] "" Vector__XXX

BO_ 1697 PCM_Rapid_Data_Response_2: 8 Powertrain_Control_Module
 SG_ PCM_Live_Data_Stream_B0 : 0|8@1+ (1,0) [0|255] "" Vector__XXX
 SG_ PCM_Live_Data_Stream_B1 : 8|8@1+ (1,0) [0|255] "" Vector__XXX
 SG_ PCM_Live_Data_Stream_B2 : 16|8@1+ (1,0) [0|255] "" Vector__XXX
 SG_ PCM_Live_Data_Stream_B3 : 24|8@1+ (1,0) [0|255] "" Vector__XXX
 SG_ PCM_Live_Data_Stream_B4 : 32|8@1+ (1,0) [0|255] "" Vector__XXX
 SG_ PCM_Live_Data_Stream_B5 : 40|8@1+ (1,0) [0|255] "" Vector__XXX
 SG_ PCM_Live_Data_Stream_B6 : 48|8@1+ (1,0) [0|255] "" Vector__XXX
 SG_ PCM_Live_Data_Stream_B7 : 56|8@1+ (1,0) [0|255] "" Vector__XXX

BO_ 1698 PCM_Rapid_Data_Response_3: 8 Powertrain_Control_Module
 SG_ PCM_Live_Data_Stream_B0 : 0|8@1+ (1,0) [0|255] "" Vector__XXX
 SG_ PCM_Live_Data_Stream_B1 : 8|8@1+ (1,0) [0|255] "" Vector__XXX
 SG_ PCM_Live_Data_Stream_B2 : 16|8@1+ (1,0) [0|255] "" Vector__XXX
 SG_ PCM_Live_Data_Stream_B3 : 24|8@1+ (1,0) [0|255] "" Vector__XXX
 SG_ PCM_Live_Data_Stream_B4 : 32|8@1+ (1,0) [0|255] "" Vector__XXX
 SG_ PCM_Live_Data_Stream_B5 : 40|8@1+ (1,0) [0|255] "" Vector__XXX
 SG_ PCM_Live_Data_Stream_B6 : 48|8@1+ (1,0) [0|255] "" Vector__XXX
 SG_ PCM_Live_Data_Stream_B7 : 56|8@1+ (1,0) [0|255] "" Vector__XXX

BO_ 1699 PCM_Rapid_Data_Response_4: 8 Powertrain_Control_Module
 SG_ PCM_Live_Data_Stream_B0 : 0|8@1+ (1,0) [0|255] "" Vector__XXX
 SG_ PCM_Live_Data_Stream_B1 : 8|8@1+ (1,0) [0|255] "" Vector__XXX
 SG_ PCM_Live_Data_Stream_B2 : 16|8@1+ (1,0) [0|255] "" Vector__XXX
 SG_ PCM_Live_Data_Stream_B3 : 24|8@1+ (1,0) [0|255] "" Vector__XXX
 SG_ PCM_Live_Data_Stream_B4 : 32|8@1+ (1,0) [0|255] "" Vector__XXX
 SG_ PCM_Live_Data_Stream_B5 : 40|8@1+ (1,0) [0|255] "" Vector__XXX
 SG_ PCM_Live_Data_Stream_B6 : 48|8@1+ (1,0) [0|255] "" Vector__XXX
 SG_ PCM_Live_Data_Stream_B7 : 56|8@1+ (1,0) [0|255] "" Vector__XXX

BO_ 1700 TCM_Rapid_Data_Response_1: 8 Powertrain_Control_Module
 SG_ TCM_Live_Data_Steam_B0 : 0|8@1+ (1,0) [0|255] "" Vector__XXX
 SG_ TCM_Live_Data_Steam_B1 : 8|8@1+ (1,0) [0|255] "" Vector__XXX
 SG_ TCM_Live_Data_Steam_B2 : 16|8@1+ (1,0) [0|255] "" Vector__XXX
 SG_ TCM_Live_Data_Steam_B3 : 24|8@1+ (1,0) [0|255] "" Vector__XXX
 SG_ TCM_Live_Data_Steam_B4 : 32|8@1+ (1,0) [0|255] "" Vector__XXX
 SG_ TCM_Live_Data_Steam_B5 : 40|8@1+ (1,0) [0|255] "" Vector__XXX
 SG_ TCM_Live_Data_Steam_B6 : 48|8@1+ (1,0) [0|255] "" Vector__XXX
 SG_ TCM_Live_Data_Steam_B7 : 56|8@1+ (1,0) [0|255] "" Vector__XXX

BO_ 1701 TCM_Rapid_Data_Response_2: 8 Powertrain_Control_Module
 SG_ TCM_Live_Data_Stream_B0 : 0|8@1+ (1,0) [0|255] "" Vector__XXX
 SG_ TCM_Live_Data_Stream_B1 : 8|8@1+ (1,0) [0|255] "" Vector__XXX
 SG_ TCM_Live_Data_Stream_B2 : 16|8@1+ (1,0) [0|255] "" Vector__XXX
 SG_ TCM_Live_Data_Stream_B3 : 24|8@1+ (1,0) [0|255] "" Vector__XXX
 SG_ TCM_Live_Data_Stream_B4 : 32|8@1+ (1,0) [0|255] "" Vector__XXX
 SG_ TCM_Live_Data_Stream_B5 : 40|8@1+ (1,0) [0|255] "" Vector__XXX
 SG_ TCM_Live_Data_Stream_B6 : 48|8@1+ (1,0) [0|255] "" Vector__XXX
 SG_ TCM_Live_Data_Stream_B7 : 56|8@1+ (1,0) [0|255] "" Vector__XXX

BO_ 1712 ABS_Rapid_Data_Response_1: 8 Antilock_Brake_Module
 SG_ ABS_Live_Data_Stream_B0 : 0|8@1+ (1,0) [0|255] "" Vector__XXX
 SG_ ABS_Live_Data_Stream_B1 : 8|8@1+ (1,0) [0|255] "" Vector__XXX
 SG_ ABS_Live_Data_Stream_B2 : 16|8@1+ (1,0) [0|255] "" Vector__XXX
 SG_ ABS_Live_Data_Stream_B3 : 24|8@1+ (1,0) [0|255] "" Vector__XXX
 SG_ ABS_Live_Data_Stream_B4 : 32|8@1+ (1,0) [0|255] "" Vector__XXX
 SG_ ABS_Live_Data_Stream_B5 : 40|8@1+ (1,0) [0|255] "" Vector__XXX
 SG_ ABS_Live_Data_Stream_B6 : 48|8@1+ (1,0) [0|255] "" Vector__XXX
 SG_ ABS_Live_Data_Stream_B7 : 56|8@1+ (1,0) [0|255] "" Vector__XXX

BO_ 1713 ABS_Rapid_Data_Response_2: 8 Antilock_Brake_Module
 SG_ ABS_Live_Data_Stream_B0 : 0|8@1+ (1,0) [0|255] "" Vector__XXX
 SG_ ABS_Live_Data_Stream_B1 : 8|8@1+ (1,0) [0|255] "" Vector__XXX
 SG_ ABS_Live_Data_Stream_B2 : 16|8@1+ (1,0) [0|255] "" Vector__XXX
 SG_ ABS_Live_Data_Stream_B3 : 24|8@1+ (1,0) [0|255] "" Vector__XXX
 SG_ ABS_Live_Data_Stream_B4 : 32|8@1+ (1,0) [0|255] "" Vector__XXX
 SG_ ABS_Live_Data_Stream_B5 : 40|8@1+ (1,0) [0|255] "" Vector__XXX
 SG_ ABS_Live_Data_Stream_B6 : 48|8@1+ (1,0) [0|255] "" Vector__XXX
 SG_ ABS_Live_Data_Stream_B7 : 56|8@1+ (1,0) [0|255] "" Vector__XXX

BO_ 1782 PCM_MSG_14: 8 Vector__XXX
 SG_ Immobiliser_Byte_7 : 63|8@0+ (1,0) [0|0] "" Vector__XXX
 SG_ Immobiliser_Byte_6 : 55|8@0+ (1,0) [0|0] "" Vector__XXX
 SG_ Immobiliser_Byte_5 : 47|8@0+ (1,0) [0|0] "" Vector__XXX
 SG_ Immobiliser_Byte_4 : 39|8@0+ (1,0) [0|0] "" Vector__XXX
 SG_ Immobiliser_Byte_3 : 31|8@0+ (1,0) [0|0] "" Vector__XXX
 SG_ Immobiliser_Byte_2 : 23|8@0+ (1,0) [0|0] "" Vector__XXX
 SG_ Immobiliser_Byte_1 : 15|8@0+ (1,0) [0|0] "" Vector__XXX
 SG_ Immobiliser_Byte_0 : 7|8@0+ (1,0) [0|0] "" Vector__XXX
 SG_ ImmobTransfer_PCM_1_to_8_PATS_B0 : 0|8@1+ (1,0) [0|255] "" Vector__XXX
 SG_ ImmobTransfer_PCM_1_to_8_PATS_B1 : 8|8@1+ (1,0) [0|255] "" Vector__XXX
 SG_ ImmobTransfer_PCM_1_to_8_PATS_B2 : 16|8@1+ (1,0) [0|255] "" Vector__XXX
 SG_ ImmobTransfer_PCM_1_to_8_PATS_B3 : 24|8@1+ (1,0) [0|255] "" Vector__XXX
 SG_ ImmobTransfer_PCM_1_to_8_PATS_B4 : 32|8@1+ (1,0) [0|255] "" Vector__XXX
 SG_ ImmobTransfer_PCM_1_to_8_PATS_B5 : 40|8@1+ (1,0) [0|255] "" Vector__XXX
 SG_ ImmobTransfer_PCM_1_to_8_PATS_B6 : 48|8@1+ (1,0) [0|255] "" Vector__XXX
 SG_ ImmobTransfer_PCM_1_to_8_PATS_B7 : 56|8@1+ (1,0) [0|255] "" Vector__XXX

BO_ 1784 BEM_MSG_2: 8 Vector__XXX
 SG_ Immobiliser_Byte_7 : 63|8@0+ (1,0) [0|0] "" Vector__XXX
 SG_ Immobiliser_Byte_6 : 55|8@0+ (1,0) [0|0] "" Vector__XXX
 SG_ Immobiliser_Byte_5 : 47|8@0+ (1,0) [0|0] "" Vector__XXX
 SG_ Immobiliser_Byte_4 : 39|8@0+ (1,0) [0|0] "" Vector__XXX
 SG_ Immobiliser_Byte_3 : 31|8@0+ (1,0) [0|0] "" Vector__XXX
 SG_ Immobiliser_Byte_2 : 23|8@0+ (1,0) [0|0] "" Vector__XXX
 SG_ Immobiliser_Byte_1 : 15|8@0+ (1,0) [0|0] "" Vector__XXX
 SG_ Immobiliser_Byte_0 : 7|8@0+ (1,0) [0|0] "" Vector__XXX
 SG_ ImmobTransfer_BEM_1_to_8_PATS_B0 : 0|8@1+ (1,0) [0|255] "" Vector__XXX
 SG_ ImmobTransfer_BEM_1_to_8_PATS_B1 : 8|8@1+ (1,0) [0|255] "" Vector__XXX
 SG_ ImmobTransfer_BEM_1_to_8_PATS_B2 : 16|8@1+ (1,0) [0|255] "" Vector__XXX
 SG_ ImmobTransfer_BEM_1_to_8_PATS_B3 : 24|8@1+ (1,0) [0|255] "" Vector__XXX
 SG_ ImmobTransfer_BEM_1_to_8_PATS_B4 : 32|8@1+ (1,0) [0|255] "" Vector__XXX
 SG_ ImmobTransfer_BEM_1_to_8_PATS_B5 : 40|8@1+ (1,0) [0|255] "" Vector__XXX
 SG_ ImmobTransfer_BEM_1_to_8_PATS_B6 : 48|8@1+ (1,0) [0|255] "" Vector__XXX
 SG_ ImmobTransfer_BEM_1_to_8_PATS_B7 : 56|8@1+ (1,0) [0|255] "" Vector__XXX

BO_ 1786 IpcImmob_0x720: 8 Instrument_Cluster
 SG_ Immobilizer_B0 : 0|8@1+ (1,0) [0|255] "" Vector__XXX
 SG_ Immobilizer_B1 : 8|8@1+ (1,0) [0|255] "" Vector__XXX
 SG_ Immobilizer_B2 : 16|8@1+ (1,0) [0|255] "" Vector__XXX
 SG_ Immobilizer_B3 : 24|8@1+ (1,0) [0|255] "" Vector__XXX
 SG_ Immobilizer_B4 : 32|8@1+ (1,0) [0|255] "" Vector__XXX
 SG_ Immobilizer_B5 : 40|8@1+ (1,0) [0|255] "" Vector__XXX
 SG_ Immobilizer_B6 : 48|8@1+ (1,0) [0|255] "" Vector__XXX
 SG_ Immobilizer_B7 : 56|8@1+ (1,0) [0|255] "" Vector__XXX
 SG_ ImmobTransfer_IPC_1_to_8_PATS_B0 : 0|8@1+ (1,0) [0|255] "" Vector__XXX
 SG_ ImmobTransfer_IPC_1_to_8_PATS_B1 : 8|8@1+ (1,0) [0|255] "" Vector__XXX
 SG_ ImmobTransfer_IPC_1_to_8_PATS_B2 : 16|8@1+ (1,0) [0|255] "" Vector__XXX
 SG_ ImmobTransfer_IPC_1_to_8_PATS_B3 : 24|8@1+ (1,0) [0|255] "" Vector__XXX
 SG_ ImmobTransfer_IPC_1_to_8_PATS_B4 : 32|8@1+ (1,0) [0|255] "" Vector__XXX
 SG_ ImmobTransfer_IPC_1_to_8_PATS_B5 : 40|8@1+ (1,0) [0|255] "" Vector__XXX
 SG_ ImmobTransfer_IPC_1_to_8_PATS_B6 : 48|8@1+ (1,0) [0|255] "" Vector__XXX
 SG_ ImmobTransfer_IPC_1_to_8_PATS_B7 : 56|8@1+ (1,0) [0|255] "" Vector__XXX

BO_ 1788 Msg: 8 Vector__XXX

BO_ 1797 IPC_CCP: 8 Vector__XXX
 SG_ CCP__B0 : 0|8@1+ (1,0) [0|255] "" Vector__XXX
 SG_ RawByte1_B1 : 8|8@1+ (1,0) [0|255] "" Vector__XXX
 SG_ RawByte2_B2 : 16|8@1+ (1,0) [0|255] "" Vector__XXX
 SG_ RawByte3_B3 : 24|8@1+ (1,0) [0|255] "" Vector__XXX
 SG_ RawByte4_B4 : 32|8@1+ (1,0) [0|255] "" Vector__XXX
 SG_ RawByte5_B5 : 40|8@1+ (1,0) [0|255] "" Vector__XXX
 SG_ RawByte6_B6 : 48|8@1+ (1,0) [0|255] "" Vector__XXX
 SG_ RawByte7_B7 : 56|8@1+ (1,0) [0|255] "" Vector__XXX

BO_ 1798 BEM_CAN_CALIBRATION_PROTOCOL: 8 Diagnostic_Tester
 SG_ CCP__B0 : 0|8@1+ (1,0) [0|255] "" Vector__XXX
 SG_ RawByte1_B1 : 8|8@1+ (1,0) [0|255] "" Vector__XXX
 SG_ RawByte2_B2 : 16|8@1+ (1,0) [0|255] "" Vector__XXX
 SG_ RawByte3_B3 : 24|8@1+ (1,0) [0|255] "" Vector__XXX
 SG_ RawByte4_B4 : 32|8@1+ (1,0) [0|255] "" Vector__XXX
 SG_ RawByte5_B5 : 40|8@1+ (1,0) [0|255] "" Vector__XXX
 SG_ RawByte6_B6 : 48|8@1+ (1,0) [0|255] "" Vector__XXX
 SG_ RawByte7_B7 : 56|8@1+ (1,0) [0|255] "" Vector__XXX

BO_ 1809 MSCAN_MSG_711: 8 Vector__XXX
 SG_ RawByte0_B0 : 0|8@1+ (1,0) [0|255] "" Vector__XXX
 SG_ RawByte1_B1 : 8|8@1+ (1,0) [0|255] "" Vector__XXX
 SG_ RawByte2_B2 : 16|8@1+ (1,0) [0|255] "" Vector__XXX
 SG_ RawByte3_B3 : 24|8@1+ (1,0) [0|255] "" Vector__XXX
 SG_ RawByte4_B4 : 32|8@1+ (1,0) [0|255] "" Vector__XXX
 SG_ RawByte5_B5 : 40|8@1+ (1,0) [0|255] "" Vector__XXX
 SG_ RawByte6_B6 : 48|8@1+ (1,0) [0|255] "" Vector__XXX
 SG_ RawByte7_B7 : 56|8@1+ (1,0) [0|255] "" Vector__XXX

BO_ 1810 BEM_CAN_CALIBRATION_PROTOCOL: 8 Body_Electronic_Module
 SG_ RawByte0_B0 : 0|8@1+ (1,0) [0|255] "" Vector__XXX
 SG_ RawByte1_B1 : 8|8@1+ (1,0) [0|255] "" Vector__XXX
 SG_ RawByte2_B2 : 16|8@1+ (1,0) [0|255] "" Vector__XXX
 SG_ RawByte3_B3 : 24|8@1+ (1,0) [0|255] "" Vector__XXX
 SG_ RawByte4_B4 : 32|8@1+ (1,0) [0|255] "" Vector__XXX
 SG_ RawByte5_B5 : 40|8@1+ (1,0) [0|255] "" Vector__XXX
 SG_ RawByte6_B6 : 48|8@1+ (1,0) [0|255] "" Vector__XXX
 SG_ RawByte7_B7 : 56|8@1+ (1,0) [0|255] "" Vector__XXX

BO_ 1812 Where_did_this_data_come_from: 8 Vector__XXX
 SG_ RawByte0_B0 : 0|8@1+ (1,0) [0|255] "" Vector__XXX
 SG_ RawByte1_B1 : 8|8@1+ (1,0) [0|255] "" Vector__XXX
 SG_ RawByte2_B2 : 16|8@1+ (1,0) [0|255] "" Vector__XXX
 SG_ RawByte3_B3 : 24|8@1+ (1,0) [0|255] "" Vector__XXX
 SG_ RawByte4_B4 : 32|8@1+ (1,0) [0|255] "" Vector__XXX
 SG_ RawByte5_B5 : 40|8@1+ (1,0) [0|255] "" Vector__XXX
 SG_ RawByte6_B6 : 48|8@1+ (1,0) [0|255] "" Vector__XXX
 SG_ RawByte7_B7 : 56|8@1+ (1,0) [0|255] "" Vector__XXX

BO_ 1824 IC_DiagSig_Rx: 8 InstrumentCluster

BO_ 1830 BEM_DiagSig_Rx: 8 Data_Request
 SG_ Data_Length_Packet_B0 : 0|8@1+ (1,0) [0|255] "" Vector__XXX
 SG_ Service_Request_B1 : 8|8@1+ (1,0) [0|255] "" Vector__XXX
 SG_ Parameters_B2 : 16|8@1+ (1,0) [0|255] "" Vector__XXX
 SG_ _0XFF_B3 : 24|8@1+ (1,0) [0|255] "" Vector__XXX
 SG_ Parameters_B4 : 32|8@1+ (1,0) [0|255] "" Vector__XXX
 SG_ Parameters_B5 : 40|8@1+ (1,0) [0|255] "" Vector__XXX
 SG_ Parameters_B6 : 48|8@1+ (1,0) [0|255] "" Vector__XXX
 SG_ Parameters_B7 : 56|8@1+ (1,0) [0|255] "" Vector__XXX

BO_ 1831 ACM_DiagSig_Rx: 8 Audio_Control_Module
 SG_ Data_Length_Packet_B0 : 0|8@1+ (1,0) [0|255] "" Vector__XXX
 SG_ Service_Request_B1 : 8|8@1+ (1,0) [0|255] "" Vector__XXX
 SG_ Parameters_B2 : 16|8@1+ (1,0) [0|255] "" Vector__XXX
 SG_ _0XFF_B3 : 24|8@1+ (1,0) [0|255] "" Vector__XXX
 SG_ Parameters_B4 : 32|8@1+ (1,0) [0|255] "" Vector__XXX
 SG_ Parameters_B5 : 40|8@1+ (1,0) [0|255] "" Vector__XXX
 SG_ Parameters_B6 : 48|8@1+ (1,0) [0|255] "" Vector__XXX
 SG_ Parameters_B7 : 56|8@1+ (1,0) [0|255] "" Vector__XXX

BO_ 1832 IC_DiagSig_Tx: 8 Instrument_Cluster
 SG_ Data_Length_Packet_B0 : 0|8@1+ (1,0) [0|255] "" Vector__XXX
 SG_ Response_B1 : 8|8@1+ (1,0) [0|255] "" Vector__XXX
 SG_ Request_Echo_B2 : 16|8@1+ (1,0) [0|255] "" Vector__XXX
 SG_ Error_Code_ID_B3 : 24|8@1+ (1,0) [0|255] "" Vector__XXX
 SG_ Parameters_B4 : 32|8@1+ (1,0) [0|255] "" Vector__XXX
 SG_ Parameters_B5 : 40|8@1+ (1,0) [0|255] "" Vector__XXX
 SG_ Parameters_B6 : 48|8@1+ (1,0) [0|255] "" Vector__XXX
 SG_ Parameters_B7 : 56|8@1+ (1,0) [0|255] "" Vector__XXX

BO_ 1838 BEM_DiagSig_Tx: 8 Body_Electronic_Module
 SG_ Data_Length_Packet_B0 : 0|8@1+ (1,0) [0|255] "" Vector__XXX
 SG_ Response_B1 : 8|8@1+ (1,0) [0|255] "" Vector__XXX
 SG_ Request_Echo_B2 : 16|8@1+ (1,0) [0|255] "" Vector__XXX
 SG_ Error_Code_ID_B3 : 24|8@1+ (1,0) [0|255] "" Vector__XXX
 SG_ Parameters_B4 : 32|8@1+ (1,0) [0|255] "" Vector__XXX
 SG_ Parameters_B5 : 40|8@1+ (1,0) [0|255] "" Vector__XXX
 SG_ Parameters_B6 : 48|8@1+ (1,0) [0|255] "" Vector__XXX
 SG_ Parameters_B7 : 56|8@1+ (1,0) [0|255] "" Vector__XXX

BO_ 1839 ACM_DiagSig_Tx: 8 Audio_Control_Module
 SG_ Data_Length_Packet_B0 : 0|8@1+ (1,0) [0|255] "" Vector__XXX
 SG_ Response_B1 : 8|8@1+ (1,0) [0|255] "" Vector__XXX
 SG_ Request_Echo_B2 : 16|8@1+ (1,0) [0|255] "" Vector__XXX
 SG_ Error_Code_ID_B3 : 24|8@1+ (1,0) [0|255] "" Vector__XXX
 SG_ Parameters_B4 : 32|8@1+ (1,0) [0|255] "" Vector__XXX
 SG_ Parameters_B5 : 40|8@1+ (1,0) [0|255] "" Vector__XXX
 SG_ Parameters_B6 : 48|8@1+ (1,0) [0|255] "" Vector__XXX
 SG_ Parameters_B7 : 56|8@1+ (1,0) [0|255] "" Vector__XXX

BO_ 1843 HIM_DiagSig_Rx: 8 Data_Request
 SG_ Data_Length_Packet_B0 : 0|8@1+ (1,0) [0|255] "" Vector__XXX
 SG_ Service_Request_B1 : 8|8@1+ (1,0) [0|255] "" Vector__XXX
 SG_ Parameters_B2 : 16|8@1+ (1,0) [0|255] "" Vector__XXX
 SG_ Parameters_B3 : 24|8@1+ (1,0) [0|255] "" Vector__XXX
 SG_ Parameters_B4 : 32|8@1+ (1,0) [0|255] "" Vector__XXX
 SG_ Parameters_B5 : 40|8@1+ (1,0) [0|255] "" Vector__XXX
 SG_ Parameters_B6 : 48|8@1+ (1,0) [0|255] "" Vector__XXX
 SG_ Parameters_B7 : 56|8@1+ (1,0) [0|255] "" Vector__XXX
 SG_ LEN_B0 : 0|8@1+ (1,0) [0|255] "" Vector__XXX
 SG_ RawByte1_B1 : 8|8@1+ (1,0) [0|255] "" Vector__XXX
 SG_ RawByte2_B2 : 16|8@1+ (1,0) [0|255] "" Vector__XXX
 SG_ _0XFF_B3 : 24|8@1+ (1,0) [0|255] "" Vector__XXX
 SG_ RawByte4_B4 : 32|8@1+ (1,0) [0|255] "" Vector__XXX
 SG_ RawByte5_B5 : 40|8@1+ (1,0) [0|255] "" Vector__XXX
 SG_ RawByte6_B6 : 48|8@1+ (1,0) [0|255] "" Vector__XXX
 SG_ RawByte7_B7 : 56|8@1+ (1,0) [0|255] "" Vector__XXX

BO_ 1846 PAM_DiagSig_Rx: 8 Restraints_Control_Module
 SG_ Data_Length_Packet_B0 : 0|8@1+ (1,0) [0|255] "" Vector__XXX
 SG_ Service_Request_B1 : 8|8@1+ (1,0) [0|255] "" Vector__XXX
 SG_ Parameters_B2 : 16|8@1+ (1,0) [0|255] "" Vector__XXX
 SG_ _0XFF_B3 : 24|8@1+ (1,0) [0|255] "" Vector__XXX
 SG_ Parameters_B4 : 32|8@1+ (1,0) [0|255] "" Vector__XXX
 SG_ Parameters_B5 : 40|8@1+ (1,0) [0|255] "" Vector__XXX
 SG_ Parameters_B6 : 48|8@1+ (1,0) [0|255] "" Vector__XXX
 SG_ Parameters_B7 : 56|8@1+ (1,0) [0|255] "" Vector__XXX

BO_ 1847 RCM_DiagSig_Rx: 8 Parking_Aid_Module
 SG_ Data_Length_Packet_B0 : 0|8@1+ (1,0) [0|255] "" Vector__XXX
 SG_ Service_Request_B1 : 8|8@1+ (1,0) [0|255] "" Vector__XXX
 SG_ Parameters_B2 : 16|8@1+ (1,0) [0|255] "" Vector__XXX
 SG_ _0XFF_B3 : 24|8@1+ (1,0) [0|255] "" Vector__XXX
 SG_ Parameters_B4 : 32|8@1+ (1,0) [0|255] "" Vector__XXX
 SG_ Parameters_B5 : 40|8@1+ (1,0) [0|255] "" Vector__XXX
 SG_ Parameters_B6 : 48|8@1+ (1,0) [0|255] "" Vector__XXX
 SG_ Parameters_B7 : 56|8@1+ (1,0) [0|255] "" Vector__XXX

BO_ 1850 HIM_DiagSig_Tx: 8 HVAC_Integrated_Module
 SG_ Data_Length_Packet_B0 : 0|8@1+ (1,0) [0|255] "" Vector__XXX
 SG_ Response_B1 : 8|8@1+ (1,0) [0|255] "" Vector__XXX
 SG_ Echo_Request_B2 : 16|8@1+ (1,0) [0|255] "" Vector__XXX
 SG_ Error_Code_ID_B3 : 24|8@1+ (1,0) [0|255] "" Vector__XXX
 SG_ Parameters_B4 : 32|8@1+ (1,0) [0|255] "" Vector__XXX
 SG_ Parameters_B5 : 40|8@1+ (1,0) [0|255] "" Vector__XXX
 SG_ Parameters_B6 : 48|8@1+ (1,0) [0|255] "" Vector__XXX
 SG_ Parameters_B7 : 56|8@1+ (1,0) [0|255] "" Vector__XXX

BO_ 1854 PAM_DiagSig_Tx: 8 Data_Response
 SG_ Data_Length_Packet_B0 : 0|8@1+ (1,0) [0|255] "" Vector__XXX
 SG_ Response_B1 : 8|8@1+ (1,0) [0|255] "" Vector__XXX
 SG_ Echo_Request_B2 : 16|8@1+ (1,0) [0|255] "" Vector__XXX
 SG_ Error_Code_ID_B3 : 24|8@1+ (1,0) [0|255] "" Vector__XXX
 SG_ Parameters_B4 : 32|8@1+ (1,0) [0|255] "" Vector__XXX
 SG_ Parameters_B5 : 40|8@1+ (1,0) [0|255] "" Vector__XXX
 SG_ Parameters_B6 : 48|8@1+ (1,0) [0|255] "" Vector__XXX
 SG_ Parameters_B7 : 56|8@1+ (1,0) [0|255] "" Vector__XXX

BO_ 1855 PAM_DiagSig_Tx: 8 Parking_Aid_Module
 SG_ Data_Length_Packet_B0 : 0|8@1+ (1,0) [0|255] "" Vector__XXX
 SG_ Response_B1 : 8|8@1+ (1,0) [0|255] "" Vector__XXX
 SG_ Request_Echo_B2 : 16|8@1+ (1,0) [0|255] "" Vector__XXX
 SG_ Error_Code_ID_B3 : 24|8@1+ (1,0) [0|255] "" Vector__XXX
 SG_ Parameters_B4 : 32|8@1+ (1,0) [0|255] "" Vector__XXX
 SG_ Parameters_B5 : 40|8@1+ (1,0) [0|255] "" Vector__XXX
 SG_ Parameters_B6 : 48|8@1+ (1,0) [0|255] "" Vector__XXX
 SG_ Parameters_B7 : 56|8@1+ (1,0) [0|255] "" Vector__XXX

BO_ 1888 Diagnostic_Service_Request_0xBF: 8 Antilock_Brake_Module
 SG_ B0 : 0|8@1+ (1,0) [0|255] "" Vector__XXX
 SG_ RawByte1_B1 : 8|8@1+ (1,0) [0|255] "" Vector__XXX
 SG_ B2 : 16|8@1+ (1,0) [0|255] "" Vector__XXX
 SG_ B3 : 24|8@1+ (1,0) [0|255] "" Vector__XXX
 SG_ B4 : 32|8@1+ (1,0) [0|255] "" Vector__XXX
 SG_ B5 : 40|8@1+ (1,0) [0|255] "" Vector__XXX
 SG_ B6 : 48|8@1+ (1,0) [0|255] "" Vector__XXX
 SG_ B7 : 56|8@1+ (1,0) [0|255] "" Vector__XXX
 SG_ Data_Length_Packet_B0 : 0|8@1+ (1,0) [0|255] "" Vector__XXX
 SG_ Service_Request_B1 : 8|8@1+ (1,0) [0|255] "" Vector__XXX
 SG_ Parameters_B2 : 16|8@1+ (1,0) [0|255] "" Vector__XXX
 SG_ _0XFF_B3 : 24|8@1+ (1,0) [0|255] "" Vector__XXX
 SG_ Parameters_B4 : 32|8@1+ (1,0) [0|255] "" Vector__XXX
 SG_ Parameters_B5 : 40|8@1+ (1,0) [0|255] "" Vector__XXX
 SG_ Parameters_B6 : 48|8@1+ (1,0) [0|255] "" Vector__XXX
 SG_ Parameters_B7 : 56|8@1+ (1,0) [0|255] "" Vector__XXX

BO_ 1895 AIM_DiagSig_Rx: 8 Audio_Interface_Module
 SG_ Data_Length_Packet_B0 : 0|8@1+ (1,0) [0|255] "" Vector__XXX
 SG_ Service_Request_B1 : 8|8@1+ (1,0) [0|255] "" Vector__XXX
 SG_ Parameters_B2 : 16|8@1+ (1,0) [0|255] "" Vector__XXX
 SG_ _0XFF_B3 : 24|8@1+ (1,0) [0|255] "" Vector__XXX
 SG_ Parameters_B4 : 32|8@1+ (1,0) [0|255] "" Vector__XXX
 SG_ Parameters_B5 : 40|8@1+ (1,0) [0|255] "" Vector__XXX
 SG_ Parameters_B6 : 48|8@1+ (1,0) [0|255] "" Vector__XXX
 SG_ Parameters_B7 : 56|8@1+ (1,0) [0|255] "" Vector__XXX

BO_ 1896 ABS_DiagSig_Tx: 8 Antilock_Brake_Module
 SG_ Data_Length_Packet_B0 : 0|8@1+ (1,0) [0|255] "" Vector__XXX
 SG_ Response_B1 : 8|8@1+ (1,0) [0|255] "" Vector__XXX
 SG_ Request_Echo_B2 : 16|8@1+ (1,0) [0|255] "" Vector__XXX
 SG_ Error_Code_ID_B3 : 24|8@1+ (1,0) [0|255] "" Vector__XXX
 SG_ Parameters_B4 : 32|8@1+ (1,0) [0|255] "" Vector__XXX
 SG_ Parameters_B5 : 40|8@1+ (1,0) [0|255] "" Vector__XXX
 SG_ Parameters_B6 : 48|8@1+ (1,0) [0|255] "" Vector__XXX
 SG_ Parameters_B7 : 56|8@1+ (1,0) [0|255] "" Vector__XXX

BO_ 1903 AIM_DiagSig_Tx: 8 Audio_Interface_Module
 SG_ Data_Length_Packet_B0 : 0|8@1+ (1,0) [0|255] "" Vector__XXX
 SG_ Response_B1 : 8|8@1+ (1,0) [0|255] "" Vector__XXX
 SG_ Request_Echo_B2 : 16|8@1+ (1,0) [0|255] "" Vector__XXX
 SG_ Error_Code_ID_B3 : 24|8@1+ (1,0) [0|255] "" Vector__XXX
 SG_ Parameters_B4 : 32|8@1+ (1,0) [0|255] "" Vector__XXX
 SG_ Parameters_B5 : 40|8@1+ (1,0) [0|255] "" Vector__XXX
 SG_ Parameters_B6 : 48|8@1+ (1,0) [0|255] "" Vector__XXX
 SG_ Parameters_B7 : 56|8@1+ (1,0) [0|255] "" Vector__XXX

BO_ 1921 BPM_DiagSig_Rx: 8 Bluetooth_Phone_Module
 SG_ Data_Length_Packet_B0 : 0|8@1+ (1,0) [0|255] "" Vector__XXX
 SG_ Service_Request_B1 : 8|8@1+ (1,0) [0|255] "" Vector__XXX
 SG_ Parameters_B2 : 16|8@1+ (1,0) [0|255] "" Vector__XXX
 SG_ _0XFF_B3 : 24|8@1+ (1,0) [0|255] "" Vector__XXX
 SG_ Parameters_B4 : 32|8@1+ (1,0) [0|255] "" Vector__XXX
 SG_ Parameters_B5 : 40|8@1+ (1,0) [0|255] "" Vector__XXX
 SG_ Parameters_B6 : 48|8@1+ (1,0) [0|255] "" Vector__XXX
 SG_ Parameters_B7 : 56|8@1+ (1,0) [0|255] "" Vector__XXX

BO_ 1929 BPM_DiagSig_Tx: 8 Data_Response
 SG_ Data_Length_Packet_B0 : 0|8@1+ (1,0) [0|255] "" Vector__XXX
 SG_ Response_B1 : 8|8@1+ (1,0) [0|255] "" Vector__XXX
 SG_ Request_Echo_B2 : 16|8@1+ (1,0) [0|255] "" Vector__XXX
 SG_ Error_Code_ID_B3 : 24|8@1+ (1,0) [0|255] "" Vector__XXX
 SG_ Parameters_B4 : 32|8@1+ (1,0) [0|255] "" Vector__XXX
 SG_ Parameters_B5 : 40|8@1+ (1,0) [0|255] "" Vector__XXX
 SG_ Parameters_B6 : 48|8@1+ (1,0) [0|255] "" Vector__XXX
 SG_ Parameters_B7 : 56|8@1+ (1,0) [0|255] "" Vector__XXX

BO_ 1943 SAS_DiagSig_Rx: 8 Steering_Angle_Sensor
 SG_ Data_Length_Packet_B0 : 0|8@1+ (1,0) [0|255] "" Vector__XXX
 SG_ Service_Request_B1 : 8|8@1+ (1,0) [0|255] "" Vector__XXX
 SG_ Echo_Request_B2 : 16|8@1+ (1,0) [0|255] "" Vector__XXX
 SG_ Error_Code_ID_B3 : 24|8@1+ (1,0) [0|255] "" Vector__XXX
 SG_ Parameters_B4 : 32|8@1+ (1,0) [0|255] "" Vector__XXX
 SG_ Parameters_B5 : 40|8@1+ (1,0) [0|255] "" Vector__XXX
 SG_ Parameters_B6 : 48|8@1+ (1,0) [0|255] "" Vector__XXX
 SG_ Parameters_B7 : 56|8@1+ (1,0) [0|255] "" Vector__XXX

BO_ 1951 SAS_DiagSig_Tx: 8 Steering_Angle_Sensor
 SG_ Data_Length_Packet_B0 : 0|8@1+ (1,0) [0|255] "" Vector__XXX
 SG_ Response_B1 : 8|8@1+ (1,0) [0|255] "" Vector__XXX
 SG_ Echo_Request_B2 : 16|8@1+ (1,0) [0|255] "" Vector__XXX
 SG_ Error_Code_ID_B3 : 24|8@1+ (1,0) [0|255] "" Vector__XXX
 SG_ Parameters_B4 : 32|8@1+ (1,0) [0|255] "" Vector__XXX
 SG_ Parameters_B5 : 40|8@1+ (1,0) [0|255] "" Vector__XXX
 SG_ Parameters_B6 : 48|8@1+ (1,0) [0|255] "" Vector__XXX
 SG_ Parameters_B7 : 56|8@1+ (1,0) [0|255] "" Vector__XXX

BO_ 1958 FDIM_DiagSig_Rx: 8 Data_Request
 SG_ Data_Length_Packet_B0 : 0|8@1+ (1,0) [0|255] "" Vector__XXX
 SG_ Service_Request_B1 : 8|8@1+ (1,0) [0|255] "" Vector__XXX
 SG_ Parameters_B2 : 16|8@1+ (1,0) [0|255] "" Vector__XXX
 SG_ Parameters_B3 : 24|8@1+ (1,0) [0|255] "" Vector__XXX
 SG_ Parameters_B4 : 32|8@1+ (1,0) [0|255] "" Vector__XXX
 SG_ Parameters_B5 : 40|8@1+ (1,0) [0|255] "" Vector__XXX
 SG_ Parameters_B6 : 48|8@1+ (1,0) [0|255] "" Vector__XXX
 SG_ Parameters_B7 : 56|8@1+ (1,0) [0|255] "" Vector__XXX

BO_ 1966 FDIM_DiagSig_Tx: 8 Front_Display_Interface_Module
 SG_ Data_Length_Packet_B0 : 0|8@1+ (1,0) [0|255] "" Vector__XXX
 SG_ Response_B1 : 8|8@1+ (1,0) [0|255] "" Vector__XXX
 SG_ Request_Echo_B2 : 16|8@1+ (1,0) [0|255] "" Vector__XXX
 SG_ Error_Code_ID_B3 : 24|8@1+ (1,0) [0|255] "" Vector__XXX
 SG_ Parameters_B4 : 32|8@1+ (1,0) [0|255] "" Vector__XXX
 SG_ Parameters_B5 : 40|8@1+ (1,0) [0|255] "" Vector__XXX
 SG_ Parameters_B6 : 48|8@1+ (1,0) [0|255] "" Vector__XXX
 SG_ Parameters_B7 : 56|8@1+ (1,0) [0|255] "" Vector__XXX

BO_ 2015 MessageLabel: 8 Vector__XXX

BO_ 2016 request: 8 Powertrain_Control_Module
 SG_ Data_Length_Packet_B0 : 0|8@1+ (1,0) [0|255] "" Vector__XXX
 SG_ Service_Request_B1 : 8|8@1+ (1,0) [0|255] "" Vector__XXX
 SG_ Parameters_B2 : 16|8@1+ (1,0) [0|255] "" Vector__XXX
 SG_ Parameters_B3 : 24|8@1+ (1,0) [0|255] "" Vector__XXX
 SG_ Parameters_B4 : 32|8@1+ (1,0) [0|255] "" Vector__XXX
 SG_ Parameters_B5 : 40|8@1+ (1,0) [0|255] "" Vector__XXX
 SG_ Parameters_B6 : 48|8@1+ (1,0) [0|255] "" Vector__XXX
 SG_ Parameters_B7 : 56|8@1+ (1,0) [0|255] "" Vector__XXX
 SG_ LEN_B0 : 0|8@1+ (1,0) [0|255] "" Vector__XXX
 SG_ RawByte1_B1 : 8|8@1+ (1,0) [0|255] "" Vector__XXX
 SG_ RawByte2_B2 : 16|8@1+ (1,0) [0|255] "" Vector__XXX
 SG_ _0XFF_B3 : 24|8@1+ (1,0) [0|255] "" Vector__XXX
 SG_ RawByte4_B4 : 32|8@1+ (1,0) [0|255] "" Vector__XXX
 SG_ RawByte5_B5 : 40|8@1+ (1,0) [0|255] "" Vector__XXX
 SG_ RawByte6_B6 : 48|8@1+ (1,0) [0|255] "" Vector__XXX
 SG_ RawByte7_B7 : 56|8@1+ (1,0) [0|255] "" Vector__XXX

BO_ 2017 TCM_DiagSig_Rx: 8 Transmission_Control_Module
 SG_ Data_Length_Packet_B0 : 0|8@1+ (1,0) [0|255] "" Vector__XXX
 SG_ Response_B1 : 8|8@1+ (1,0) [0|255] "" Vector__XXX
 SG_ Echo_Request_B2 : 16|8@1+ (1,0) [0|255] "" Vector__XXX
 SG_ Error_Code_ID_B3 : 24|8@1+ (1,0) [0|255] "" Vector__XXX
 SG_ Parameters_B4 : 32|8@1+ (1,0) [0|255] "" Vector__XXX
 SG_ Parameters_B5 : 40|8@1+ (1,0) [0|255] "" Vector__XXX
 SG_ Parameters_B6 : 48|8@1+ (1,0) [0|255] "" Vector__XXX
 SG_ Parameters_B7 : 56|8@1+ (1,0) [0|255] "" Vector__XXX
 SG_ RawByte0_B0 : 0|8@1+ (1,0) [0|255] "" Vector__XXX
 SG_ RawByte1_B1 : 8|8@1+ (1,0) [0|255] "" Vector__XXX
 SG_ RawByte2_B2 : 16|8@1+ (1,0) [0|255] "" Vector__XXX
 SG_ _0XFF_B3 : 24|8@1+ (1,0) [0|255] "" Vector__XXX
 SG_ RawByte4_B4 : 32|8@1+ (1,0) [0|255] "" Vector__XXX
 SG_ RawByte5_B5 : 40|8@1+ (1,0) [0|255] "" Vector__XXX
 SG_ RawByte6_B6 : 48|8@1+ (1,0) [0|255] "" Vector__XXX
 SG_ RawByte7_B7 : 56|8@1+ (1,0) [0|255] "" Vector__XXX

BO_ 2024 OnBoardDiagnostics: 8 OnBoardDiagnostics
 SG_ S1_PID_00_PIDsSupported_01_20 : 23|32@0+ (1,0) [0|4.29497] "" OnBoardDiagnostics
 SG_ S1_PID_01_MonitorStatus : 31|32@0+ (1,0) [0|4.29497] "" OnBoardDiagnostics
 SG_ S1_PID_02_FreezeDTC : 31|16@0+ (1,0) [0|65535] "" OnBoardDiagnostics
 SG_ S1_PID_03_FuelSystemStatus : 31|16@0+ (1,0) [0|65535] "" OnBoardDiagnostics
 SG_ S1_PID_04_CalcEngineLoad : 31|8@0+ (0.39216,0) [0|100] "%" OnBoardDiagnostics
 SG_ S1_PID_05_EngineCoolantTemp : 31|8@0+ (1,-40) [-40|215] "degC" OnBoardDiagnostics
 SG_ S1_PID_06_ShortFuelTrimBank1 : 31|8@0+ (0.78125,-100) [-100|99.2188] "%" OnBoardDiagnostics
 SG_ S1_PID_07_LongFuelTrimBank1 : 31|8@0+ (0.78125,-100) [-100|99.2188] "%" OnBoardDiagnostics
 SG_ S1_PID_08_ShortFuelTrimBank2 : 31|8@0+ (0.78125,-100) [-100|99.2188] "%" OnBoardDiagnostics
 SG_ S1_PID_09_LongFuelTrimBank2 : 31|8@0+ (0.78125,-100) [-100|99.2188] "%" OnBoardDiagnostics
 SG_ S1_PID_0A_FuelPressure : 31|8@0+ (3,0) [0|765] "kPa" OnBoardDiagnostics
 SG_ S1_PID_0B_IntakeManiAbsPress : 31|8@0+ (1,0) [0|255] "kPa" OnBoardDiagnostics
 SG_ S1_PID_0C_EngineRPM : 31|16@0+ (0.25,0) [0|16383.8] "rpm" OnBoardDiagnostics
 SG_ S1_PID_0D_VehicleSpeed : 31|8@0+ (1,0) [0|255] "km/h" OnBoardDiagnostics
 SG_ S1_PID_0E_TimingAdvance : 31|8@0+ (0.5,-64) [-64|63.5] "deg" before TDC OnBoardDiagnostics
 SG_ S1_PID_0F_IntakeAirTemperature : 31|8@0+ (1,-40) [-40|215] "degC" OnBoardDiagnostics
 SG_ S1_PID_10_MAFAirFlowRate : 31|16@0+ (0.01,0) [0|655.35] "grams/sec" OnBoardDiagnostics
 SG_ S1_PID_11_ThrottlePosition : 31|8@0+ (0.39216,0) [0|100] "%" OnBoardDiagnostics
 SG_ S1_PID_12_CmdSecAirStatus : 31|8@0+ (1,0) [0|255] "" OnBoardDiagnostics
 SG_ S1_PID_14_OxySensor1_STFT : 39|8@0+ (0.78125,-100) [-100|99.2188] "%" OnBoardDiagnostics
 SG_ S1_PID_14_OxySensor1_Volt : 31|8@0+ (0.005,0) [0|1.275] "volts" OnBoardDiagnostics
 SG_ S1_PID_15_OxySensor2_STFT : 39|8@0+ (0.78125,-100) [-100|99.2188] "%" OnBoardDiagnostics
 SG_ S1_PID_15_OxySensor2_Volt : 31|8@0+ (0.005,0) [0|1.275] "volts" OnBoardDiagnostics
 SG_ S1_PID_16_OxySensor3_STFT : 39|8@0+ (0.78125,-100) [-100|99.2188] "%" OnBoardDiagnostics
 SG_ S1_PID_16_OxySensor3_Volt : 31|8@0+ (0.005,0) [0|1.275] "volts" OnBoardDiagnostics
 SG_ S1_PID_17_OxySensor4_STFT : 39|8@0+ (0.78125,-100) [-100|99.2188] "%" OnBoardDiagnostics
 SG_ S1_PID_17_OxySensor4_Volt : 31|8@0+ (0.005,0) [0|1.275] "volts" OnBoardDiagnostics
 SG_ S1_PID_18_OxySensor5_STFT : 39|8@0+ (0.78125,-100) [-100|99.2188] "%" OnBoardDiagnostics
 SG_ S1_PID_18_OxySensor5_Volt : 31|8@0+ (0.005,0) [0|1.275] "volts" OnBoardDiagnostics
 SG_ S1_PID_19_OxySensor6_STFT : 39|8@0+ (0.78125,-100) [-100|99.2188] "%" OnBoardDiagnostics
 SG_ S1_PID_19_OxySensor6_Volt : 31|8@0+ (0.005,0) [0|1.275] "volts" OnBoardDiagnostics
 SG_ S1_PID_1A_OxySensor7_STFT : 39|8@0+ (0.78125,-100) [-100|99.2188] "%" OnBoardDiagnostics
 SG_ S1_PID_1A_OxySensor7_Volt : 31|8@0+ (0.005,0) [0|1.275] "volts" OnBoardDiagnostics
 SG_ S1_PID_1B_OxySensor8_STFT : 39|8@0+ (0.78125,-100) [-100|99.2188] "%" OnBoardDiagnostics
 SG_ S1_PID_1B_OxySensor8_Volt : 31|8@0+ (0.005,0) [0|1.275] "volts" OnBoardDiagnostics
 SG_ S1_PID_1C_OBDStandard : 31|8@0+ (1,0) [0|255] "" OnBoardDiagnostics
 SG_ S1_PID_1F_TimeSinceEngStart : 31|16@0+ (1,0) [0|65535] "seconds" OnBoardDiagnostics
 SG_ S1_PID_20_PIDsSupported_21_40 : 31|32@0+ (1,0) [0|4.29497] "" OnBoardDiagnostics
 SG_ S1_PID_21_DistanceMILOn : 31|16@0+ (1,0) [0|65535] "km" OnBoardDiagnostics
 SG_ S1_PID_22_FuelRailPres : 31|16@0+ (0.079,0) [0|5177.27] "kPa" OnBoardDiagnostics
 SG_ S1_PID_23_FuelRailGaug : 31|16@0+ (10,0) [0|655350] "kPa" OnBoardDiagnostics
 SG_ S1_PID_24_OxySensor1_FAER : 31|16@0+ (3.05176,-05) [0|2] "ratio" OnBoardDiagnostics
 SG_ S1_PID_24_OxySensor1_Volt : 47|16@0+ (0.00012207,0) [0|2] "volts" OnBoardDiagnostics
 SG_ S1_PID_25_OxySensor2_FAER : 31|16@0+ (3.05176,-05) [0|2] "ratio" OnBoardDiagnostics
 SG_ S1_PID_25_OxySensor2_Volt : 47|16@0+ (0.00012207,0) [0|8] "volts" OnBoardDiagnostics
 SG_ S1_PID_26_OxySensor3_FAER : 31|16@0+ (3.05176,-05) [0|2] "ratio" OnBoardDiagnostics
 SG_ S1_PID_26_OxySensor3_Volt : 47|16@0+ (0.00012207,0) [0|8] "volts" OnBoardDiagnostics
 SG_ S1_PID_27_OxySensor4_FAER : 31|16@0+ (3.05176,-05) [0|2] "ratio" OnBoardDiagnostics
 SG_ S1_PID_27_OxySensor4_Volt : 47|16@0+ (0.00012207,0) [0|8] "volts" OnBoardDiagnostics
 SG_ S1_PID_28_OxySensor5_FAER : 31|16@0+ (3.05176,-05) [0|2] "ratio" OnBoardDiagnostics
 SG_ S1_PID_28_OxySensor5_Volt : 47|16@0+ (0.00012207,0) [0|8] "volts" OnBoardDiagnostics
 SG_ S1_PID_29_OxySensor6_FAER : 31|16@0+ (3.05176,-05) [0|2] "ratio" OnBoardDiagnostics
 SG_ S1_PID_29_OxySensor6_Volt : 47|16@0+ (0.00012207,0) [0|8] "volts" OnBoardDiagnostics
 SG_ S1_PID_2A_OxySensor7_FAER : 31|16@0+ (3.05176,-05) [0|2] "ratio" OnBoardDiagnostics
 SG_ S1_PID_2A_OxySensor7_Volt : 47|16@0+ (0.00012207,0) [0|8] "volts" OnBoardDiagnostics
 SG_ S1_PID_2B_OxySensor8_FAER : 31|16@0+ (3.05176,-05) [0|2] "ratio" OnBoardDiagnostics
 SG_ S1_PID_2B_OxySensor8_Volt : 47|16@0+ (0.00012207,0) [0|8] "volts" OnBoardDiagnostics
 SG_ S1_PID_2E_CmdEvapPurge : 31|8@0+ (0.392157,0) [0|100] "%" OnBoardDiagnostics
 SG_ S1_PID_2F_FuelTankLevel : 31|8@0+ (0.392157,0) [0|100] "%" OnBoardDiagnostics
 SG_ S1_PID_30_WarmUpsSinceCodeClear : 31|8@0+ (1,0) [0|255] "count" OnBoardDiagnostics
 SG_ S1_PID_31_DistanceSinceCodeClear : 31|16@0+ (1,0) [0|65535] "km" OnBoardDiagnostics
 SG_ S1_PID_32_EvapSysVaporPres : 31|16@0- (0.25,0) [-8192|8191.75] "Pa" OnBoardDiagnostics
 SG_ S1_PID_33_AbsBaroPres : 31|8@0+ (1,0) [0|255] "kPa" OnBoardDiagnostics
 SG_ S1_PID_34_OxySensor1_Crnt : 47|16@0+ (0.00390625,-128) [-128|128] "mA" OnBoardDiagnostics
 SG_ S1_PID_34_OxySensor1_FAER : 31|16@0+ (3.05176,-05) [0|2] "ratio" OnBoardDiagnostics
 SG_ S1_PID_35_OxySensor2_Crnt : 47|16@0+ (0.00390625,-128) [-128|128] "mA" OnBoardDiagnostics
 SG_ S1_PID_35_OxySensor2_FAER : 31|16@0+ (3.05176,-05) [0|2] "ratio" OnBoardDiagnostics
 SG_ S1_PID_36_OxySensor3_Crnt : 47|16@0+ (0.00390625,-128) [-128|128] "mA" OnBoardDiagnostics
 SG_ S1_PID_36_OxySensor3_FAER : 31|16@0+ (3.05176,-05) [0|2] "ratio" OnBoardDiagnostics
 SG_ S1_PID_37_OxySensor4_Crnt : 47|16@0+ (0.00390625,-128) [-128|128] "mA" OnBoardDiagnostics
 SG_ S1_PID_37_OxySensor4_FAER : 31|16@0+ (3.05176,-05) [0|2] "ratio" OnBoardDiagnostics
 SG_ S1_PID_38_OxySensor5_Crnt : 47|16@0+ (0.00390625,-128) [-128|128] "mA" OnBoardDiagnostics
 SG_ S1_PID_38_OxySensor5_FAER : 31|16@0+ (3.05176,-05) [0|2] "ratio" OnBoardDiagnostics
 SG_ S1_PID_39_OxySensor6_Crnt : 47|16@0+ (0.00390625,-128) [-128|128] "mA" OnBoardDiagnostics
 SG_ S1_PID_39_OxySensor6_FAER : 31|16@0+ (3.05176,-05) [0|2] "ratio" OnBoardDiagnostics
 SG_ S1_PID_3A_OxySensor7_Crnt : 47|16@0+ (0.00390625,-128) [-128|128] "mA" OnBoardDiagnostics
 SG_ S1_PID_3A_OxySensor7_FAER : 31|16@0+ (3.05176,-05) [0|2] "ratio" OnBoardDiagnostics
 SG_ S1_PID_3B_OxySensor8_Crnt : 47|16@0+ (0.00390625,-128) [-128|128] "mA" OnBoardDiagnostics
 SG_ S1_PID_3B_OxySensor8_FAER : 31|16@0+ (3.05176,-05) [0|2] "ratio" OnBoardDiagnostics
 SG_ S1_PID_3C_CatTempBank1Sens1 : 31|16@0+ (0.1,-40) [-40|6513.5] "degC" OnBoardDiagnostics
 SG_ S1_PID_3D_CatTempBank2Sens1 : 31|16@0+ (0.1,-40) [-40|6513.5] "degC" OnBoardDiagnostics
 SG_ S1_PID_3E_CatTempBank1Sens2 : 31|16@0+ (0.1,-40) [-40|6513.5] "degC" OnBoardDiagnostics
 SG_ S1_PID_3F_CatTempBank2Sens2 : 31|16@0+ (0.1,-40) [-40|6513.5] "degC" OnBoardDiagnostics
 SG_ S1_PID_40_PIDsSupported_41_60 : 31|32@0+ (1,0) [0|4.29497] "" OnBoardDiagnostics
 SG_ S1_PID_41_MonStatusDriveCycle : 31|32@0+ (1,0) [0|4.29497] "" OnBoardDiagnostics
 SG_ S1_PID_42_ControlModuleVolt : 31|16@0+ (0.001,0) [0|65.535] "V" OnBoardDiagnostics
 SG_ S1_PID_43_AbsLoadValue : 31|16@0+ (0.392157,0) [0|25700] "%" OnBoardDiagnostics
 SG_ S1_PID_44_FuelAirCmdEquiv : 31|16@0+ (3.05176,-05) [0|2] "ratio" OnBoardDiagnostics
 SG_ S1_PID_45_RelThrottlePos : 31|8@0+ (0.392157,0) [0|100] "%" OnBoardDiagnostics
 SG_ S1_PID_46_AmbientAirTemp : 31|8@0+ (1,-40) [-40|215] "degC" OnBoardDiagnostics
 SG_ S1_PID_47_AbsThrottlePosB : 31|8@0+ (0.392157,0) [0|100] "%" OnBoardDiagnostics
 SG_ S1_PID_48_AbsThrottlePosC : 31|8@0+ (0.392157,0) [0|100] "%" OnBoardDiagnostics
 SG_ S1_PID_49_AbsThrottlePosD : 31|8@0+ (0.392157,0) [0|100] "%" OnBoardDiagnostics
 SG_ S1_PID_4A_AbsThrottlePosE : 31|8@0+ (0.392157,0) [0|100] "%" OnBoardDiagnostics
 SG_ S1_PID_4B_AbsThrottlePosF : 31|8@0+ (0.392157,0) [0|100] "%" OnBoardDiagnostics
 SG_ S1_PID_4C_CmdThrottleAct : 31|8@0+ (0.392157,0) [0|100] "%" OnBoardDiagnostics
 SG_ S1_PID_4D_TimeRunMILOn : 31|16@0+ (1,0) [0|65535] "minutes" OnBoardDiagnostics
 SG_ S1_PID_4E_TimeSinceCodeClear : 31|16@0+ (1,0) [0|65535] "minutes" OnBoardDiagnostics
 SG_ S1_PID_4F_Max_FAER : 31|8@0+ (1,0) [0|255] "ratio" OnBoardDiagnostics
 SG_ S1_PID_4F_Max_IntManiAbsPres : 55|8@0+ (10,0) [0|2550] "kPa" OnBoardDiagnostics
 SG_ S1_PID_4F_Max_OxySensCrnt : 47|8@0+ (1,0) [0|255] "mA" OnBoardDiagnostics
 SG_ S1_PID_4F_Max_OxySensVol : 39|8@0+ (1,0) [0|255] "V" OnBoardDiagnostics
 SG_ S1_PID_50_Max_AirFlowMAF : 31|8@0+ (10,0) [0|2550] "g/s" OnBoardDiagnostics
 SG_ S1_PID_51_FuelType : 31|8@0+ (1,0) [0|255] "" OnBoardDiagnostics
 SG_ S1_PID_52_EthanolFuelPct : 31|8@0+ (0.392157,0) [0|100] "%" OnBoardDiagnostics
 SG_ S1_PID_53_AbsEvapSysVapPres : 31|16@0+ (0.005,0) [0|327.675] "kPa" OnBoardDiagnostics
 SG_ S1_PID_54_EvapSysVapPres : 31|16@0+ (1,-32767) [-32767|32768] "Pa" OnBoardDiagnostics
 SG_ S1_PID_55_ShortSecOxyTrimBank1 : 31|8@0+ (0.78125,-100) [-100|99.2188] "%" OnBoardDiagnostics
 SG_ S1_PID_55_ShortSecOxyTrimBank3 : 39|8@0+ (0.78125,-100) [-100|99.2188] "%" OnBoardDiagnostics
 SG_ S1_PID_56_LongSecOxyTrimBank1 : 31|8@0+ (0.78125,-100) [-100|99.2188] "%" OnBoardDiagnostics
 SG_ S1_PID_56_LongSecOxyTrimBank3 : 39|8@0+ (0.78125,-100) [-100|99.2188] "%" OnBoardDiagnostics
 SG_ S1_PID_57_ShortSecOxyTrimBank2 : 31|8@0+ (0.78125,-100) [-100|99.2188] "%" OnBoardDiagnostics
 SG_ S1_PID_57_ShortSecOxyTrimBank4 : 39|8@0+ (0.78125,-100) [-100|99.2188] "%" OnBoardDiagnostics
 SG_ S1_PID_58_LongSecOxyTrimBank2 : 31|8@0+ (0.78125,-100) [-100|99.2188] "%" OnBoardDiagnostics
 SG_ S1_PID_58_LongSecOxyTrimBank4 : 39|8@0+ (0.78125,-100) [-100|99.2188] "%" OnBoardDiagnostics
 SG_ S1_PID_59_FuelRailAbsPres : 31|16@0+ (10,0) [0|655350] "kPa" OnBoardDiagnostics
 SG_ S1_PID_5A_RelAccelPedalPos : 31|8@0+ (0.392157,0) [0|100] "%" OnBoardDiagnostics
 SG_ S1_PID_5C_EngineOilTemp : 31|8@0+ (1,-40) [-40|215] "degC" OnBoardDiagnostics
 SG_ S1_PID_5D_FuelInjectionTiming : 31|16@0+ (0.0078125,-210) [-210|301.992] "deg" OnBoardDiagnostics
 SG_ S1_PID_5E_EngineFuelRate : 31|16@0+ (0.05,0) [0|3276.75] "L/h" OnBoardDiagnostics
 SG_ S1_PID_5F_EmissionReq : 31|8@0+ (1,0) [0|255] "" OnBoardDiagnostics
 SG_ S1_PID_60_PIDsSupported_61_80 : 31|32@0+ (1,0) [0|4.29497] "" OnBoardDiagnostics
 SG_ S1_PID_61_DemandEngTorqPct : 31|8@0+ (1,-125) [-125|130] "%" OnBoardDiagnostics
 SG_ S1_PID_62_ActualEngTorqPct : 31|8@0+ (1,-125) [-125|130] "%" OnBoardDiagnostics
 SG_ S1_PID_63_EngRefTorq : 31|16@0+ (1,0) [0|65535] "Nm" OnBoardDiagnostics
 SG_ S1_PID_64_EngPctTorq_EP1 : 39|8@0+ (1,-125) [-125|130] "%" OnBoardDiagnostics
 SG_ S1_PID_64_EngPctTorq_EP2 : 47|8@0+ (1,-125) [-125|130] "%" OnBoardDiagnostics
 SG_ S1_PID_64_EngPctTorq_EP3 : 55|8@0+ (1,-125) [-125|130] "%" OnBoardDiagnostics
 SG_ S1_PID_64_EngPctTorq_EP4 : 63|8@0+ (1,-125) [-125|130] "%" OnBoardDiagnostics
 SG_ S1_PID_64_EngPctTorq_Idle : 31|8@0+ (1,-125) [-125|130] "%" OnBoardDiagnostics
 SG_ S1_PID_65_AuxInputOutput : 31|8@0+ (1,0) [0|255] "" OnBoardDiagnostics
 SG_ S1_PID_66_MAFSensor : 31|8@0+ (1,0) [0|255] "" OnBoardDiagnostics
 SG_ S1_PID_67_EngineCoolantTemp : 31|8@0+ (1,0) [0|255] "" OnBoardDiagnostics
 SG_ S1_PID_68_IntakeAirTempSens : 31|8@0+ (1,0) [0|255] "" OnBoardDiagnostics
 SG_ S1_PID_6B_ExhaustGasTemp : 31|8@0+ (1,0) [0|255] "" OnBoardDiagnostics
 SG_ S1_PID_6C_CmdThrottleActRel : 31|8@0+ (1,0) [0|255] "" OnBoardDiagnostics
 SG_ S1_PID_6D_FuelPresContrSys : 31|8@0+ (1,0) [0|255] "" OnBoardDiagnostics
 SG_ S1_PID_6E_InjPresContrSys : 31|8@0+ (1,0) [0|255] "" OnBoardDiagnostics
 SG_ S1_PID_6F_TurboComprPres : 31|8@0+ (1,0) [0|255] "" OnBoardDiagnostics
 SG_ S1_PID_70_BoostPresCntrl : 31|8@0+ (1,0) [0|255] "" OnBoardDiagnostics
 SG_ S1_PID_80_PIDsSupported_81_A0 : 31|32@0+ (1,0) [0|4.29497] "" OnBoardDiagnostics
 SG_ S1_PID_8E_EngFrictionPctTorq : 31|8@0+ (1,-125) [-125|130] "%" OnBoardDiagnostics
 SG_ S1_PID_A0_PIDsSupported_A1_C0 : 31|32@0+ (1,0) [0|4.29497] "" OnBoardDiagnostics
 SG_ S1_PID_C0_PIDsSupported_C1_E0 : 31|32@0+ (1,0) [0|4.29497] "" OnBoardDiagnostics
 SG_ S2_PID_02_FreezeDTC : 31|16@0+ (1,0) [0|65535] "" OnBoardDiagnostics
 SG_ response : 15|4@0+ (1,0) [0|15] "" OnBoardDiagnostics
 SG_ length : 7|8@0+ (1,0) [0|255] "" OnBoardDiagnostics
 SG_ service : 11|4@0+ (1,0) [0|15] "" OnBoardDiagnostics

BO_ 2025 TCM_DiagSig_Tx: 8 Transmission_Control_Module
 SG_ Data_Length_Packet_B0 : 0|8@1+ (1,0) [0|255] "" Vector__XXX
 SG_ Response_B1 : 8|8@1+ (1,0) [0|255] "" Vector__XXX
 SG_ Echo_Request_B2 : 16|8@1+ (1,0) [0|255] "" Vector__XXX
 SG_ Error_Code_ID_B3 : 24|8@1+ (1,0) [0|255] "" Vector__XXX
 SG_ Parameters_B4 : 32|8@1+ (1,0) [0|255] "" Vector__XXX
 SG_ Parameters_B5 : 40|8@1+ (1,0) [0|255] "" Vector__XXX
 SG_ Parameters_B6 : 48|8@1+ (1,0) [0|255] "" Vector__XXX
 SG_ Parameters_B7 : 56|8@1+ (1,0) [0|255] "" Vector__XXX

BO_ 259282800 _6B_FB_3E_B9_B9_DA_DD_DE: 8 Instrument_Cluster
 SG_ RawByte0_B0 : 0|8@1+ (1,0) [0|255] "" Vector__XXX
 SG_ RawByte1_B1 : 8|8@1+ (1,0) [0|255] "" Vector__XXX
 SG_ RawByte2_B2 : 16|8@1+ (1,0) [0|255] "" Vector__XXX
 SG_ RawByte3_B3 : 24|8@1+ (1,0) [0|255] "" Vector__XXX
 SG_ RawByte4_B4 : 32|8@1+ (1,0) [0|255] "" Vector__XXX
 SG_ RawByte5_B5 : 40|8@1+ (1,0) [0|255] "" Vector__XXX
 SG_ RawByte6_B6 : 48|8@1+ (1,0) [0|255] "" Vector__XXX
 SG_ RawByte7_B7 : 56|8@1+ (1,0) [0|255] "" Vector__XXX

CM_ BO_ 0 "Bus: Unknown bus. Source: DbcDatabaseFile row 84.";
BA_ "Bus" BO_ 0 "Unknown bus";
CM_ BO_ 1 "Bus: HS-CAN. Source: overview byte map. Overview names: Current Data | Overview ECUs/modules: On Board Diagnostics";
BA_ "Bus" BO_ 1 "HS-CAN";
CM_ SG_ 1 Data_Length_Packet_B0 "Overview byte 0: Data Length Packet";
CM_ SG_ 1 Mode_1_B1 "Overview byte 1: Mode 1";
CM_ SG_ 1 Parameters_B2 "Overview byte 2: Parameters";
CM_ SG_ 1 Parameters_B3 "Overview byte 3: Parameters";
CM_ SG_ 1 Parameters_B4 "Overview byte 4: Parameters";
CM_ SG_ 1 Parameters_B5 "Overview byte 5: Parameters";
CM_ SG_ 1 Parameters_B6 "Overview byte 6: Parameters";
CM_ SG_ 1 Parameters_B7 "Overview byte 7: Parameters";
CM_ BO_ 2 "Bus: HS-CAN. Source: overview byte map. Overview names: Freeze Frame Data | Overview ECUs/modules: On Board Diagnostics";
BA_ "Bus" BO_ 2 "HS-CAN";
CM_ SG_ 2 Data_Length_Packet_B0 "Overview byte 0: Data Length Packet";
CM_ SG_ 2 Mode_2_B1 "Overview byte 1: Mode 2";
CM_ SG_ 2 Parameters_B2 "Overview byte 2: Parameters";
CM_ SG_ 2 Parameters_B3 "Overview byte 3: Parameters";
CM_ SG_ 2 Parameters_B4 "Overview byte 4: Parameters";
CM_ SG_ 2 Parameters_B5 "Overview byte 5: Parameters";
CM_ SG_ 2 Parameters_B6 "Overview byte 6: Parameters";
CM_ SG_ 2 Parameters_B7 "Overview byte 7: Parameters";
CM_ BO_ 3 "Bus: HS-CAN. Source: overview byte map. Overview names: Diagnostic Trouble Codes | Overview ECUs/modules: On Board Diagnostics";
BA_ "Bus" BO_ 3 "HS-CAN";
CM_ SG_ 3 Data_Length_Packet_B0 "Overview byte 0: Data Length Packet";
CM_ SG_ 3 Mode_3_B1 "Overview byte 1: Mode 3";
CM_ SG_ 3 Parameters_B2 "Overview byte 2: Parameters";
CM_ SG_ 3 Parameters_B3 "Overview byte 3: Parameters";
CM_ SG_ 3 Parameters_B4 "Overview byte 4: Parameters";
CM_ SG_ 3 Parameters_B5 "Overview byte 5: Parameters";
CM_ SG_ 3 Parameters_B6 "Overview byte 6: Parameters";
CM_ SG_ 3 Parameters_B7 "Overview byte 7: Parameters";
CM_ BO_ 4 "Bus: HS-CAN. Source: overview byte map. Overview names: Clear Trouble Code | Overview ECUs/modules: On Board Diagnostics";
BA_ "Bus" BO_ 4 "HS-CAN";
CM_ SG_ 4 Data_Length_Packet_B0 "Overview byte 0: Data Length Packet";
CM_ SG_ 4 Mode_4_B1 "Overview byte 1: Mode 4";
CM_ SG_ 4 Parameters_B2 "Overview byte 2: Parameters";
CM_ SG_ 4 Parameters_B3 "Overview byte 3: Parameters";
CM_ SG_ 4 Parameters_B4 "Overview byte 4: Parameters";
CM_ SG_ 4 Parameters_B5 "Overview byte 5: Parameters";
CM_ SG_ 4 Parameters_B6 "Overview byte 6: Parameters";
CM_ SG_ 4 Parameters_B7 "Overview byte 7: Parameters";
CM_ BO_ 5 "Bus: HS-CAN. Source: overview byte map. Overview names: Test Results/Oxygen Sensors | Overview ECUs/modules: On Board Diagnostics";
BA_ "Bus" BO_ 5 "HS-CAN";
CM_ SG_ 5 Data_Length_Packet_B0 "Overview byte 0: Data Length Packet";
CM_ SG_ 5 Mode_5_B1 "Overview byte 1: Mode 5";
CM_ SG_ 5 Parameters_B2 "Overview byte 2: Parameters";
CM_ SG_ 5 Parameters_B3 "Overview byte 3: Parameters";
CM_ SG_ 5 Parameters_B4 "Overview byte 4: Parameters";
CM_ SG_ 5 Parameters_B5 "Overview byte 5: Parameters";
CM_ SG_ 5 Parameters_B6 "Overview byte 6: Parameters";
CM_ SG_ 5 Parameters_B7 "Overview byte 7: Parameters";
CM_ BO_ 6 "Bus: HS-CAN. Source: overview byte map. Overview names: Test Results/Non-Continuous Testing | Overview ECUs/modules: On Board Diagnostics";
BA_ "Bus" BO_ 6 "HS-CAN";
CM_ SG_ 6 Data_Length_Packet_B0 "Overview byte 0: Data Length Packet";
CM_ SG_ 6 Mode_6_B1 "Overview byte 1: Mode 6";
CM_ SG_ 6 Parameters_B2 "Overview byte 2: Parameters";
CM_ SG_ 6 Parameters_B3 "Overview byte 3: Parameters";
CM_ SG_ 6 Parameters_B4 "Overview byte 4: Parameters";
CM_ SG_ 6 Parameters_B5 "Overview byte 5: Parameters";
CM_ SG_ 6 Parameters_B6 "Overview byte 6: Parameters";
CM_ SG_ 6 Parameters_B7 "Overview byte 7: Parameters";
CM_ BO_ 7 "Bus: HS-CAN. Source: overview byte map. Overview names: Show Pending Trouble Codes | Overview ECUs/modules: On Board Diagnostics";
BA_ "Bus" BO_ 7 "HS-CAN";
CM_ SG_ 7 Data_Length_Packet_B0 "Overview byte 0: Data Length Packet";
CM_ SG_ 7 Mode_7_B1 "Overview byte 1: Mode 7";
CM_ SG_ 7 Parameters_B2 "Overview byte 2: Parameters";
CM_ SG_ 7 Parameters_B3 "Overview byte 3: Parameters";
CM_ SG_ 7 Parameters_B4 "Overview byte 4: Parameters";
CM_ SG_ 7 Parameters_B5 "Overview byte 5: Parameters";
CM_ SG_ 7 Parameters_B6 "Overview byte 6: Parameters";
CM_ SG_ 7 Parameters_B7 "Overview byte 7: Parameters";
CM_ BO_ 8 "Bus: HS-CAN. Source: overview byte map. Overview names: Special Control Mode | Overview ECUs/modules: On Board Diagnostics";
BA_ "Bus" BO_ 8 "HS-CAN";
CM_ SG_ 8 Data_Length_Packet_B0 "Overview byte 0: Data Length Packet";
CM_ SG_ 8 Mode_8_B1 "Overview byte 1: Mode 8";
CM_ SG_ 8 Parameters_B2 "Overview byte 2: Parameters";
CM_ SG_ 8 Parameters_B3 "Overview byte 3: Parameters";
CM_ SG_ 8 Parameters_B4 "Overview byte 4: Parameters";
CM_ SG_ 8 Parameters_B5 "Overview byte 5: Parameters";
CM_ SG_ 8 Parameters_B6 "Overview byte 6: Parameters";
CM_ SG_ 8 Parameters_B7 "Overview byte 7: Parameters";
CM_ BO_ 9 "Bus: HS-CAN. Source: overview byte map. Overview names: Request Vehicle Information | Overview ECUs/modules: On Board Diagnostics";
BA_ "Bus" BO_ 9 "HS-CAN";
CM_ SG_ 9 Data_Length_Packet_B0 "Overview byte 0: Data Length Packet";
CM_ SG_ 9 Mode_9_B1 "Overview byte 1: Mode 9";
CM_ SG_ 9 Parameters_B2 "Overview byte 2: Parameters";
CM_ SG_ 9 Parameters_B3 "Overview byte 3: Parameters";
CM_ SG_ 9 Parameters_B4 "Overview byte 4: Parameters";
CM_ SG_ 9 Parameters_B5 "Overview byte 5: Parameters";
CM_ SG_ 9 Parameters_B6 "Overview byte 6: Parameters";
CM_ SG_ 9 Parameters_B7 "Overview byte 7: Parameters";
CM_ BO_ 10 "Bus: HS-CAN. Source: overview byte map. Overview names: Request Permanent Trouble Codes | Overview ECUs/modules: On Board Diagnostics";
BA_ "Bus" BO_ 10 "HS-CAN";
CM_ SG_ 10 Data_Length_Packet_B0 "Overview byte 0: Data Length Packet";
CM_ SG_ 10 Mode_10_B1 "Overview byte 1: Mode 10";
CM_ SG_ 10 Parameters_B2 "Overview byte 2: Parameters";
CM_ SG_ 10 Parameters_B3 "Overview byte 3: Parameters";
CM_ SG_ 10 Parameters_B4 "Overview byte 4: Parameters";
CM_ SG_ 10 Parameters_B5 "Overview byte 5: Parameters";
CM_ SG_ 10 Parameters_B6 "Overview byte 6: Parameters";
CM_ SG_ 10 Parameters_B7 "Overview byte 7: Parameters";
CM_ BO_ 12 "Bus: MS-CAN. Source: overview byte map. Overview names: InputOutputControlByIdentifier, NegativeResponseError, generalReject, serviceNotSupported, subFunctionNotSupported, responseTooLong, busyRepeatRequest, conditionsNotCorrect, requestSequenceError, u | Overview ECUs/modules: NegativeResponseError, InputOutputControlByIdentifier";
BA_ "Bus" BO_ 12 "MS-CAN";
CM_ SG_ 12 Data_Length_Packet_B0 "Overview byte 0: Data Length Packet";
CM_ SG_ 12 Negative_Response_Code_B1 "Overview byte 1: Negative Response Code";
CM_ SG_ 12 Error_Identifier_B2 "Overview byte 2: Error Identifier";
CM_ SG_ 12 Request_Echo_B3 "Overview byte 3: Request Echo";
CM_ SG_ 12 RawByte4_B4 "Overview byte 4: RawByte4";
CM_ SG_ 12 RawByte5_B5 "Overview byte 5: RawByte5";
CM_ SG_ 12 RawByte6_B6 "Overview byte 6: RawByte6";
CM_ SG_ 12 RawByte7_B7 "Overview byte 7: RawByte7";
CM_ BO_ 80 "Bus: Unknown bus. Source: DbcDatabaseFile row 36.";
BA_ "Bus" BO_ 80 "Unknown bus";
CM_ BO_ 112 "Bus: HS-CAN. Source: uploaded highSpeedCAN.dbc.";
BA_ "Bus" BO_ 112 "HS-CAN";
CM_ BO_ 117 "Bus: HS-CAN. Source: uploaded highSpeedCAN.dbc.";
BA_ "Bus" BO_ 117 "HS-CAN";
CM_ BO_ 128 "Bus: HS-CAN. Source: uploaded highSpeedCAN.dbc.";
BA_ "Bus" BO_ 128 "HS-CAN";
CM_ BO_ 133 "Bus: HS-CAN. Source: uploaded highSpeedCAN.dbc.";
BA_ "Bus" BO_ 133 "HS-CAN";
CM_ BO_ 144 "Bus: HS-CAN. Source: uploaded highSpeedCAN.dbc.";
BA_ "Bus" BO_ 144 "HS-CAN";
CM_ BO_ 151 "Bus: HS-CAN. Source: uploaded highSpeedCAN.dbc.";
BA_ "Bus" BO_ 151 "HS-CAN";
CM_ BO_ 201 "Bus: HS-CAN. Source: uploaded highSpeedCAN.dbc.";
BA_ "Bus" BO_ 201 "HS-CAN";
CM_ BO_ 252 "Bus: HS-CAN. Source: uploaded highSpeedCAN.dbc.";
BA_ "Bus" BO_ 252 "HS-CAN";
CM_ BO_ 288 "Bus: HS-CAN. Source: uploaded highSpeedCAN.dbc.";
BA_ "Bus" BO_ 288 "HS-CAN";
CM_ BO_ 296 "Bus: HS-CAN. Source: DbcDatabaseFile row 106, DbcDatabaseFile row 399, uploaded highSpeedCAN.dbc. Alternative message name from source: MSCAN_LightsAndIllumination | Also present on MSCAN in source data.";
BA_ "Bus" BO_ 296 "HS-CAN";
CM_ BO_ 301 "Bus: HS-CAN. Source: uploaded highSpeedCAN.dbc.";
BA_ "Bus" BO_ 301 "HS-CAN";
CM_ BO_ 471 "Bus: HS-CAN. Source: overview byte map. Overview names: FE 9D DF E6 63 F4 B6 | Overview ECUs/modules: Instrument Cluster | Alternative message name from source: MSCAN_Remote_Request_Frame | Also present on MSCAN in source data.";
BA_ "Bus" BO_ 471 "HS-CAN";
CM_ SG_ 471 RawByte0_B0 "Overview byte 0: RawByte0";
CM_ SG_ 471 RawByte1_B1 "Overview byte 1: RawByte1";
CM_ SG_ 471 RawByte2_B2 "Overview byte 2: RawByte2";
CM_ SG_ 471 RawByte3_B3 "Overview byte 3: RawByte3";
CM_ SG_ 471 RawByte4_B4 "Overview byte 4: RawByte4";
CM_ SG_ 471 RawByte5_B5 "Overview byte 5: RawByte5";
CM_ SG_ 471 RawByte6_B6 "Overview byte 6: RawByte6";
CM_ SG_ 471 Remote_Request_Frame_B0 "Overview byte 0: Remote Request Frame";
CM_ BO_ 512 "Bus: HS-CAN. Source: uploaded highSpeedCAN.dbc.";
BA_ "Bus" BO_ 512 "HS-CAN";
CM_ BO_ 519 "Bus: HS-CAN. Source: uploaded highSpeedCAN.dbc.";
BA_ "Bus" BO_ 519 "HS-CAN";
CM_ BO_ 528 "Bus: HS-CAN. Source: uploaded highSpeedCAN.dbc.";
BA_ "Bus" BO_ 528 "HS-CAN";
CM_ BO_ 560 "Bus: HS-CAN. Source: uploaded highSpeedCAN.dbc.";
BA_ "Bus" BO_ 560 "HS-CAN";
CM_ BO_ 704 "Bus: MS-CAN. Source: overview byte map. Overview names: Bluetooth Menu/Pairing Ascii Data | Overview ECUs/modules: Bluetooth Phone Module";
BA_ "Bus" BO_ 704 "MS-CAN";
CM_ SG_ 704 Ascii_Data_B0 "Overview byte 0: Ascii Data";
CM_ SG_ 704 Ascii_Data_B1 "Overview byte 1: Ascii Data";
CM_ SG_ 704 Ascii_Data_B2 "Overview byte 2: Ascii Data";
CM_ SG_ 704 Ascii_Data_B3 "Overview byte 3: Ascii Data";
CM_ SG_ 704 Ascii_Data_B4 "Overview byte 4: Ascii Data";
CM_ SG_ 704 Ascii_Data_B5 "Overview byte 5: Ascii Data";
CM_ SG_ 704 Ascii_Data_B6 "Overview byte 6: Ascii Data";
CM_ SG_ 704 Ascii_Data_B7 "Overview byte 7: Ascii Data";
CM_ BO_ 705 "Bus: MS-CAN. Source: overview byte map. Overview names: Bluetooth Menu Open | Overview ECUs/modules: Bluetooth Phone Module";
BA_ "Bus" BO_ 705 "MS-CAN";
CM_ SG_ 705 Phone_Call_Active_B0 "Overview byte 0: Phone Call Active";
CM_ SG_ 705 RawByte1_B1 "Overview byte 1: RawByte1";
CM_ SG_ 705 RawByte2_B2 "Overview byte 2: RawByte2";
CM_ SG_ 705 RawByte3_B3 "Overview byte 3: RawByte3";
CM_ SG_ 705 RawByte4_B4 "Overview byte 4: RawByte4";
CM_ SG_ 705 RawByte5_B5 "Overview byte 5: RawByte5";
CM_ SG_ 705 RawByte6_B6 "Overview byte 6: RawByte6";
CM_ SG_ 705 RawByte7_B7 "Overview byte 7: RawByte7";
CM_ BO_ 708 "Bus: MS-CAN. Source: overview byte map. Overview names: Bluetooth Signal | Overview ECUs/modules: Bluetooth Phone Module";
BA_ "Bus" BO_ 708 "MS-CAN";
CM_ SG_ 708 Menu_Active_B0 "Overview byte 0: Menu Active";
CM_ SG_ 708 RawByte1_B1 "Overview byte 1: RawByte1";
CM_ SG_ 708 RawByte2_B2 "Overview byte 2: RawByte2";
CM_ SG_ 708 RawByte3_B3 "Overview byte 3: RawByte3";
CM_ SG_ 708 RawByte4_B4 "Overview byte 4: RawByte4";
CM_ SG_ 708 RawByte5_B5 "Overview byte 5: RawByte5";
CM_ SG_ 708 RawByte6_B6 "Overview byte 6: RawByte6";
CM_ SG_ 708 RawByte7_B7 "Overview byte 7: RawByte7";
CM_ BO_ 714 "Bus: MS-CAN. Source: DbcDatabaseFile row 153.";
BA_ "Bus" BO_ 714 "MS-CAN";
CM_ BO_ 716 "Bus: MS-CAN. Source: overview byte map. Overview names: BPM Operating State | Overview ECUs/modules: Bluetooth Phone Module";
BA_ "Bus" BO_ 716 "MS-CAN";
CM_ SG_ 716 RawByte0_B0 "Overview byte 0: RawByte0";
CM_ SG_ 716 RawByte1_B1 "Overview byte 1: RawByte1";
CM_ SG_ 716 RawByte2_B2 "Overview byte 2: RawByte2";
CM_ SG_ 716 RawByte3_B3 "Overview byte 3: RawByte3";
CM_ SG_ 716 RawByte4_B4 "Overview byte 4: RawByte4";
CM_ SG_ 716 RawByte5_B5 "Overview byte 5: RawByte5";
CM_ SG_ 716 RawByte6_B6 "Overview byte 6: RawByte6";
CM_ SG_ 716 RawByte7_B7 "Overview byte 7: RawByte7";
CM_ BO_ 717 "Bus: MS-CAN. Source: overview byte map. Overview names: Incoming Call,  Call in Progress, Call End, Re-Dial, Voice Tag | Overview ECUs/modules: Bluetooth Phone Module";
BA_ "Bus" BO_ 717 "MS-CAN";
CM_ SG_ 717 RawByte0_B0 "Overview byte 0: RawByte0";
CM_ SG_ 717 RawByte1_B1 "Overview byte 1: RawByte1";
CM_ SG_ 717 RawByte2_B2 "Overview byte 2: RawByte2";
CM_ SG_ 717 RawByte3_B3 "Overview byte 3: RawByte3";
CM_ SG_ 717 RawByte4_B4 "Overview byte 4: RawByte4";
CM_ SG_ 717 RawByte5_B5 "Overview byte 5: RawByte5";
CM_ SG_ 717 RawByte6_B6 "Overview byte 6: RawByte6";
CM_ SG_ 717 RawByte7_B7 "Overview byte 7: RawByte7";
CM_ BO_ 718 "Bus: MS-CAN. Source: DbcDatabaseFile row 160.";
BA_ "Bus" BO_ 718 "MS-CAN";
CM_ BO_ 719 "Bus: MS-CAN. Source: overview byte map. Overview names: Bluetooth Phone Module | Overview ECUs/modules: Bluetooth Phone Module";
BA_ "Bus" BO_ 719 "MS-CAN";
CM_ SG_ 719 cangen_can0_g_10_I_2D4_L_8_D_333333333333333333_Percent_B0 "Overview byte 0: cangen can0 -g 10 -I 2D4 -L 8 -D 333333333333333333 &";
CM_ SG_ 719 RawByte1_B1 "Overview byte 1: RawByte1";
CM_ SG_ 719 RawByte2_B2 "Overview byte 2: RawByte2";
CM_ SG_ 719 RawByte3_B3 "Overview byte 3: RawByte3";
CM_ SG_ 719 RawByte4_B4 "Overview byte 4: RawByte4";
CM_ SG_ 719 RawByte5_B5 "Overview byte 5: RawByte5";
CM_ SG_ 719 RawByte6_B6 "Overview byte 6: RawByte6";
CM_ SG_ 719 RawByte7_B7 "Overview byte 7: RawByte7";
CM_ BO_ 722 "Bus: MS-CAN. Source: overview byte map. Overview names: Ipod Menu & Filesystem | Overview ECUs/modules: Audio Interface Module";
BA_ "Bus" BO_ 722 "MS-CAN";
CM_ SG_ 722 Security_Status_B0 "Overview byte 0: Security Status";
CM_ SG_ 722 Authentication_Device_Error_Code_B1 "Overview byte 1: Authentication Device Error Code";
CM_ SG_ 722 RawByte2_B2 "Overview byte 2: RawByte2";
CM_ SG_ 722 RawByte3_B3 "Overview byte 3: RawByte3";
CM_ SG_ 722 RawByte4_B4 "Overview byte 4: RawByte4";
CM_ SG_ 722 RawByte5_B5 "Overview byte 5: RawByte5";
CM_ SG_ 722 RawByte6_B6 "Overview byte 6: RawByte6";
CM_ SG_ 722 RawByte7_B7 "Overview byte 7: RawByte7";
CM_ BO_ 723 "Bus: MS-CAN. Source: overview byte map. Overview names: Ipod Serial Data | Overview ECUs/modules: Audio Interface Module";
BA_ "Bus" BO_ 723 "MS-CAN";
CM_ SG_ 723 Number_of_continuous_DTCs_stored_B0 "Overview byte 0: Number of continuous DTCs stored";
CM_ SG_ 723 Consumer_Device_Error_Count_B1 "Overview byte 1: Consumer Device Error Count";
CM_ SG_ 723 RawByte2_B2 "Overview byte 2: RawByte2";
CM_ SG_ 723 RawByte3_B3 "Overview byte 3: RawByte3";
CM_ SG_ 723 RawByte4_B4 "Overview byte 4: RawByte4";
CM_ SG_ 723 RawByte5_B5 "Overview byte 5: RawByte5";
CM_ SG_ 723 RawByte6_B6 "Overview byte 6: RawByte6";
CM_ SG_ 723 RawByte7_B7 "Overview byte 7: RawByte7";
CM_ BO_ 724 "Bus: MS-CAN. Source: overview byte map. Overview names: Consumer Device Not Connected | Overview ECUs/modules: Audio Interface Module";
BA_ "Bus" BO_ 724 "MS-CAN";
CM_ SG_ 724 Consumer_Device_Model_ID_B0 "Overview byte 0: Consumer Device Model ID";
CM_ SG_ 724 Ipod_Track_Time_B1 "Overview byte 1: Ipod Track Time";
CM_ SG_ 724 iPod_Firmware_Version_Number_B2 "Overview byte 2: iPod Firmware Version Number";
CM_ SG_ 724 RawByte3_B3 "Overview byte 3: RawByte3";
CM_ SG_ 724 Ipod_Mode_B4 "Overview byte 4: Ipod Mode";
CM_ SG_ 724 Ipod_Controls_B5 "Overview byte 5: Ipod Controls";
CM_ SG_ 724 Ipod_Mode_B6 "Overview byte 6: Ipod Mode";
CM_ SG_ 724 Ipod_Mode_B7 "Overview byte 7: Ipod Mode";
CM_ BO_ 725 "Bus: Unknown bus. Source: DbcDatabaseFile row 44.";
BA_ "Bus" BO_ 725 "Unknown bus";
CM_ BO_ 737 "Bus: MS-CAN. Source: overview byte map. Overview names: Audio Mode Switches | Overview ECUs/modules: Audio Control Module";
BA_ "Bus" BO_ 737 "MS-CAN";
CM_ SG_ 737 Audio_Mode_Switch_B0 "Overview byte 0: Audio Mode Switch";
CM_ SG_ 737 RawByte1_B1 "Overview byte 1: RawByte1";
CM_ SG_ 737 RawByte2_B2 "Overview byte 2: RawByte2";
CM_ SG_ 737 RawByte3_B3 "Overview byte 3: RawByte3";
CM_ SG_ 737 RawByte4_B4 "Overview byte 4: RawByte4";
CM_ SG_ 737 RawByte5_B5 "Overview byte 5: RawByte5";
CM_ SG_ 737 RawByte6_B6 "Overview byte 6: RawByte6";
CM_ SG_ 737 RawByte7_B7 "Overview byte 7: RawByte7";
CM_ BO_ 738 "Bus: MS-CAN. Source: overview byte map. Overview names: Audio Mode Switches | Overview ECUs/modules: Audio Control Module";
BA_ "Bus" BO_ 738 "MS-CAN";
CM_ SG_ 738 Audio_Mode_Switch_B0 "Overview byte 0: Audio Mode Switch";
CM_ SG_ 738 RawByte1_B1 "Overview byte 1: RawByte1";
CM_ SG_ 738 RawByte2_B2 "Overview byte 2: RawByte2";
CM_ SG_ 738 RawByte3_B3 "Overview byte 3: RawByte3";
CM_ SG_ 738 RawByte4_B4 "Overview byte 4: RawByte4";
CM_ SG_ 738 RawByte5_B5 "Overview byte 5: RawByte5";
CM_ SG_ 738 RawByte6_B6 "Overview byte 6: RawByte6";
CM_ SG_ 738 RawByte7_B7 "Overview byte 7: RawByte7";
CM_ BO_ 739 "Bus: MS-CAN. Source: overview byte map. Overview names: Phone, AUX2 switcher | Overview ECUs/modules: Audio Control Module";
BA_ "Bus" BO_ 739 "MS-CAN";
CM_ SG_ 739 Audio_Mode_Switch_B0 "Overview byte 0: Audio Mode Switch";
CM_ SG_ 739 RawByte1_B1 "Overview byte 1: RawByte1";
CM_ SG_ 739 RawByte2_B2 "Overview byte 2: RawByte2";
CM_ SG_ 739 RawByte3_B3 "Overview byte 3: RawByte3";
CM_ SG_ 739 RawByte4_B4 "Overview byte 4: RawByte4";
CM_ SG_ 739 RawByte5_B5 "Overview byte 5: RawByte5";
CM_ SG_ 739 RawByte6_B6 "Overview byte 6: RawByte6";
CM_ SG_ 739 RawByte7_B7 "Overview byte 7: RawByte7";
CM_ BO_ 742 "Bus: MS-CAN. Source: DbcDatabaseFile row 170.";
BA_ "Bus" BO_ 742 "MS-CAN";
CM_ BO_ 748 "Bus: MS-CAN. Source: DbcDatabaseFile row 46.";
BA_ "Bus" BO_ 748 "MS-CAN";
CM_ BO_ 751 "Bus: MS-CAN. Source: DbcDatabaseFile row 48.";
BA_ "Bus" BO_ 751 "MS-CAN";
CM_ BO_ 754 "Bus: MS-CAN. Source: DbcDatabaseFile row 176.";
BA_ "Bus" BO_ 754 "MS-CAN";
CM_ BO_ 756 "Bus: MS-CAN. Source: DbcDatabaseFile row 181.";
BA_ "Bus" BO_ 756 "MS-CAN";
CM_ BO_ 757 "Bus: MS-CAN. Source: DbcDatabaseFile row 191.";
BA_ "Bus" BO_ 757 "MS-CAN";
CM_ BO_ 758 "Bus: MS-CAN. Source: DbcDatabaseFile row 201.";
BA_ "Bus" BO_ 758 "MS-CAN";
CM_ BO_ 761 "Bus: MS-CAN. Source: DbcDatabaseFile row 211.";
BA_ "Bus" BO_ 761 "MS-CAN";
CM_ BO_ 764 "Bus: MS-CAN. Source: DbcDatabaseFile row 213.";
BA_ "Bus" BO_ 764 "MS-CAN";
CM_ BO_ 775 "Bus: HS-CAN. Source: DbcDatabaseFile row 223, DbcDatabaseFile row 515, uploaded highSpeedCAN.dbc. Alternative message name from source: MSCAN_InteriorCommandCentreBodyControl | Also present on MSCAN in source data.";
BA_ "Bus" BO_ 775 "HS-CAN";
CM_ BO_ 777 "Bus: MS-CAN. Source: DbcDatabaseFile row 234.";
BA_ "Bus" BO_ 777 "MS-CAN";
CM_ BO_ 779 "Bus: MS-CAN. Source: DbcDatabaseFile row 244.";
BA_ "Bus" BO_ 779 "MS-CAN";
CM_ BO_ 781 "Bus: MS-CAN. Source: DbcDatabaseFile row 247.";
BA_ "Bus" BO_ 781 "MS-CAN";
CM_ BO_ 783 "Bus: MS-CAN. Source: DbcDatabaseFile row 50.";
BA_ "Bus" BO_ 783 "MS-CAN";
CM_ BO_ 785 "Bus: MS-CAN. Source: DbcDatabaseFile row 252.";
BA_ "Bus" BO_ 785 "MS-CAN";
CM_ BO_ 787 "Bus: MS-CAN. Source: DbcDatabaseFile row 260.";
BA_ "Bus" BO_ 787 "MS-CAN";
CM_ BO_ 789 "Bus: MS-CAN. Source: DbcDatabaseFile row 263.";
BA_ "Bus" BO_ 789 "MS-CAN";
CM_ BO_ 791 "Bus: MS-CAN. Source: DbcDatabaseFile row 272.";
BA_ "Bus" BO_ 791 "MS-CAN";
CM_ BO_ 816 "Bus: MS-CAN. Source: DbcDatabaseFile row 52.";
BA_ "Bus" BO_ 816 "MS-CAN";
CM_ BO_ 829 "Bus: Unknown bus. Source: DbcDatabaseFile row 54.";
BA_ "Bus" BO_ 829 "Unknown bus";
CM_ BO_ 832 "Bus: HS-CAN. Source: DbcDatabaseFile row 275, DbcDatabaseFile row 425, uploaded highSpeedCAN.dbc. Alternative message name from source: MSCAN_RCM_STAT_DPLY_ENABLED_RCRD_MS | Also present on MSCAN in source data.";
BA_ "Bus" BO_ 832 "HS-CAN";
CM_ BO_ 848 "Bus: HS-CAN. Source: uploaded highSpeedCAN.dbc.";
BA_ "Bus" BO_ 848 "HS-CAN";
CM_ BO_ 851 "Bus: HS-CAN. Source: overview byte map, uploaded highSpeedCAN.dbc. Alternative message name from source: MSCAN_HVAC_ClimateStatus_MS | Also present on MSCAN in source data.";
BA_ "Bus" BO_ 851 "HS-CAN";
CM_ SG_ 851 VentStatus_B0 "Overview byte 0: VentStatus";
CM_ SG_ 851 PassengerTargetTemp_B1 "Overview byte 1: PassengerTargetTemp";
CM_ SG_ 851 PassengerTemp_B2 "Overview byte 2: PassengerTemp";
CM_ SG_ 851 DriverTargetTemp_B3 "Overview byte 3: DriverTargetTemp";
CM_ SG_ 851 DriverTemp_B4 "Overview byte 4: DriverTemp";
CM_ SG_ 851 ExteriorAmbientTemp_B5 "Overview byte 5: ExteriorAmbientTemp";
CM_ SG_ 851 FanSpeedActual_B6 "Overview byte 6: FanSpeedActual";
CM_ SG_ 851 FanSpeedTarget_B7 "Overview byte 7: FanSpeedTarget";
CM_ BO_ 864 "Bus: MS-CAN. Source: DbcDatabaseFile row 297.";
BA_ "Bus" BO_ 864 "MS-CAN";
CM_ BO_ 869 "Bus: MS-CAN. Source: DbcDatabaseFile row 56.";
BA_ "Bus" BO_ 869 "MS-CAN";
CM_ BO_ 1001 "Bus: HS-CAN. Source: uploaded highSpeedCAN.dbc.";
BA_ "Bus" BO_ 1001 "HS-CAN";
CM_ BO_ 1027 "Bus: HS-CAN. Source: overview byte map, uploaded highSpeedCAN.dbc. Alternative message name from source: MSCAN_BEM_Status_MS | Also present on MSCAN in source data.";
BA_ "Bus" BO_ 1027 "HS-CAN";
CM_ SG_ 1027 DoorStatus_Accessories_TrailerConnected_B0 "Overview byte 0: DoorStatus/Accessories/TrailerConnected";
CM_ SG_ 1027 PriorityKey_LightsOn_RearDemist_B1 "Overview byte 1: PriorityKey/LightsOn/RearDemist";
CM_ SG_ 1027 CabinTemperature_B2 "Overview byte 2: CabinTemperature";
CM_ SG_ 1027 SunloadDriver_B3 "Overview byte 3: SunloadDriver";
CM_ SG_ 1027 SunloadPassenger_B4 "Overview byte 4: SunloadPassenger";
CM_ SG_ 1027 Boot_B5 "Overview byte 5: Boot";
CM_ SG_ 1027 Windscreen_Wipers_B6 "Overview byte 6: Windscreen Wipers";
CM_ SG_ 1027 Locking_State_B7 "Overview byte 7: Locking State";
CM_ BO_ 1030 "Bus: MS-CAN. Source: DbcDatabaseFile row 323.";
BA_ "Bus" BO_ 1030 "MS-CAN";
CM_ BO_ 1031 "Bus: HS-CAN. Source: overview byte map. Overview names: ??? | Overview ECUs/modules: Body Electronic Module";
BA_ "Bus" BO_ 1031 "HS-CAN";
CM_ SG_ 1031 RawByte0_B0 "Overview byte 0: RawByte0";
CM_ SG_ 1031 RawByte1_B1 "Overview byte 1: RawByte1";
CM_ SG_ 1031 RawByte2_B2 "Overview byte 2: RawByte2";
CM_ SG_ 1031 RawByte3_B3 "Overview byte 3: RawByte3";
CM_ SG_ 1031 RawByte4_B4 "Overview byte 4: RawByte4";
CM_ SG_ 1031 RawByte5_B5 "Overview byte 5: RawByte5";
CM_ SG_ 1031 RawByte6_B6 "Overview byte 6: RawByte6";
CM_ SG_ 1031 RawByte7_B7 "Overview byte 7: RawByte7";
CM_ BO_ 1033 "Bus: MS-CAN. Source: DbcDatabaseFile row 59.";
BA_ "Bus" BO_ 1033 "MS-CAN";
CM_ BO_ 1061 "Bus: HS-CAN. Source: uploaded highSpeedCAN.dbc.";
BA_ "Bus" BO_ 1061 "HS-CAN";
CM_ BO_ 1063 "Bus: HS-CAN. Source: uploaded highSpeedCAN.dbc.";
BA_ "Bus" BO_ 1063 "HS-CAN";
CM_ BO_ 1079 "Bus: HS-CAN. Source: uploaded highSpeedCAN.dbc.";
BA_ "Bus" BO_ 1079 "HS-CAN";
CM_ BO_ 1101 "Bus: HS-CAN. Source: DbcDatabaseFile row 354, DbcDatabaseFile row 647, uploaded highSpeedCAN.dbc. Alternative message name from source: MSCAN_EngineOilTemperature | Also present on MSCAN in source data.";
BA_ "Bus" BO_ 1101 "HS-CAN";
CM_ BO_ 1107 "Bus: HS-CAN. Source: overview byte map, uploaded highSpeedCAN.dbc. Alternative message name from source: MSCAN_Odometer | Also present on MSCAN in source data.";
BA_ "Bus" BO_ 1107 "HS-CAN";
CM_ SG_ 1107 RawByte0_B0 "Overview byte 0: RawByte0";
CM_ SG_ 1107 RawByte1_B1 "Overview byte 1: RawByte1";
CM_ SG_ 1107 RawByte2_B2 "Overview byte 2: RawByte2";
CM_ SG_ 1107 RawByte3_B3 "Overview byte 3: RawByte3";
CM_ SG_ 1107 RawByte4_B4 "Overview byte 4: RawByte4";
CM_ SG_ 1107 RawByte5_B5 "Overview byte 5: RawByte5";
CM_ SG_ 1107 RawByte6_B6 "Overview byte 6: RawByte6";
CM_ SG_ 1107 RawByte7_B7 "Overview byte 7: RawByte7";
CM_ BO_ 1108 "Bus: HS-CAN. Source: DbcDatabaseFile row 74.";
BA_ "Bus" BO_ 1108 "HS-CAN";
CM_ BO_ 1200 "Bus: HS-CAN. Source: uploaded highSpeedCAN.dbc.";
BA_ "Bus" BO_ 1200 "HS-CAN";
CM_ BO_ 1216 "Bus: HS-CAN. Source: uploaded highSpeedCAN.dbc.";
BA_ "Bus" BO_ 1216 "HS-CAN";
CM_ BO_ 1280 "Bus: HS-CAN. Source: uploaded highSpeedCAN.dbc.";
BA_ "Bus" BO_ 1280 "HS-CAN";
CM_ BO_ 1281 "Bus: MS-CAN. Source: DbcDatabaseFile row 82.";
BA_ "Bus" BO_ 1281 "MS-CAN";
CM_ BO_ 1292 "Bus: MS-CAN. Source: DbcDatabaseFile row 375.";
BA_ "Bus" BO_ 1292 "MS-CAN";
CM_ BO_ 1297 "Bus: MS-CAN. Source: DbcDatabaseFile row 78.";
BA_ "Bus" BO_ 1297 "MS-CAN";
CM_ BO_ 1345 "Bus: MS-CAN. Source: overview byte map. Overview names: BEM_KeepAliveSignal | Overview ECUs/modules: Body Electronic Module";
BA_ "Bus" BO_ 1345 "MS-CAN";
CM_ SG_ 1345 Keep_Alive_Signal_B0 "Overview byte 0: Keep Alive Signal";
CM_ SG_ 1345 Keep_Alive_Signal_B1 "Overview byte 1: Keep Alive Signal";
CM_ SG_ 1345 Keep_Alive_Signal_B2 "Overview byte 2: Keep Alive Signal";
CM_ SG_ 1345 RawByte3_B3 "Overview byte 3: RawByte3";
CM_ SG_ 1345 RawByte4_B4 "Overview byte 4: RawByte4";
CM_ SG_ 1345 RawByte5_B5 "Overview byte 5: RawByte5";
CM_ SG_ 1345 RawByte6_B6 "Overview byte 6: RawByte6";
CM_ SG_ 1345 RawByte7_B7 "Overview byte 7: RawByte7";
CM_ BO_ 1363 "Bus: HS-CAN. Source: uploaded highSpeedCAN.dbc.";
BA_ "Bus" BO_ 1363 "HS-CAN";
CM_ BO_ 1365 "Bus: MS-CAN. Source: DbcDatabaseFile row 80.";
BA_ "Bus" BO_ 1365 "MS-CAN";
CM_ BO_ 1372 "Bus: MS-CAN. Source: DbcDatabaseFile row 378.";
BA_ "Bus" BO_ 1372 "MS-CAN";
CM_ BO_ 1571 "Bus: HS-CAN. Source: uploaded highSpeedCAN.dbc.";
BA_ "Bus" BO_ 1571 "HS-CAN";
CM_ BO_ 1600 "Bus: HS-CAN. Source: overview byte map, uploaded highSpeedCAN.dbc. Alternative message name from source: MSCAN_TransConfig_MS | Also present on MSCAN in source data.";
BA_ "Bus" BO_ 1600 "HS-CAN";
CM_ SG_ 1600 ManualTransFlag_B0 "Overview byte 0: ManualTransFlag";
CM_ SG_ 1600 RawByte1_B1 "Overview byte 1: RawByte1";
CM_ SG_ 1600 RawByte2_B2 "Overview byte 2: RawByte2";
CM_ SG_ 1600 RawByte3_B3 "Overview byte 3: RawByte3";
CM_ SG_ 1600 RawByte4_B4 "Overview byte 4: RawByte4";
CM_ SG_ 1600 RawByte5_B5 "Overview byte 5: RawByte5";
CM_ SG_ 1600 RawByte6_B6 "Overview byte 6: RawByte6";
CM_ SG_ 1600 RawByte7_B7 "Overview byte 7: RawByte7";
CM_ BO_ 1616 "Bus: HS-CAN. Source: uploaded highSpeedCAN.dbc.";
BA_ "Bus" BO_ 1616 "HS-CAN";
CM_ BO_ 1664 "Bus: HS-CAN. Source: overview byte map. Overview names: RCM_Rapid_Data_Response_1 | Overview ECUs/modules: Restraints Control Module | Alternative message name from source: MSCAN_PAM_CCP_DTO | Also present on MSCAN in source data.";
BA_ "Bus" BO_ 1664 "HS-CAN";
CM_ SG_ 1664 RawByte0_B0 "Overview byte 0: RawByte0";
CM_ SG_ 1664 RawByte1_B1 "Overview byte 1: RawByte1";
CM_ SG_ 1664 RawByte2_B2 "Overview byte 2: RawByte2";
CM_ SG_ 1664 RawByte3_B3 "Overview byte 3: RawByte3";
CM_ SG_ 1664 RawByte4_B4 "Overview byte 4: RawByte4";
CM_ SG_ 1664 RawByte5_B5 "Overview byte 5: RawByte5";
CM_ SG_ 1664 RawByte6_B6 "Overview byte 6: RawByte6";
CM_ SG_ 1664 RawByte7_B7 "Overview byte 7: RawByte7";
CM_ BO_ 1665 "Bus: HS-CAN. Source: overview byte map. Overview names: RCM_Rapid_Data_Response_2 | Overview ECUs/modules: Restraints Control Module | Alternative message name from source: MSCAN_PAM_CCP_CRO | Also present on MSCAN in source data.";
BA_ "Bus" BO_ 1665 "HS-CAN";
CM_ SG_ 1665 RawByte0_B0 "Overview byte 0: RawByte0";
CM_ SG_ 1665 RawByte1_B1 "Overview byte 1: RawByte1";
CM_ SG_ 1665 RawByte2_B2 "Overview byte 2: RawByte2";
CM_ SG_ 1665 RawByte3_B3 "Overview byte 3: RawByte3";
CM_ SG_ 1665 RawByte4_B4 "Overview byte 4: RawByte4";
CM_ SG_ 1665 RawByte5_B5 "Overview byte 5: RawByte5";
CM_ SG_ 1665 RawByte6_B6 "Overview byte 6: RawByte6";
CM_ SG_ 1665 RawByte7_B7 "Overview byte 7: RawByte7";
CM_ BO_ 1696 "Bus: HS-CAN. Source: overview byte map. Overview names: PCM_Rapid_Data_Response_1 | Overview ECUs/modules: Powertrain Control Module";
BA_ "Bus" BO_ 1696 "HS-CAN";
CM_ SG_ 1696 PCM_Live_Data_Stream_B0 "Overview byte 0: PCM Live Data Stream";
CM_ SG_ 1696 PCM_Live_Data_Stream_B1 "Overview byte 1: PCM Live Data Stream";
CM_ SG_ 1696 PCM_Live_Data_Stream_B2 "Overview byte 2: PCM Live Data Stream";
CM_ SG_ 1696 PCM_Live_Data_Stream_B3 "Overview byte 3: PCM Live Data Stream";
CM_ SG_ 1696 PCM_Live_Data_Stream_B4 "Overview byte 4: PCM Live Data Stream";
CM_ SG_ 1696 PCM_Live_Data_Stream_B5 "Overview byte 5: PCM Live Data Stream";
CM_ SG_ 1696 PCM_Live_Data_Stream_B6 "Overview byte 6: PCM Live Data Stream";
CM_ SG_ 1696 PCM_Live_Data_Stream_B7 "Overview byte 7: PCM Live Data Stream";
CM_ BO_ 1697 "Bus: HS-CAN. Source: overview byte map. Overview names: PCM_Rapid_Data_Response_2 | Overview ECUs/modules: Powertrain Control Module";
BA_ "Bus" BO_ 1697 "HS-CAN";
CM_ SG_ 1697 PCM_Live_Data_Stream_B0 "Overview byte 0: PCM Live Data Stream";
CM_ SG_ 1697 PCM_Live_Data_Stream_B1 "Overview byte 1: PCM Live Data Stream";
CM_ SG_ 1697 PCM_Live_Data_Stream_B2 "Overview byte 2: PCM Live Data Stream";
CM_ SG_ 1697 PCM_Live_Data_Stream_B3 "Overview byte 3: PCM Live Data Stream";
CM_ SG_ 1697 PCM_Live_Data_Stream_B4 "Overview byte 4: PCM Live Data Stream";
CM_ SG_ 1697 PCM_Live_Data_Stream_B5 "Overview byte 5: PCM Live Data Stream";
CM_ SG_ 1697 PCM_Live_Data_Stream_B6 "Overview byte 6: PCM Live Data Stream";
CM_ SG_ 1697 PCM_Live_Data_Stream_B7 "Overview byte 7: PCM Live Data Stream";
CM_ BO_ 1698 "Bus: HS-CAN. Source: overview byte map. Overview names: PCM_Rapid_Data_Response_3 | Overview ECUs/modules: Powertrain Control Module";
BA_ "Bus" BO_ 1698 "HS-CAN";
CM_ SG_ 1698 PCM_Live_Data_Stream_B0 "Overview byte 0: PCM Live Data Stream";
CM_ SG_ 1698 PCM_Live_Data_Stream_B1 "Overview byte 1: PCM Live Data Stream";
CM_ SG_ 1698 PCM_Live_Data_Stream_B2 "Overview byte 2: PCM Live Data Stream";
CM_ SG_ 1698 PCM_Live_Data_Stream_B3 "Overview byte 3: PCM Live Data Stream";
CM_ SG_ 1698 PCM_Live_Data_Stream_B4 "Overview byte 4: PCM Live Data Stream";
CM_ SG_ 1698 PCM_Live_Data_Stream_B5 "Overview byte 5: PCM Live Data Stream";
CM_ SG_ 1698 PCM_Live_Data_Stream_B6 "Overview byte 6: PCM Live Data Stream";
CM_ SG_ 1698 PCM_Live_Data_Stream_B7 "Overview byte 7: PCM Live Data Stream";
CM_ BO_ 1699 "Bus: HS-CAN. Source: overview byte map. Overview names: PCM_Rapid_Data_Response_4 | Overview ECUs/modules: Powertrain Control Module";
BA_ "Bus" BO_ 1699 "HS-CAN";
CM_ SG_ 1699 PCM_Live_Data_Stream_B0 "Overview byte 0: PCM Live Data Stream";
CM_ SG_ 1699 PCM_Live_Data_Stream_B1 "Overview byte 1: PCM Live Data Stream";
CM_ SG_ 1699 PCM_Live_Data_Stream_B2 "Overview byte 2: PCM Live Data Stream";
CM_ SG_ 1699 PCM_Live_Data_Stream_B3 "Overview byte 3: PCM Live Data Stream";
CM_ SG_ 1699 PCM_Live_Data_Stream_B4 "Overview byte 4: PCM Live Data Stream";
CM_ SG_ 1699 PCM_Live_Data_Stream_B5 "Overview byte 5: PCM Live Data Stream";
CM_ SG_ 1699 PCM_Live_Data_Stream_B6 "Overview byte 6: PCM Live Data Stream";
CM_ SG_ 1699 PCM_Live_Data_Stream_B7 "Overview byte 7: PCM Live Data Stream";
CM_ BO_ 1700 "Bus: HS-CAN. Source: overview byte map. Overview names: TCM_Rapid_Data_Response_1 | Overview ECUs/modules: Powertrain Control Module";
BA_ "Bus" BO_ 1700 "HS-CAN";
CM_ SG_ 1700 TCM_Live_Data_Steam_B0 "Overview byte 0: TCM Live Data Steam";
CM_ SG_ 1700 TCM_Live_Data_Steam_B1 "Overview byte 1: TCM Live Data Steam";
CM_ SG_ 1700 TCM_Live_Data_Steam_B2 "Overview byte 2: TCM Live Data Steam";
CM_ SG_ 1700 TCM_Live_Data_Steam_B3 "Overview byte 3: TCM Live Data Steam";
CM_ SG_ 1700 TCM_Live_Data_Steam_B4 "Overview byte 4: TCM Live Data Steam";
CM_ SG_ 1700 TCM_Live_Data_Steam_B5 "Overview byte 5: TCM Live Data Steam";
CM_ SG_ 1700 TCM_Live_Data_Steam_B6 "Overview byte 6: TCM Live Data Steam";
CM_ SG_ 1700 TCM_Live_Data_Steam_B7 "Overview byte 7: TCM Live Data Steam";
CM_ BO_ 1701 "Bus: HS-CAN. Source: overview byte map. Overview names: TCM_Rapid_Data_Response_2 | Overview ECUs/modules: Powertrain Control Module";
BA_ "Bus" BO_ 1701 "HS-CAN";
CM_ SG_ 1701 TCM_Live_Data_Stream_B0 "Overview byte 0: TCM Live Data Stream";
CM_ SG_ 1701 TCM_Live_Data_Stream_B1 "Overview byte 1: TCM Live Data Stream";
CM_ SG_ 1701 TCM_Live_Data_Stream_B2 "Overview byte 2: TCM Live Data Stream";
CM_ SG_ 1701 TCM_Live_Data_Stream_B3 "Overview byte 3: TCM Live Data Stream";
CM_ SG_ 1701 TCM_Live_Data_Stream_B4 "Overview byte 4: TCM Live Data Stream";
CM_ SG_ 1701 TCM_Live_Data_Stream_B5 "Overview byte 5: TCM Live Data Stream";
CM_ SG_ 1701 TCM_Live_Data_Stream_B6 "Overview byte 6: TCM Live Data Stream";
CM_ SG_ 1701 TCM_Live_Data_Stream_B7 "Overview byte 7: TCM Live Data Stream";
CM_ BO_ 1712 "Bus: HS-CAN. Source: overview byte map. Overview names: ABS_Rapid_Data_Response_1 | Overview ECUs/modules: Antilock Brake Module";
BA_ "Bus" BO_ 1712 "HS-CAN";
CM_ SG_ 1712 ABS_Live_Data_Stream_B0 "Overview byte 0: ABS Live Data Stream";
CM_ SG_ 1712 ABS_Live_Data_Stream_B1 "Overview byte 1: ABS Live Data Stream";
CM_ SG_ 1712 ABS_Live_Data_Stream_B2 "Overview byte 2: ABS Live Data Stream";
CM_ SG_ 1712 ABS_Live_Data_Stream_B3 "Overview byte 3: ABS Live Data Stream";
CM_ SG_ 1712 ABS_Live_Data_Stream_B4 "Overview byte 4: ABS Live Data Stream";
CM_ SG_ 1712 ABS_Live_Data_Stream_B5 "Overview byte 5: ABS Live Data Stream";
CM_ SG_ 1712 ABS_Live_Data_Stream_B6 "Overview byte 6: ABS Live Data Stream";
CM_ SG_ 1712 ABS_Live_Data_Stream_B7 "Overview byte 7: ABS Live Data Stream";
CM_ BO_ 1713 "Bus: HS-CAN. Source: overview byte map. Overview names: ABS_Rapid_Data_Response_2 | Overview ECUs/modules: Antilock Brake Module";
BA_ "Bus" BO_ 1713 "HS-CAN";
CM_ SG_ 1713 ABS_Live_Data_Stream_B0 "Overview byte 0: ABS Live Data Stream";
CM_ SG_ 1713 ABS_Live_Data_Stream_B1 "Overview byte 1: ABS Live Data Stream";
CM_ SG_ 1713 ABS_Live_Data_Stream_B2 "Overview byte 2: ABS Live Data Stream";
CM_ SG_ 1713 ABS_Live_Data_Stream_B3 "Overview byte 3: ABS Live Data Stream";
CM_ SG_ 1713 ABS_Live_Data_Stream_B4 "Overview byte 4: ABS Live Data Stream";
CM_ SG_ 1713 ABS_Live_Data_Stream_B5 "Overview byte 5: ABS Live Data Stream";
CM_ SG_ 1713 ABS_Live_Data_Stream_B6 "Overview byte 6: ABS Live Data Stream";
CM_ SG_ 1713 ABS_Live_Data_Stream_B7 "Overview byte 7: ABS Live Data Stream";
CM_ BO_ 1782 "Bus: HS-CAN. Source: overview byte map, uploaded highSpeedCAN.dbc. Alternative message name from source: MSCAN_ImmobTransfer_PCM_1_to_8_PATS | Also present on MSCAN in source data.";
BA_ "Bus" BO_ 1782 "HS-CAN";
CM_ SG_ 1782 ImmobTransfer_PCM_1_to_8_PATS_B0 "Overview byte 0: ImmobTransfer_PCM_1 to 8   PATS";
CM_ SG_ 1782 ImmobTransfer_PCM_1_to_8_PATS_B1 "Overview byte 1: ImmobTransfer_PCM_1 to 8   PATS";
CM_ SG_ 1782 ImmobTransfer_PCM_1_to_8_PATS_B2 "Overview byte 2: ImmobTransfer_PCM_1 to 8   PATS";
CM_ SG_ 1782 ImmobTransfer_PCM_1_to_8_PATS_B3 "Overview byte 3: ImmobTransfer_PCM_1 to 8   PATS";
CM_ SG_ 1782 ImmobTransfer_PCM_1_to_8_PATS_B4 "Overview byte 4: ImmobTransfer_PCM_1 to 8   PATS";
CM_ SG_ 1782 ImmobTransfer_PCM_1_to_8_PATS_B5 "Overview byte 5: ImmobTransfer_PCM_1 to 8   PATS";
CM_ SG_ 1782 ImmobTransfer_PCM_1_to_8_PATS_B6 "Overview byte 6: ImmobTransfer_PCM_1 to 8   PATS";
CM_ SG_ 1782 ImmobTransfer_PCM_1_to_8_PATS_B7 "Overview byte 7: ImmobTransfer_PCM_1 to 8   PATS";
CM_ BO_ 1784 "Bus: HS-CAN. Source: overview byte map, uploaded highSpeedCAN.dbc. Alternative message name from source: MSCAN_ImmobTransfer_BEM_1_to_8_PATS | Also present on MSCAN in source data.";
BA_ "Bus" BO_ 1784 "HS-CAN";
CM_ SG_ 1784 ImmobTransfer_BEM_1_to_8_PATS_B0 "Overview byte 0: ImmobTransfer_BEM_1 to 8   PATS";
CM_ SG_ 1784 ImmobTransfer_BEM_1_to_8_PATS_B1 "Overview byte 1: ImmobTransfer_BEM_1 to 8   PATS";
CM_ SG_ 1784 ImmobTransfer_BEM_1_to_8_PATS_B2 "Overview byte 2: ImmobTransfer_BEM_1 to 8   PATS";
CM_ SG_ 1784 ImmobTransfer_BEM_1_to_8_PATS_B3 "Overview byte 3: ImmobTransfer_BEM_1 to 8   PATS";
CM_ SG_ 1784 ImmobTransfer_BEM_1_to_8_PATS_B4 "Overview byte 4: ImmobTransfer_BEM_1 to 8   PATS";
CM_ SG_ 1784 ImmobTransfer_BEM_1_to_8_PATS_B5 "Overview byte 5: ImmobTransfer_BEM_1 to 8   PATS";
CM_ SG_ 1784 ImmobTransfer_BEM_1_to_8_PATS_B6 "Overview byte 6: ImmobTransfer_BEM_1 to 8   PATS";
CM_ SG_ 1784 ImmobTransfer_BEM_1_to_8_PATS_B7 "Overview byte 7: ImmobTransfer_BEM_1 to 8   PATS";
CM_ BO_ 1786 "Bus: HS-CAN. Source: overview byte map. Overview names: IpcImmob_0x720 | Overview ECUs/modules: Instrument Cluster | Alternative message name from source: MSCAN_ImmobTransfer_IPC_1_to_8_PATS | Also present on MSCAN in source data.";
BA_ "Bus" BO_ 1786 "HS-CAN";
CM_ SG_ 1786 Immobilizer_B0 "Overview byte 0: Immobilizer";
CM_ SG_ 1786 Immobilizer_B1 "Overview byte 1: Immobilizer";
CM_ SG_ 1786 Immobilizer_B2 "Overview byte 2: Immobilizer";
CM_ SG_ 1786 Immobilizer_B3 "Overview byte 3: Immobilizer";
CM_ SG_ 1786 Immobilizer_B4 "Overview byte 4: Immobilizer";
CM_ SG_ 1786 Immobilizer_B5 "Overview byte 5: Immobilizer";
CM_ SG_ 1786 Immobilizer_B6 "Overview byte 6: Immobilizer";
CM_ SG_ 1786 Immobilizer_B7 "Overview byte 7: Immobilizer";
CM_ SG_ 1786 ImmobTransfer_IPC_1_to_8_PATS_B0 "Overview byte 0: ImmobTransfer_IPC_1 to 8   PATS";
CM_ SG_ 1786 ImmobTransfer_IPC_1_to_8_PATS_B1 "Overview byte 1: ImmobTransfer_IPC_1 to 8   PATS";
CM_ SG_ 1786 ImmobTransfer_IPC_1_to_8_PATS_B2 "Overview byte 2: ImmobTransfer_IPC_1 to 8   PATS";
CM_ SG_ 1786 ImmobTransfer_IPC_1_to_8_PATS_B3 "Overview byte 3: ImmobTransfer_IPC_1 to 8   PATS";
CM_ SG_ 1786 ImmobTransfer_IPC_1_to_8_PATS_B4 "Overview byte 4: ImmobTransfer_IPC_1 to 8   PATS";
CM_ SG_ 1786 ImmobTransfer_IPC_1_to_8_PATS_B5 "Overview byte 5: ImmobTransfer_IPC_1 to 8   PATS";
CM_ SG_ 1786 ImmobTransfer_IPC_1_to_8_PATS_B6 "Overview byte 6: ImmobTransfer_IPC_1 to 8   PATS";
CM_ SG_ 1786 ImmobTransfer_IPC_1_to_8_PATS_B7 "Overview byte 7: ImmobTransfer_IPC_1 to 8   PATS";
CM_ BO_ 1788 "Bus: MS-CAN. Source: DbcDatabaseFile row 820.";
BA_ "Bus" BO_ 1788 "MS-CAN";
CM_ BO_ 1797 "Bus: MS-CAN. Source: overview byte map. Overview names: IPC CCP?, Unkown | Overview ECUs/modules: ?, Unkown";
BA_ "Bus" BO_ 1797 "MS-CAN";
CM_ SG_ 1797 CCP__B0 "Overview byte 0: CCP?";
CM_ SG_ 1797 RawByte1_B1 "Overview byte 1: RawByte1";
CM_ SG_ 1797 RawByte2_B2 "Overview byte 2: RawByte2";
CM_ SG_ 1797 RawByte3_B3 "Overview byte 3: RawByte3";
CM_ SG_ 1797 RawByte4_B4 "Overview byte 4: RawByte4";
CM_ SG_ 1797 RawByte5_B5 "Overview byte 5: RawByte5";
CM_ SG_ 1797 RawByte6_B6 "Overview byte 6: RawByte6";
CM_ SG_ 1797 RawByte7_B7 "Overview byte 7: RawByte7";
CM_ BO_ 1798 "Bus: MS-CAN. Source: overview byte map. Overview names: BEM CAN CALIBRATION PROTOCOL, Unkown | Overview ECUs/modules: Diagnostic Tester, Unkown";
BA_ "Bus" BO_ 1798 "MS-CAN";
CM_ SG_ 1798 CCP__B0 "Overview byte 0: CCP?";
CM_ SG_ 1798 RawByte1_B1 "Overview byte 1: RawByte1";
CM_ SG_ 1798 RawByte2_B2 "Overview byte 2: RawByte2";
CM_ SG_ 1798 RawByte3_B3 "Overview byte 3: RawByte3";
CM_ SG_ 1798 RawByte4_B4 "Overview byte 4: RawByte4";
CM_ SG_ 1798 RawByte5_B5 "Overview byte 5: RawByte5";
CM_ SG_ 1798 RawByte6_B6 "Overview byte 6: RawByte6";
CM_ SG_ 1798 RawByte7_B7 "Overview byte 7: RawByte7";
CM_ BO_ 1809 "Bus: MS-CAN. Source: overview byte map.";
BA_ "Bus" BO_ 1809 "MS-CAN";
CM_ SG_ 1809 RawByte0_B0 "Overview byte 0: RawByte0";
CM_ SG_ 1809 RawByte1_B1 "Overview byte 1: RawByte1";
CM_ SG_ 1809 RawByte2_B2 "Overview byte 2: RawByte2";
CM_ SG_ 1809 RawByte3_B3 "Overview byte 3: RawByte3";
CM_ SG_ 1809 RawByte4_B4 "Overview byte 4: RawByte4";
CM_ SG_ 1809 RawByte5_B5 "Overview byte 5: RawByte5";
CM_ SG_ 1809 RawByte6_B6 "Overview byte 6: RawByte6";
CM_ SG_ 1809 RawByte7_B7 "Overview byte 7: RawByte7";
CM_ BO_ 1810 "Bus: MS-CAN. Source: overview byte map. Overview names: BEM CAN CALIBRATION PROTOCOL | Overview ECUs/modules: Body Electronic Module";
BA_ "Bus" BO_ 1810 "MS-CAN";
CM_ SG_ 1810 RawByte0_B0 "Overview byte 0: RawByte0";
CM_ SG_ 1810 RawByte1_B1 "Overview byte 1: RawByte1";
CM_ SG_ 1810 RawByte2_B2 "Overview byte 2: RawByte2";
CM_ SG_ 1810 RawByte3_B3 "Overview byte 3: RawByte3";
CM_ SG_ 1810 RawByte4_B4 "Overview byte 4: RawByte4";
CM_ SG_ 1810 RawByte5_B5 "Overview byte 5: RawByte5";
CM_ SG_ 1810 RawByte6_B6 "Overview byte 6: RawByte6";
CM_ SG_ 1810 RawByte7_B7 "Overview byte 7: RawByte7";
CM_ BO_ 1812 "Bus: MS-CAN. Source: overview byte map. Overview names: Where did this data come from!";
BA_ "Bus" BO_ 1812 "MS-CAN";
CM_ SG_ 1812 RawByte0_B0 "Overview byte 0: RawByte0";
CM_ SG_ 1812 RawByte1_B1 "Overview byte 1: RawByte1";
CM_ SG_ 1812 RawByte2_B2 "Overview byte 2: RawByte2";
CM_ SG_ 1812 RawByte3_B3 "Overview byte 3: RawByte3";
CM_ SG_ 1812 RawByte4_B4 "Overview byte 4: RawByte4";
CM_ SG_ 1812 RawByte5_B5 "Overview byte 5: RawByte5";
CM_ SG_ 1812 RawByte6_B6 "Overview byte 6: RawByte6";
CM_ SG_ 1812 RawByte7_B7 "Overview byte 7: RawByte7";
CM_ BO_ 1824 "Bus: MS-CAN. Source: DbcDatabaseFile row 822.";
BA_ "Bus" BO_ 1824 "MS-CAN";
CM_ BO_ 1830 "Bus: MS-CAN. Source: overview byte map. Overview names: BEM_DiagSig_Rx, Clear DTC’s, Read DTC’s, BEM On Demand Self-Test, EcuReset, A/C Sunload Sensor Status, Anti-Scan Function, Auto Lamp Output Status, Heated Backlight Switch, Battery Saver Relay Status. | Overview ECUs/modules: Data Request, Body Electronic Module, Body Electric Module";
BA_ "Bus" BO_ 1830 "MS-CAN";
CM_ SG_ 1830 Data_Length_Packet_B0 "Overview byte 0: Data Length Packet";
CM_ SG_ 1830 Service_Request_B1 "Overview byte 1: Service Request";
CM_ SG_ 1830 Parameters_B2 "Overview byte 2: Parameters";
CM_ SG_ 1830 _0XFF_B3 "Overview byte 3: 0XFF";
CM_ SG_ 1830 Parameters_B4 "Overview byte 4: Parameters";
CM_ SG_ 1830 Parameters_B5 "Overview byte 5: Parameters";
CM_ SG_ 1830 Parameters_B6 "Overview byte 6: Parameters";
CM_ SG_ 1830 Parameters_B7 "Overview byte 7: Parameters";
CM_ BO_ 1831 "Bus: MS-CAN. Source: overview byte map. Overview names: ACM_DiagSig_Rx, Clear DTC’s, Read DTC’s, ACM On Demand Self-Test, EcuReset | Overview ECUs/modules: Audio Control Module";
BA_ "Bus" BO_ 1831 "MS-CAN";
CM_ SG_ 1831 Data_Length_Packet_B0 "Overview byte 0: Data Length Packet";
CM_ SG_ 1831 Service_Request_B1 "Overview byte 1: Service Request";
CM_ SG_ 1831 Parameters_B2 "Overview byte 2: Parameters";
CM_ SG_ 1831 _0XFF_B3 "Overview byte 3: 0XFF";
CM_ SG_ 1831 Parameters_B4 "Overview byte 4: Parameters";
CM_ SG_ 1831 Parameters_B5 "Overview byte 5: Parameters";
CM_ SG_ 1831 Parameters_B6 "Overview byte 6: Parameters";
CM_ SG_ 1831 Parameters_B7 "Overview byte 7: Parameters";
CM_ BO_ 1832 "Bus: MS-CAN. Source: overview byte map. Overview names: IC_DiagSig_Tx, 06 62 E2 00 17 0B 6C > Data is 170B6C - might be checking model?, 7F its a trick, FA 11 88 57 > 3 byte challenge key appears out of nowhere, 02 50 FA > Success!, FA 01 02 15 A1 > !!! 0xA1 is byte 0, 0x15 is byte 1 in the EEPROM., FA 02 02 > Happy days, back a 4 byte short packet: 05 50 00 00, Positive Response | Overview ECUs/modules: Instrument Cluster, READ DATA BY ID, NEGATIVE RESPONSE CODE, MANUFACTURER SEED KEY, ENTER MANUFACTURER STATE, EEPROM READ, EEPROM WRITE, ENTER PROGRAMMING MODE";
BA_ "Bus" BO_ 1832 "MS-CAN";
CM_ SG_ 1832 Data_Length_Packet_B0 "Overview byte 0: Data Length Packet";
CM_ SG_ 1832 Response_B1 "Overview byte 1: Response";
CM_ SG_ 1832 Request_Echo_B2 "Overview byte 2: Request Echo";
CM_ SG_ 1832 Error_Code_ID_B3 "Overview byte 3: Error Code ID";
CM_ SG_ 1832 Parameters_B4 "Overview byte 4: Parameters";
CM_ SG_ 1832 Parameters_B5 "Overview byte 5: Parameters";
CM_ SG_ 1832 Parameters_B6 "Overview byte 6: Parameters";
CM_ SG_ 1832 Parameters_B7 "Overview byte 7: Parameters";
CM_ BO_ 1838 "Bus: MS-CAN. Source: overview byte map. Overview names: BEM_DiagSig_Tx | Overview ECUs/modules: Body Electronic Module";
BA_ "Bus" BO_ 1838 "MS-CAN";
CM_ SG_ 1838 Data_Length_Packet_B0 "Overview byte 0: Data Length Packet";
CM_ SG_ 1838 Response_B1 "Overview byte 1: Response";
CM_ SG_ 1838 Request_Echo_B2 "Overview byte 2: Request Echo";
CM_ SG_ 1838 Error_Code_ID_B3 "Overview byte 3: Error Code ID";
CM_ SG_ 1838 Parameters_B4 "Overview byte 4: Parameters";
CM_ SG_ 1838 Parameters_B5 "Overview byte 5: Parameters";
CM_ SG_ 1838 Parameters_B6 "Overview byte 6: Parameters";
CM_ SG_ 1838 Parameters_B7 "Overview byte 7: Parameters";
CM_ BO_ 1839 "Bus: MS-CAN. Source: overview byte map. Overview names: ACM_DiagSig_Tx | Overview ECUs/modules: Audio Control Module";
BA_ "Bus" BO_ 1839 "MS-CAN";
CM_ SG_ 1839 Data_Length_Packet_B0 "Overview byte 0: Data Length Packet";
CM_ SG_ 1839 Response_B1 "Overview byte 1: Response";
CM_ SG_ 1839 Request_Echo_B2 "Overview byte 2: Request Echo";
CM_ SG_ 1839 Error_Code_ID_B3 "Overview byte 3: Error Code ID";
CM_ SG_ 1839 Parameters_B4 "Overview byte 4: Parameters";
CM_ SG_ 1839 Parameters_B5 "Overview byte 5: Parameters";
CM_ SG_ 1839 Parameters_B6 "Overview byte 6: Parameters";
CM_ SG_ 1839 Parameters_B7 "Overview byte 7: Parameters";
CM_ BO_ 1843 "Bus: HS-CAN. Source: overview byte map. Overview names: HIM_DiagSig_Rx, evaporator temperature, Air conditioning compressor cycling switch, Missing the CAN message from BEM, Blend Door Position, Blend Door Target Position, Blower Motor Speed - Actual Position, Blower Motor Speed - Target Position, Blower/Fan Sense Voltage, Climate Control Actuator Modes | Overview ECUs/modules: Data Request, HVAC Integrated Module | Alternative message name from source: MSCAN_Clear_DTC_s | Also present on MSCAN in source data.";
BA_ "Bus" BO_ 1843 "HS-CAN";
CM_ SG_ 1843 Data_Length_Packet_B0 "Overview byte 0: Data Length Packet";
CM_ SG_ 1843 Service_Request_B1 "Overview byte 1: Service Request";
CM_ SG_ 1843 Parameters_B2 "Overview byte 2: Parameters";
CM_ SG_ 1843 Parameters_B3 "Overview byte 3: Parameters";
CM_ SG_ 1843 Parameters_B4 "Overview byte 4: Parameters";
CM_ SG_ 1843 Parameters_B5 "Overview byte 5: Parameters";
CM_ SG_ 1843 Parameters_B6 "Overview byte 6: Parameters";
CM_ SG_ 1843 Parameters_B7 "Overview byte 7: Parameters";
CM_ SG_ 1843 LEN_B0 "Overview byte 0: LEN";
CM_ SG_ 1843 RawByte1_B1 "Overview byte 1: RawByte1";
CM_ SG_ 1843 RawByte2_B2 "Overview byte 2: RawByte2";
CM_ SG_ 1843 _0XFF_B3 "Overview byte 3: 0XFF";
CM_ SG_ 1843 RawByte4_B4 "Overview byte 4: RawByte4";
CM_ SG_ 1843 RawByte5_B5 "Overview byte 5: RawByte5";
CM_ SG_ 1843 RawByte6_B6 "Overview byte 6: RawByte6";
CM_ SG_ 1843 RawByte7_B7 "Overview byte 7: RawByte7";
CM_ BO_ 1846 "Bus: MS-CAN. Source: overview byte map. Overview names: PAM_DiagSig_Rx, Clear DTC’s, Read DTC’s, Supplier Diagnostic Session 0x10FA, RCM_DiagSig_Rx, PAM On Demand Self-Test, EcuReset, Parking aid system status, Echo Value for Right Corner Sensor, Parking aid rear sensor status | Overview ECUs/modules: Restraints Control Module, Parking Aid Module, Data Request, MANUFACTURER STATE, Parking aid system status, Echo Value for Right Corner Sensor, Parking aid rear sensor status, Parking Aid Sounder";
BA_ "Bus" BO_ 1846 "MS-CAN";
CM_ SG_ 1846 Data_Length_Packet_B0 "Overview byte 0: Data Length Packet";
CM_ SG_ 1846 Service_Request_B1 "Overview byte 1: Service Request";
CM_ SG_ 1846 Parameters_B2 "Overview byte 2: Parameters";
CM_ SG_ 1846 _0XFF_B3 "Overview byte 3: 0XFF";
CM_ SG_ 1846 Parameters_B4 "Overview byte 4: Parameters";
CM_ SG_ 1846 Parameters_B5 "Overview byte 5: Parameters";
CM_ SG_ 1846 Parameters_B6 "Overview byte 6: Parameters";
CM_ SG_ 1846 Parameters_B7 "Overview byte 7: Parameters";
CM_ BO_ 1847 "Bus: MS-CAN. Source: overview byte map. Overview names: RCM_DiagSig_Rx, Clear DTC’s, Read DTC’s, PAM_DiagSig_Rx, RCM_ On Demand Self-Test, EcuReset, PAM On Demand Self-Test | Overview ECUs/modules: Parking Aid Module, Restraints Control Module";
BA_ "Bus" BO_ 1847 "MS-CAN";
CM_ SG_ 1847 Data_Length_Packet_B0 "Overview byte 0: Data Length Packet";
CM_ SG_ 1847 Service_Request_B1 "Overview byte 1: Service Request";
CM_ SG_ 1847 Parameters_B2 "Overview byte 2: Parameters";
CM_ SG_ 1847 _0XFF_B3 "Overview byte 3: 0XFF";
CM_ SG_ 1847 Parameters_B4 "Overview byte 4: Parameters";
CM_ SG_ 1847 Parameters_B5 "Overview byte 5: Parameters";
CM_ SG_ 1847 Parameters_B6 "Overview byte 6: Parameters";
CM_ SG_ 1847 Parameters_B7 "Overview byte 7: Parameters";
CM_ BO_ 1850 "Bus: HS-CAN. Source: overview byte map. Overview names: HIM_DiagSig_Tx | Overview ECUs/modules: HVAC Integrated Module";
BA_ "Bus" BO_ 1850 "HS-CAN";
CM_ SG_ 1850 Data_Length_Packet_B0 "Overview byte 0: Data Length Packet";
CM_ SG_ 1850 Response_B1 "Overview byte 1: Response";
CM_ SG_ 1850 Echo_Request_B2 "Overview byte 2: Echo Request";
CM_ SG_ 1850 Error_Code_ID_B3 "Overview byte 3: Error Code ID";
CM_ SG_ 1850 Parameters_B4 "Overview byte 4: Parameters";
CM_ SG_ 1850 Parameters_B5 "Overview byte 5: Parameters";
CM_ SG_ 1850 Parameters_B6 "Overview byte 6: Parameters";
CM_ SG_ 1850 Parameters_B7 "Overview byte 7: Parameters";
CM_ BO_ 1854 "Bus: MS-CAN. Source: overview byte map. Overview names: PAM_DiagSig_Tx, Positive Response Supplier Diagnostic, RCM_DiagSig_Rx | Overview ECUs/modules: Data Response, Parking Aid Module, MANUFACTURER STATE, Restraints Control Module";
BA_ "Bus" BO_ 1854 "MS-CAN";
CM_ SG_ 1854 Data_Length_Packet_B0 "Overview byte 0: Data Length Packet";
CM_ SG_ 1854 Response_B1 "Overview byte 1: Response";
CM_ SG_ 1854 Echo_Request_B2 "Overview byte 2: Echo Request";
CM_ SG_ 1854 Error_Code_ID_B3 "Overview byte 3: Error Code ID";
CM_ SG_ 1854 Parameters_B4 "Overview byte 4: Parameters";
CM_ SG_ 1854 Parameters_B5 "Overview byte 5: Parameters";
CM_ SG_ 1854 Parameters_B6 "Overview byte 6: Parameters";
CM_ SG_ 1854 Parameters_B7 "Overview byte 7: Parameters";
CM_ BO_ 1855 "Bus: MS-CAN. Source: overview byte map. Overview names: PAM_DiagSig_Tx, RCM_DiagSig_Rx | Overview ECUs/modules: Parking Aid Module, Restraints Control Module";
BA_ "Bus" BO_ 1855 "MS-CAN";
CM_ SG_ 1855 Data_Length_Packet_B0 "Overview byte 0: Data Length Packet";
CM_ SG_ 1855 Response_B1 "Overview byte 1: Response";
CM_ SG_ 1855 Request_Echo_B2 "Overview byte 2: Request Echo";
CM_ SG_ 1855 Error_Code_ID_B3 "Overview byte 3: Error Code ID";
CM_ SG_ 1855 Parameters_B4 "Overview byte 4: Parameters";
CM_ SG_ 1855 Parameters_B5 "Overview byte 5: Parameters";
CM_ SG_ 1855 Parameters_B6 "Overview byte 6: Parameters";
CM_ SG_ 1855 Parameters_B7 "Overview byte 7: Parameters";
CM_ BO_ 1888 "Bus: HS-CAN. Source: overview byte map. Overview names: Diagnostic Service Request 0xBF | Overview ECUs/modules: Antilock Brake Module | Alternative message name from source: MSCAN_ABS_DiagSig_Rx | Also present on MSCAN in source data.";
BA_ "Bus" BO_ 1888 "HS-CAN";
CM_ SG_ 1888 B0 "Overview byte 0: ??";
CM_ SG_ 1888 RawByte1_B1 "Overview byte 1: RawByte1";
CM_ SG_ 1888 B2 "Overview byte 2: ??";
CM_ SG_ 1888 B3 "Overview byte 3: ??";
CM_ SG_ 1888 B4 "Overview byte 4: ??";
CM_ SG_ 1888 B5 "Overview byte 5: `??";
CM_ SG_ 1888 B6 "Overview byte 6: ??";
CM_ SG_ 1888 B7 "Overview byte 7: ??";
CM_ SG_ 1888 Data_Length_Packet_B0 "Overview byte 0: Data Length Packet";
CM_ SG_ 1888 Service_Request_B1 "Overview byte 1: Service Request";
CM_ SG_ 1888 Parameters_B2 "Overview byte 2: Parameters";
CM_ SG_ 1888 _0XFF_B3 "Overview byte 3: 0XFF";
CM_ SG_ 1888 Parameters_B4 "Overview byte 4: Parameters";
CM_ SG_ 1888 Parameters_B5 "Overview byte 5: Parameters";
CM_ SG_ 1888 Parameters_B6 "Overview byte 6: Parameters";
CM_ SG_ 1888 Parameters_B7 "Overview byte 7: Parameters";
CM_ BO_ 1895 "Bus: MS-CAN. Source: overview byte map. Overview names: AIM_DiagSig_Rx, Clear DTC’s, Read DTC’s, AIM On Demand Self-Test, EcuReset | Overview ECUs/modules: Audio Interface Module, Data Response";
BA_ "Bus" BO_ 1895 "MS-CAN";
CM_ SG_ 1895 Data_Length_Packet_B0 "Overview byte 0: Data Length Packet";
CM_ SG_ 1895 Service_Request_B1 "Overview byte 1: Service Request";
CM_ SG_ 1895 Parameters_B2 "Overview byte 2: Parameters";
CM_ SG_ 1895 _0XFF_B3 "Overview byte 3: 0XFF";
CM_ SG_ 1895 Parameters_B4 "Overview byte 4: Parameters";
CM_ SG_ 1895 Parameters_B5 "Overview byte 5: Parameters";
CM_ SG_ 1895 Parameters_B6 "Overview byte 6: Parameters";
CM_ SG_ 1895 Parameters_B7 "Overview byte 7: Parameters";
CM_ BO_ 1896 "Bus: MS-CAN. Source: overview byte map. Overview names: ABS_DiagSig_Tx | Overview ECUs/modules: Antilock Brake Module";
BA_ "Bus" BO_ 1896 "MS-CAN";
CM_ SG_ 1896 Data_Length_Packet_B0 "Overview byte 0: Data Length Packet";
CM_ SG_ 1896 Response_B1 "Overview byte 1: Response";
CM_ SG_ 1896 Request_Echo_B2 "Overview byte 2: Request Echo";
CM_ SG_ 1896 Error_Code_ID_B3 "Overview byte 3: Error Code ID";
CM_ SG_ 1896 Parameters_B4 "Overview byte 4: Parameters";
CM_ SG_ 1896 Parameters_B5 "Overview byte 5: Parameters";
CM_ SG_ 1896 Parameters_B6 "Overview byte 6: Parameters";
CM_ SG_ 1896 Parameters_B7 "Overview byte 7: Parameters";
CM_ BO_ 1903 "Bus: MS-CAN. Source: overview byte map. Overview names: AIM_DiagSig_Tx | Overview ECUs/modules: Audio Interface Module";
BA_ "Bus" BO_ 1903 "MS-CAN";
CM_ SG_ 1903 Data_Length_Packet_B0 "Overview byte 0: Data Length Packet";
CM_ SG_ 1903 Response_B1 "Overview byte 1: Response";
CM_ SG_ 1903 Request_Echo_B2 "Overview byte 2: Request Echo";
CM_ SG_ 1903 Error_Code_ID_B3 "Overview byte 3: Error Code ID";
CM_ SG_ 1903 Parameters_B4 "Overview byte 4: Parameters";
CM_ SG_ 1903 Parameters_B5 "Overview byte 5: Parameters";
CM_ SG_ 1903 Parameters_B6 "Overview byte 6: Parameters";
CM_ SG_ 1903 Parameters_B7 "Overview byte 7: Parameters";
CM_ BO_ 1921 "Bus: MS-CAN. Source: overview byte map. Overview names: BPM_DiagSig_Rx, Clear DTC’s, Read DTC’s, BPM On Demand Self-Test, EcuReset, Bluetooth Reception Signal Strength, Security Status, ECU Operating States, Number of continuous trouble codes set, Number of On Demand DTCs | Overview ECUs/modules: Bluetooth Phone Module, Data Request";
BA_ "Bus" BO_ 1921 "MS-CAN";
CM_ SG_ 1921 Data_Length_Packet_B0 "Overview byte 0: Data Length Packet";
CM_ SG_ 1921 Service_Request_B1 "Overview byte 1: Service Request";
CM_ SG_ 1921 Parameters_B2 "Overview byte 2: Parameters";
CM_ SG_ 1921 _0XFF_B3 "Overview byte 3: 0XFF";
CM_ SG_ 1921 Parameters_B4 "Overview byte 4: Parameters";
CM_ SG_ 1921 Parameters_B5 "Overview byte 5: Parameters";
CM_ SG_ 1921 Parameters_B6 "Overview byte 6: Parameters";
CM_ SG_ 1921 Parameters_B7 "Overview byte 7: Parameters";
CM_ BO_ 1929 "Bus: MS-CAN. Source: overview byte map. Overview names: BPM_DiagSig_Tx, Bluetooth Reception Signal Strength, Security Status, ECU Operating States, Number of continuous trouble codes set, Number of On Demand DTCs | Overview ECUs/modules: Data Response, Bluetooth Phone Module";
BA_ "Bus" BO_ 1929 "MS-CAN";
CM_ SG_ 1929 Data_Length_Packet_B0 "Overview byte 0: Data Length Packet";
CM_ SG_ 1929 Response_B1 "Overview byte 1: Response";
CM_ SG_ 1929 Request_Echo_B2 "Overview byte 2: Request Echo";
CM_ SG_ 1929 Error_Code_ID_B3 "Overview byte 3: Error Code ID";
CM_ SG_ 1929 Parameters_B4 "Overview byte 4: Parameters";
CM_ SG_ 1929 Parameters_B5 "Overview byte 5: Parameters";
CM_ SG_ 1929 Parameters_B6 "Overview byte 6: Parameters";
CM_ SG_ 1929 Parameters_B7 "Overview byte 7: Parameters";
CM_ BO_ 1943 "Bus: HS-CAN. Source: overview byte map. Overview names: SAS_DiagSig_Rx | Overview ECUs/modules: Steering Angle Sensor";
BA_ "Bus" BO_ 1943 "HS-CAN";
CM_ SG_ 1943 Data_Length_Packet_B0 "Overview byte 0: Data Length Packet";
CM_ SG_ 1943 Service_Request_B1 "Overview byte 1: Service Request";
CM_ SG_ 1943 Echo_Request_B2 "Overview byte 2: Echo Request";
CM_ SG_ 1943 Error_Code_ID_B3 "Overview byte 3: Error Code ID";
CM_ SG_ 1943 Parameters_B4 "Overview byte 4: Parameters";
CM_ SG_ 1943 Parameters_B5 "Overview byte 5: Parameters";
CM_ SG_ 1943 Parameters_B6 "Overview byte 6: Parameters";
CM_ SG_ 1943 Parameters_B7 "Overview byte 7: Parameters";
CM_ BO_ 1951 "Bus: HS-CAN. Source: overview byte map. Overview names: SAS_DiagSig_Tx | Overview ECUs/modules: Steering Angle Sensor";
BA_ "Bus" BO_ 1951 "HS-CAN";
CM_ SG_ 1951 Data_Length_Packet_B0 "Overview byte 0: Data Length Packet";
CM_ SG_ 1951 Response_B1 "Overview byte 1: Response";
CM_ SG_ 1951 Echo_Request_B2 "Overview byte 2: Echo Request";
CM_ SG_ 1951 Error_Code_ID_B3 "Overview byte 3: Error Code ID";
CM_ SG_ 1951 Parameters_B4 "Overview byte 4: Parameters";
CM_ SG_ 1951 Parameters_B5 "Overview byte 5: Parameters";
CM_ SG_ 1951 Parameters_B6 "Overview byte 6: Parameters";
CM_ SG_ 1951 Parameters_B7 "Overview byte 7: Parameters";
CM_ BO_ 1958 "Bus: MS-CAN. Source: overview byte map. Overview names: FDIM_DiagSig_Rx, Air Conditioning Switch Status, FDIM On Demand Self-Test, EcuReset, Active Video Input, Air distribution status, AMSwitch, Autoset, Back/Home Button Pressed, Continuous Codes | Overview ECUs/modules: Data Request, Front Display Interface Module";
BA_ "Bus" BO_ 1958 "MS-CAN";
CM_ SG_ 1958 Data_Length_Packet_B0 "Overview byte 0: Data Length Packet";
CM_ SG_ 1958 Service_Request_B1 "Overview byte 1: Service Request";
CM_ SG_ 1958 Parameters_B2 "Overview byte 2: Parameters";
CM_ SG_ 1958 Parameters_B3 "Overview byte 3: Parameters";
CM_ SG_ 1958 Parameters_B4 "Overview byte 4: Parameters";
CM_ SG_ 1958 Parameters_B5 "Overview byte 5: Parameters";
CM_ SG_ 1958 Parameters_B6 "Overview byte 6: Parameters";
CM_ SG_ 1958 Parameters_B7 "Overview byte 7: Parameters";
CM_ BO_ 1966 "Bus: MS-CAN. Source: overview byte map. Overview names: FDIM_DiagSig_Tx | Overview ECUs/modules: Front Display Interface Module";
BA_ "Bus" BO_ 1966 "MS-CAN";
CM_ SG_ 1966 Data_Length_Packet_B0 "Overview byte 0: Data Length Packet";
CM_ SG_ 1966 Response_B1 "Overview byte 1: Response";
CM_ SG_ 1966 Request_Echo_B2 "Overview byte 2: Request Echo";
CM_ SG_ 1966 Error_Code_ID_B3 "Overview byte 3: Error Code ID";
CM_ SG_ 1966 Parameters_B4 "Overview byte 4: Parameters";
CM_ SG_ 1966 Parameters_B5 "Overview byte 5: Parameters";
CM_ SG_ 1966 Parameters_B6 "Overview byte 6: Parameters";
CM_ SG_ 1966 Parameters_B7 "Overview byte 7: Parameters";
CM_ BO_ 2015 "Bus: HS-CAN. Source: DbcDatabaseFile row 824.";
BA_ "Bus" BO_ 2015 "HS-CAN";
CM_ BO_ 2016 "Bus: HS-CAN. Source: overview byte map. Overview names: request, response, Manifold absolute pressure sensor, Heated Exhaust Gas Oxygen Sensor (bank 1, Short term fuel trim 1, Heated Exhaust Gas Oxygen Sensor (bank 2, Short term fuel trim 2, PCM_DiagSig_Rx, Time Since Engine Start, Cylinder Head Temperature | Overview ECUs/modules: Powertrain Control Module | Alternative message name from source: MSCAN_Clear_DTC_s | Also present on MSCAN in source data.";
BA_ "Bus" BO_ 2016 "HS-CAN";
CM_ SG_ 2016 Data_Length_Packet_B0 "Overview byte 0: Data Length Packet";
CM_ SG_ 2016 Service_Request_B1 "Overview byte 1: Service Request";
CM_ SG_ 2016 Parameters_B2 "Overview byte 2: Parameters";
CM_ SG_ 2016 Parameters_B3 "Overview byte 3: Parameters";
CM_ SG_ 2016 Parameters_B4 "Overview byte 4: Parameters";
CM_ SG_ 2016 Parameters_B5 "Overview byte 5: Parameters";
CM_ SG_ 2016 Parameters_B6 "Overview byte 6: Parameters";
CM_ SG_ 2016 Parameters_B7 "Overview byte 7: Parameters";
CM_ SG_ 2016 LEN_B0 "Overview byte 0: LEN";
CM_ SG_ 2016 RawByte1_B1 "Overview byte 1: RawByte1";
CM_ SG_ 2016 RawByte2_B2 "Overview byte 2: RawByte2";
CM_ SG_ 2016 _0XFF_B3 "Overview byte 3: 0XFF";
CM_ SG_ 2016 RawByte4_B4 "Overview byte 4: RawByte4";
CM_ SG_ 2016 RawByte5_B5 "Overview byte 5: RawByte5";
CM_ SG_ 2016 RawByte6_B6 "Overview byte 6: RawByte6";
CM_ SG_ 2016 RawByte7_B7 "Overview byte 7: RawByte7";
CM_ BO_ 2017 "Bus: HS-CAN. Source: overview byte map. Overview names: TCM_DiagSig_Rx | Overview ECUs/modules: Transmission Control Module | Alternative message name from source: MSCAN_Clear_DTC_s | Also present on MSCAN in source data.";
BA_ "Bus" BO_ 2017 "HS-CAN";
CM_ SG_ 2017 Data_Length_Packet_B0 "Overview byte 0: Data Length Packet";
CM_ SG_ 2017 Response_B1 "Overview byte 1: Response";
CM_ SG_ 2017 Echo_Request_B2 "Overview byte 2: Echo Request";
CM_ SG_ 2017 Error_Code_ID_B3 "Overview byte 3: Error Code ID";
CM_ SG_ 2017 Parameters_B4 "Overview byte 4: Parameters";
CM_ SG_ 2017 Parameters_B5 "Overview byte 5: Parameters";
CM_ SG_ 2017 Parameters_B6 "Overview byte 6: Parameters";
CM_ SG_ 2017 Parameters_B7 "Overview byte 7: Parameters";
CM_ SG_ 2017 RawByte0_B0 "Overview byte 0: RawByte0";
CM_ SG_ 2017 RawByte1_B1 "Overview byte 1: RawByte1";
CM_ SG_ 2017 RawByte2_B2 "Overview byte 2: RawByte2";
CM_ SG_ 2017 _0XFF_B3 "Overview byte 3: 0XFF";
CM_ SG_ 2017 RawByte4_B4 "Overview byte 4: RawByte4";
CM_ SG_ 2017 RawByte5_B5 "Overview byte 5: RawByte5";
CM_ SG_ 2017 RawByte6_B6 "Overview byte 6: RawByte6";
CM_ SG_ 2017 RawByte7_B7 "Overview byte 7: RawByte7";
CM_ BO_ 2024 "Bus: HS-CAN. Source: DbcDatabaseFile row 826.";
BA_ "Bus" BO_ 2024 "HS-CAN";
CM_ BO_ 2025 "Bus: HS-CAN. Source: overview byte map. Overview names: TCM_DiagSig_Tx | Overview ECUs/modules: Transmission Control Module";
BA_ "Bus" BO_ 2025 "HS-CAN";
CM_ SG_ 2025 Data_Length_Packet_B0 "Overview byte 0: Data Length Packet";
CM_ SG_ 2025 Response_B1 "Overview byte 1: Response";
CM_ SG_ 2025 Echo_Request_B2 "Overview byte 2: Echo Request";
CM_ SG_ 2025 Error_Code_ID_B3 "Overview byte 3: Error Code ID";
CM_ SG_ 2025 Parameters_B4 "Overview byte 4: Parameters";
CM_ SG_ 2025 Parameters_B5 "Overview byte 5: Parameters";
CM_ SG_ 2025 Parameters_B6 "Overview byte 6: Parameters";
CM_ SG_ 2025 Parameters_B7 "Overview byte 7: Parameters";
CM_ BO_ 259282800 "Bus: MS-CAN. Source: overview byte map. Overview names: 6B FB 3E B9 B9 DA DD DE | Overview ECUs/modules: Instrument Cluster";
BA_ "Bus" BO_ 259282800 "MS-CAN";
CM_ SG_ 259282800 RawByte0_B0 "Overview byte 0: RawByte0";
CM_ SG_ 259282800 RawByte1_B1 "Overview byte 1: RawByte1";
CM_ SG_ 259282800 RawByte2_B2 "Overview byte 2: RawByte2";
CM_ SG_ 259282800 RawByte3_B3 "Overview byte 3: RawByte3";
CM_ SG_ 259282800 RawByte4_B4 "Overview byte 4: RawByte4";
CM_ SG_ 259282800 RawByte5_B5 "Overview byte 5: RawByte5";
CM_ SG_ 259282800 RawByte6_B6 "Overview byte 6: RawByte6";
CM_ SG_ 259282800 RawByte7_B7 "Overview byte 7: RawByte7";

VAL_ 252 TCS_ShiftMapDesired 1 "True" 0 "False" ;
VAL_ 252 HDC_BrakeActive 1 "Active" 0 "Inactive" ;
VAL_ 252 VDC_Active 1 "Active" 0 "Inactive" ;
VAL_ 252 TC_RequestedOff 1 "True" 0 "False" ;
VAL_ 252 EBD_ECM 1 "True" 0 "False" ;
VAL_ 252 TCS_Fitted 1 "True" 0 "False" ;
VAL_ 296 Lights_Auto 1 "On" 0 "Off" ;
VAL_ 296 Lights_Fog 1 "On" 0 "Off" ;
VAL_ 296 Lights_Parker 1 "On" 0 "Off" ;
VAL_ 296 Lights_HighBeam 1 "On" 0 "Off" ;
VAL_ 296 Right_Indicator 1 "On" 0 "Off" ;
VAL_ 296 Left_Indicator 1 "On" 0 "Off" ;
VAL_ 296 HighBeamStatus 0 "off" ;
VAL_ 296 IllumLevelDisplay 255 "No" 31 "MaxBrightness" ;
VAL_ 296 AutoHeadlampSwitchStatus 0 "No" ;
VAL_ 296 FogLampStatus 0 "No" ;
VAL_ 296 ParkAndLowBeamStatus 0 "No" ;
VAL_ 296 TurnStalkSwitchSatus 8 "IndicatingLeft" 16 "IndicatingRight" ;
VAL_ 296 RearBeltMinderStatus 0 "" ;
VAL_ 301 Brake_State 3 "Reserved2" 2 "Reserved1" 1 "Brake Pedal Pressed" 0 "Brake Pedal Off" ;
VAL_ 301 Eng_Crank 1 "Active" 0 "Inactive" ;
VAL_ 301 Cruise_Status 7 "Cruise Active" 2 "Cruise Resume" 1 "Cruise On" 0 "Cruise Off" ;
VAL_ 301 OBD_ClearDTC 1 "True" 0 "False" ;
VAL_ 301 HDC_Status 1 "Active" 0 "Inactive" ;
VAL_ 301 Brake_State 3 "Reserved2" 2 "Reserved1" 1 "Brake" 0 "Brake" ;
VAL_ 301 Cruise_Status 7 "Cruise" 2 "Cruise" 1 "Cruise" 0 "Cruise" ;
VAL_ 512 Eng_Crank_Status 3 "Low Voltage Crank Attempt" 2 "Crank In Progress" 1 "Crank Pending" 0 "No Action" ;
VAL_ 512 Cat_Protection_Active 1 "True" 0 "False" ;
VAL_ 512 Inertial_Loss_Type 1 "Engine Torque" 0 "Axle Torque" ;
VAL_ 512 Torque_Type 1 "Engine Torque" 0 "Axle Torque" ;
VAL_ 512 Eng_Crank_Status 3 "Low" 2 "Crank" 1 "Crank" 0 "No" ;
VAL_ 512 Inertial_Loss_Type 1 "Engine" 0 "Axle" ;
VAL_ 512 Torque_Type 1 "Engine" 0 "Axle" ;
VAL_ 528 Gear_Shift_Inhibit 1 "True" 0 "False" ;
VAL_ 528 BTM_Clear_EngOff_Timer 1 "True" 0 "False" ;
VAL_ 528 HDC_Failed 1 "True" 0 "False" ;
VAL_ 528 HDC_Active 1 "True" 0 "False" ;
VAL_ 528 HDC_Enabled 1 "True" 0 "False" ;
VAL_ 528 VDC_Failed 1 "True" 0 "False" ;
VAL_ 528 VDC_Active 1 "True" 0 "False" ;
VAL_ 528 VDC_Disabled_ByUser 1 "True" 0 "False" ;
VAL_ 528 TCS_Failed 1 "True" 0 "False" ;
VAL_ 528 TCS_Active 1 "True" 0 "False" ;
VAL_ 528 TCS_Disabled_ByUser 1 "True" 0 "False" ;
VAL_ 528 ABS_Failed 1 "True" 0 "False" ;
VAL_ 528 EBD_Failed 1 "True" 0 "False" ;
VAL_ 528 ABS_Active 1 "True" 0 "False" ;
VAL_ 528 Split_SlowFast_Torque_Req 1 "True" 0 "False" ;
VAL_ 528 ABD_Fitted 1 "True" 0 "False" ;
VAL_ 528 VDC_Fitted 1 "True" 0 "False" ;
VAL_ 528 TCS_Fitted 1 "True" 0 "False" ;
VAL_ 528 ABS_Fitted 1 "True" 0 "False" ;
VAL_ 528 EBD_Fitted 1 "True" 0 "False" ;
VAL_ 528 Torque_Type 1 "Engine Torque" 0 "Axle Torque" ;
VAL_ 528 VDC_Failed 0 "" ;
VAL_ 528 Torque_Type 1 "Engine" 0 "Axle" ;
VAL_ 560 Transmission_Mode 6 "Reserved - Creep" 5 "Economy" 4 "Reserved - Winter" 3 "Manual Shift Mode" 2 "Performance" 1 "ADP" 0 "Blank" ;
VAL_ 560 Transmission_Fault 1 "True" 0 "False" ;
VAL_ 560 Transmission_Overheat 1 "True" 0 "False" ;
VAL_ 560 Shift_In_Progress 1 "True" 0 "False" ;
VAL_ 560 Torque_Conv_Locked 1 "True" 0 "False" ;
VAL_ 560 Trans_Gear_Pos 255 "Invalid" 241 "Neutral" 240 "Park" 19 "Forward Gear 9" 18 "Forward Gear 8" 17 "Forward Gear 7" 16 "Forward Gear 6" 11 "Reserved" 10 "Reverse" 6 "Forward Gear D" 5 "Forward Gear 5" 4 "Forward Gear 4" 3 "Forward Gear 3" 2 "Forward Gear 2" 1 "Forward Gear 1" 0 "Blank" ;
VAL_ 560 Transmission_Mode 6 "Reserved" 5 "Economy" 4 "Reserved" 3 "Manual" 2 "Performance" 1 "ADP" 0 "Blank" ;
VAL_ 560 Trans_Gear_Pos 255 "Invalid" 241 "Neutral" 240 "Park" 19 "Forward" 18 "Forward" 17 "Forward" 16 "Forward" 11 "Reserved" 10 "Reverse" 6 "Forward" 5 "Forward" 4 "Forward" 3 "Forward" 2 "Forward" 1 "Forward" 0 "Blank" ;
VAL_ 714 BpmContinuousTroubleCodes 0 "NumberOfContinuousTroubleCodesSet" ;
VAL_ 714 BpmOperatingState 0 "ECUOperatingStates" ;
VAL_ 714 BpmOnDemandDtcs 0 "NumberOfOnDemandDTCs" ;
VAL_ 714 SecurityStatusBpm 0 "SecurityStatus" ;
VAL_ 714 BTH_CONTD 0 "BluetoothReceptionSignalStrength" ;
VAL_ 742 AudioFMFrequencyStep 0 "AudioFMFrequencyStep_(Message.Data[1]_*_0.01)" 2 "" 18 "No" 0 "AudioFMFrequencyStep_(Message.Data[1]_*_0.01)" 2 "" 18 "No" ;
VAL_ 742 AudioTunedFreqency 0 "" 50 "100" 47 "94" 46 "" 0 "" 50 "100" 47 "94" 46 "" ;
VAL_ 742 AudioTunerBandPreset 0 "AM_Radio" 0 "AM_Radio" ;
VAL_ 742 RDS_PSN_State 0 "No" 0 "No" ;
VAL_ 754 AudioCurrentMediaMode 65 "AUX1" 66 "AUX2" 67 "CD_MP3" 69 "RADIO" 70 "PHONE" 72 "AudioOff" 97 "SWC_PHONE_BTN_ACTIVE" 101 "SWC_PHONE_BTN_ACTIVE" 104 "SWC_PHONE_BTN_ACTIVE" 0 "No" ;
VAL_ 754 SteeringWheelControlsLeft_ms 8 "SEEK_BUTTON_ACTIVE" 9 "SEEK_BUTTON_ACTIVE" 12 "SEEK_BUTTON_ACTIVE" 16 "SEEK_BUTTON_ACTIVE" 17 "VOL_UP_BTN_ACTIVE" 18 "VOL_UP_BTN_ACTIVE" 20 "VOL_UP_BTN_ACTIVE" 24 "VOL_DOWN_BTN_ACTIVE" 25 "VOL_DOWN_BTN_ACTIVE" 0 "No" ;
VAL_ 754 AudioVolumeLevel 0 "Mute" 1 "Vol_Lvl_2" 2 "Vol_Lvl_4" 3 "Vol_Lvl_6" 4 "Vol_Lvl_8" 5 "Vol_Lvl_10" 6 "Vol_Lvl_12" 7 "Vol_Lvl_14" 8 "Vol_Lvl_16" 9 "Vol_Lvl_18" 10 "Vol_Lvl_20" 11 "Vol_Lvl_22" 12 "Vol_Lvl_24" 13 "Vol_Lvl_26" 14 "Vol_Lvl_28" 15 "Vol_Lvl_30" ;
VAL_ 756 RDS_MessageData0 48 "0" 49 "1" 50 "2" 51 "3" 52 "4" 53 "5" 54 "6" 55 "7" 56 "8" 57 "9" 58 "10" 59 "11" 60 "12" 61 "13" 62 "14" 63 "15" 65 "A" 66 "B" 67 "C" 68 "D" 69 "E" 70 "F" 71 "G" 72 "H" 73 "I" 74 "J" 75 "K" 76 "L" 77 "M" 78 "N" 79 "O" 80 "P" 81 "Q" 82 "R" 83 "S" 84 "T" 85 "U" 86 "V" 87 "W" 88 "X" 89 "Y" 90 "Z" 91 "a" 92 "b" 93 "c" 94 "d" 95 "e" 96 "f" 97 "g" 98 "h" 99 "i" 100 "j" 101 "l" 102 "m" 103 "n" 104 "o" 105 "p" 106 "q" 107 "r" 108 "s" 109 "t" 110 "u" 111 "v" 112 "w" 113 "x" 114 "y" 115 "z" ;
VAL_ 756 RDS_MessageData1 48 "0" 49 "1" 50 "2" 51 "3" 52 "4" 53 "5" 54 "6" 55 "7" 56 "8" 57 "9" 58 "10" 59 "11" 60 "12" 61 "13" 62 "14" 63 "15" 65 "A" 66 "B" 67 "C" 68 "D" 69 "E" 70 "F" 71 "G" 72 "H" 73 "I" 74 "J" 75 "K" 76 "L" 77 "M" 78 "N" 79 "O" 80 "P" 81 "Q" 82 "R" 83 "S" 84 "T" 85 "U" 86 "V" 87 "W" 88 "X" 89 "Y" 90 "Z" 91 "a" 92 "b" 93 "c" 94 "d" 95 "e" 96 "f" 97 "g" 98 "h" 99 "i" 100 "j" 101 "l" 102 "m" 103 "n" 104 "o" 105 "p" 106 "q" 107 "r" 108 "s" 109 "t" 110 "u" 111 "v" 112 "w" 113 "x" 114 "y" 115 "z" ;
VAL_ 756 RDS_MessageData2 48 "0" 49 "1" 50 "2" 51 "3" 52 "4" 53 "5" 54 "6" 55 "7" 56 "8" 57 "9" 58 "10" 59 "11" 60 "12" 61 "13" 62 "14" 63 "15" 65 "A" 66 "B" 67 "C" 68 "D" 69 "E" 70 "F" 71 "G" 72 "H" 73 "I" 74 "J" 75 "K" 76 "L" 77 "M" 78 "N" 79 "O" 80 "P" 81 "Q" 82 "R" 83 "S" 84 "T" 85 "U" 86 "V" 87 "W" 88 "X" 89 "Y" 90 "Z" 91 "a" 92 "b" 93 "c" 94 "d" 95 "e" 96 "f" 97 "g" 98 "h" 99 "i" 100 "j" 101 "l" 102 "m" 103 "n" 104 "o" 105 "p" 106 "q" 107 "r" 108 "s" 109 "t" 110 "u" 111 "v" 112 "w" 113 "x" 114 "y" 115 "z" ;
VAL_ 756 RDS_MessageData3 48 "0" 49 "1" 50 "2" 51 "3" 52 "4" 53 "5" 54 "6" 55 "7" 56 "8" 57 "9" 58 "10" 59 "11" 60 "12" 61 "13" 62 "14" 63 "15" 65 "A" 66 "B" 67 "C" 68 "D" 69 "E" 70 "F" 71 "G" 72 "H" 73 "I" 74 "J" 75 "K" 76 "L" 77 "M" 78 "N" 79 "O" 80 "P" 81 "Q" 82 "R" 83 "S" 84 "T" 85 "U" 86 "V" 87 "W" 88 "X" 89 "Y" 90 "Z" 91 "a" 92 "b" 93 "c" 94 "d" 95 "e" 96 "f" 97 "g" 98 "h" 99 "i" 100 "j" 101 "l" 102 "m" 103 "n" 104 "o" 105 "p" 106 "q" 107 "r" 108 "s" 109 "t" 110 "u" 111 "v" 112 "w" 113 "x" 114 "y" 115 "z" ;
VAL_ 756 RDS_MessageData4 48 "0" 49 "1" 50 "2" 51 "3" 52 "4" 53 "5" 54 "6" 55 "7" 56 "8" 57 "9" 58 "10" 59 "11" 60 "12" 61 "13" 62 "14" 63 "15" 65 "A" 66 "B" 67 "C" 68 "D" 69 "E" 70 "F" 71 "G" 72 "H" 73 "I" 74 "J" 75 "K" 76 "L" 77 "M" 78 "N" 79 "O" 80 "P" 81 "Q" 82 "R" 83 "S" 84 "T" 85 "U" 86 "V" 87 "W" 88 "X" 89 "Y" 90 "Z" 91 "a" 92 "b" 93 "c" 94 "d" 95 "e" 96 "f" 97 "g" 98 "h" 99 "i" 100 "j" 101 "l" 102 "m" 103 "n" 104 "o" 105 "p" 106 "q" 107 "r" 108 "s" 109 "t" 110 "u" 111 "v" 112 "w" 113 "x" 114 "y" 115 "z" ;
VAL_ 756 RDS_MessageData5 48 "0" 49 "1" 50 "2" 51 "3" 52 "4" 53 "5" 54 "6" 55 "7" 56 "8" 57 "9" 58 "10" 59 "11" 60 "12" 61 "13" 62 "14" 63 "15" 65 "A" 66 "B" 67 "C" 68 "D" 69 "E" 70 "F" 71 "G" 72 "H" 73 "I" 74 "J" 75 "K" 76 "L" 77 "M" 78 "N" 79 "O" 80 "P" 81 "Q" 82 "R" 83 "S" 84 "T" 85 "U" 86 "V" 87 "W" 88 "X" 89 "Y" 90 "Z" 91 "a" 92 "b" 93 "c" 94 "d" 95 "e" 96 "f" 97 "g" 98 "h" 99 "i" 100 "j" 101 "l" 102 "m" 103 "n" 104 "o" 105 "p" 106 "q" 107 "r" 108 "s" 109 "t" 110 "u" 111 "v" 112 "w" 113 "x" 114 "y" 115 "z" ;
VAL_ 756 RDS_MessageData6 48 "0" 49 "1" 50 "2" 51 "3" 52 "4" 53 "5" 54 "6" 55 "7" 56 "8" 57 "9" 58 "10" 59 "11" 60 "12" 61 "13" 62 "14" 63 "15" 65 "A" 66 "B" 67 "C" 68 "D" 69 "E" 70 "F" 71 "G" 72 "H" 73 "I" 74 "J" 75 "K" 76 "L" 77 "M" 78 "N" 79 "O" 80 "P" 81 "Q" 82 "R" 83 "S" 84 "T" 85 "U" 86 "V" 87 "W" 88 "X" 89 "Y" 90 "Z" 91 "a" 92 "b" 93 "c" 94 "d" 95 "e" 96 "f" 97 "g" 98 "h" 99 "i" 100 "j" 101 "l" 102 "m" 103 "n" 104 "o" 105 "p" 106 "q" 107 "r" 108 "s" 109 "t" 110 "u" 111 "v" 112 "w" 113 "x" 114 "y" 115 "z" ;
VAL_ 756 RDS_MessageData7 48 "0" 49 "1" 50 "2" 51 "3" 52 "4" 53 "5" 54 "6" 55 "7" 56 "8" 57 "9" 58 "10" 59 "11" 60 "12" 61 "13" 62 "14" 63 "15" 65 "A" 66 "B" 67 "C" 68 "D" 69 "E" 70 "F" 71 "G" 72 "H" 73 "I" 74 "J" 75 "K" 76 "L" 77 "M" 78 "N" 79 "O" 80 "P" 81 "Q" 82 "R" 83 "S" 84 "T" 85 "U" 86 "V" 87 "W" 88 "X" 89 "Y" 90 "Z" 91 "a" 92 "b" 93 "c" 94 "d" 95 "e" 96 "f" 97 "g" 98 "h" 99 "i" 100 "j" 101 "l" 102 "m" 103 "n" 104 "o" 105 "p" 106 "q" 107 "r" 108 "s" 109 "t" 110 "u" 111 "v" 112 "w" 113 "x" 114 "y" 115 "z" ;
VAL_ 757 RDS_MessageData0 49 "1" 50 "2" 51 "3" 52 "4" 53 "5" 54 "6" 55 "7" 56 "8" 57 "9" 58 "10" 59 "11" 60 "12" 61 "13" 62 "14" 63 "15" 65 "A" 66 "B" 67 "C" 68 "D" 69 "E" 70 "F" 71 "G" 72 "H" 73 "I" 74 "J" 75 "K" 76 "L" 77 "M" 78 "N" 79 "O" 80 "P" 81 "Q" 82 "R" 83 "S" 84 "T" 85 "U" 86 "V" 87 "W" 88 "X" 89 "Y" 90 "Z" 91 "a" 92 "b" 93 "c" 94 "d" 95 "e" 96 "f" 97 "g" 98 "h" 99 "i" 100 "j" 101 "l" 102 "m" 103 "n" 104 "o" 105 "p" 106 "q" 107 "r" 108 "s" 109 "t" 110 "u" 111 "v" 112 "w" 113 "x" 114 "y" 115 "z" ;
VAL_ 757 RDS_MessageData1 49 "1" 50 "2" 51 "3" 52 "4" 53 "5" 54 "6" 55 "7" 56 "8" 57 "9" 58 "10" 59 "11" 60 "12" 61 "13" 62 "14" 63 "15" 65 "A" 66 "B" 67 "C" 68 "D" 69 "E" 70 "F" 71 "G" 72 "H" 73 "I" 74 "J" 75 "K" 76 "L" 77 "M" 78 "N" 79 "O" 80 "P" 81 "Q" 82 "R" 83 "S" 84 "T" 85 "U" 86 "V" 87 "W" 88 "X" 89 "Y" 90 "Z" 91 "a" 92 "b" 93 "c" 94 "d" 95 "e" 96 "f" 97 "g" 98 "h" 99 "i" 100 "j" 101 "l" 102 "m" 103 "n" 104 "o" 105 "p" 106 "q" 107 "r" 108 "s" 109 "t" 110 "u" 111 "v" 112 "w" 113 "x" 114 "y" 115 "z" ;
VAL_ 757 RDS_MessageData2 49 "1" 50 "2" 51 "3" 52 "4" 53 "5" 54 "6" 55 "7" 56 "8" 57 "9" 58 "10" 59 "11" 60 "12" 61 "13" 62 "14" 63 "15" 65 "A" 66 "B" 67 "C" 68 "D" 69 "E" 70 "F" 71 "G" 72 "H" 73 "I" 74 "J" 75 "K" 76 "L" 77 "M" 78 "N" 79 "O" 80 "P" 81 "Q" 82 "R" 83 "S" 84 "T" 85 "U" 86 "V" 87 "W" 88 "X" 89 "Y" 90 "Z" 91 "a" 92 "b" 93 "c" 94 "d" 95 "e" 96 "f" 97 "g" 98 "h" 99 "i" 100 "j" 101 "l" 102 "m" 103 "n" 104 "o" 105 "p" 106 "q" 107 "r" 108 "s" 109 "t" 110 "u" 111 "v" 112 "w" 113 "x" 114 "y" 115 "z" ;
VAL_ 757 RDS_MessageData3 49 "1" 50 "2" 51 "3" 52 "4" 53 "5" 54 "6" 55 "7" 56 "8" 57 "9" 58 "10" 59 "11" 60 "12" 61 "13" 62 "14" 63 "15" 65 "A" 66 "B" 67 "C" 68 "D" 69 "E" 70 "F" 71 "G" 72 "H" 73 "I" 74 "J" 75 "K" 76 "L" 77 "M" 78 "N" 79 "O" 80 "P" 81 "Q" 82 "R" 83 "S" 84 "T" 85 "U" 86 "V" 87 "W" 88 "X" 89 "Y" 90 "Z" 91 "a" 92 "b" 93 "c" 94 "d" 95 "e" 96 "f" 97 "g" 98 "h" 99 "i" 100 "j" 101 "l" 102 "m" 103 "n" 104 "o" 105 "p" 106 "q" 107 "r" 108 "s" 109 "t" 110 "u" 111 "v" 112 "w" 113 "x" 114 "y" 115 "z" ;
VAL_ 757 RDS_MessageData4 49 "1" 50 "2" 51 "3" 52 "4" 53 "5" 54 "6" 55 "7" 56 "8" 57 "9" 58 "10" 59 "11" 60 "12" 61 "13" 62 "14" 63 "15" 65 "A" 66 "B" 67 "C" 68 "D" 69 "E" 70 "F" 71 "G" 72 "H" 73 "I" 74 "J" 75 "K" 76 "L" 77 "M" 78 "N" 79 "O" 80 "P" 81 "Q" 82 "R" 83 "S" 84 "T" 85 "U" 86 "V" 87 "W" 88 "X" 89 "Y" 90 "Z" 91 "a" 92 "b" 93 "c" 94 "d" 95 "e" 96 "f" 97 "g" 98 "h" 99 "i" 100 "j" 101 "l" 102 "m" 103 "n" 104 "o" 105 "p" 106 "q" 107 "r" 108 "s" 109 "t" 110 "u" 111 "v" 112 "w" 113 "x" 114 "y" 115 "z" ;
VAL_ 757 RDS_MessageData5 49 "1" 50 "2" 51 "3" 52 "4" 53 "5" 54 "6" 55 "7" 56 "8" 57 "9" 58 "10" 59 "11" 60 "12" 61 "13" 62 "14" 63 "15" 65 "A" 66 "B" 67 "C" 68 "D" 69 "E" 70 "F" 71 "G" 72 "H" 73 "I" 74 "J" 75 "K" 76 "L" 77 "M" 78 "N" 79 "O" 80 "P" 81 "Q" 82 "R" 83 "S" 84 "T" 85 "U" 86 "V" 87 "W" 88 "X" 89 "Y" 90 "Z" 91 "a" 92 "b" 93 "c" 94 "d" 95 "e" 96 "f" 97 "g" 98 "h" 99 "i" 100 "j" 101 "l" 102 "m" 103 "n" 104 "o" 105 "p" 106 "q" 107 "r" 108 "s" 109 "t" 110 "u" 111 "v" 112 "w" 113 "x" 114 "y" 115 "z" ;
VAL_ 757 RDS_MessageData6 49 "1" 50 "2" 51 "3" 52 "4" 53 "5" 54 "6" 55 "7" 56 "8" 57 "9" 58 "10" 59 "11" 60 "12" 61 "13" 62 "14" 63 "15" 65 "A" 66 "B" 67 "C" 68 "D" 69 "E" 70 "F" 71 "G" 72 "H" 73 "I" 74 "J" 75 "K" 76 "L" 77 "M" 78 "N" 79 "O" 80 "P" 81 "Q" 82 "R" 83 "S" 84 "T" 85 "U" 86 "V" 87 "W" 88 "X" 89 "Y" 90 "Z" 91 "a" 92 "b" 93 "c" 94 "d" 95 "e" 96 "f" 97 "g" 98 "h" 99 "i" 100 "j" 101 "l" 102 "m" 103 "n" 104 "o" 105 "p" 106 "q" 107 "r" 108 "s" 109 "t" 110 "u" 111 "v" 112 "w" 113 "x" 114 "y" 115 "z" ;
VAL_ 757 RDS_MessageData7 49 "1" 50 "2" 51 "3" 52 "4" 53 "5" 54 "6" 55 "7" 56 "8" 57 "9" 58 "10" 59 "11" 60 "12" 61 "13" 62 "14" 63 "15" 65 "A" 66 "B" 67 "C" 68 "D" 69 "E" 70 "F" 71 "G" 72 "H" 73 "I" 74 "J" 75 "K" 76 "L" 77 "M" 78 "N" 79 "O" 80 "P" 81 "Q" 82 "R" 83 "S" 84 "T" 85 "U" 86 "V" 87 "W" 88 "X" 89 "Y" 90 "Z" 91 "a" 92 "b" 93 "c" 94 "d" 95 "e" 96 "f" 97 "g" 98 "h" 99 "i" 100 "j" 101 "l" 102 "m" 103 "n" 104 "o" 105 "p" 106 "q" 107 "r" 108 "s" 109 "t" 110 "u" 111 "v" 112 "w" 113 "x" 114 "y" 115 "z" ;
VAL_ 758 RDS_MessageData0 49 "1" 50 "2" 51 "3" 52 "4" 53 "5" 54 "6" 55 "7" 56 "8" 57 "9" 58 "10" 59 "11" 60 "12" 61 "13" 62 "14" 63 "15" 65 "A" 66 "B" 67 "C" 68 "D" 69 "E" 70 "F" 71 "G" 72 "H" 73 "I" 74 "J" 75 "K" 76 "L" 77 "M" 78 "N" 79 "O" 80 "P" 81 "Q" 82 "R" 83 "S" 84 "T" 85 "U" 86 "V" 87 "W" 88 "X" 89 "Y" 90 "Z" 91 "a" 92 "b" 93 "c" 94 "d" 95 "e" 96 "f" 97 "g" 98 "h" 99 "i" 100 "j" 101 "l" 102 "m" 103 "n" 104 "o" 105 "p" 106 "q" 107 "r" 108 "s" 109 "t" 110 "u" 111 "v" 112 "w" 113 "x" 114 "y" 115 "z" ;
VAL_ 758 RDS_MessageData1 49 "1" 50 "2" 51 "3" 52 "4" 53 "5" 54 "6" 55 "7" 56 "8" 57 "9" 58 "10" 59 "11" 60 "12" 61 "13" 62 "14" 63 "15" 65 "A" 66 "B" 67 "C" 68 "D" 69 "E" 70 "F" 71 "G" 72 "H" 73 "I" 74 "J" 75 "K" 76 "L" 77 "M" 78 "N" 79 "O" 80 "P" 81 "Q" 82 "R" 83 "S" 84 "T" 85 "U" 86 "V" 87 "W" 88 "X" 89 "Y" 90 "Z" 91 "a" 92 "b" 93 "c" 94 "d" 95 "e" 96 "f" 97 "g" 98 "h" 99 "i" 100 "j" 101 "l" 102 "m" 103 "n" 104 "o" 105 "p" 106 "q" 107 "r" 108 "s" 109 "t" 110 "u" 111 "v" 112 "w" 113 "x" 114 "y" 115 "z" ;
VAL_ 758 RDS_MessageData2 49 "1" 50 "2" 51 "3" 52 "4" 53 "5" 54 "6" 55 "7" 56 "8" 57 "9" 58 "10" 59 "11" 60 "12" 61 "13" 62 "14" 63 "15" 65 "A" 66 "B" 67 "C" 68 "D" 69 "E" 70 "F" 71 "G" 72 "H" 73 "I" 74 "J" 75 "K" 76 "L" 77 "M" 78 "N" 79 "O" 80 "P" 81 "Q" 82 "R" 83 "S" 84 "T" 85 "U" 86 "V" 87 "W" 88 "X" 89 "Y" 90 "Z" 91 "a" 92 "b" 93 "c" 94 "d" 95 "e" 96 "f" 97 "g" 98 "h" 99 "i" 100 "j" 101 "l" 102 "m" 103 "n" 104 "o" 105 "p" 106 "q" 107 "r" 108 "s" 109 "t" 110 "u" 111 "v" 112 "w" 113 "x" 114 "y" 115 "z" ;
VAL_ 758 RDS_MessageData3 49 "1" 50 "2" 51 "3" 52 "4" 53 "5" 54 "6" 55 "7" 56 "8" 57 "9" 58 "10" 59 "11" 60 "12" 61 "13" 62 "14" 63 "15" 65 "A" 66 "B" 67 "C" 68 "D" 69 "E" 70 "F" 71 "G" 72 "H" 73 "I" 74 "J" 75 "K" 76 "L" 77 "M" 78 "N" 79 "O" 80 "P" 81 "Q" 82 "R" 83 "S" 84 "T" 85 "U" 86 "V" 87 "W" 88 "X" 89 "Y" 90 "Z" 91 "a" 92 "b" 93 "c" 94 "d" 95 "e" 96 "f" 97 "g" 98 "h" 99 "i" 100 "j" 101 "l" 102 "m" 103 "n" 104 "o" 105 "p" 106 "q" 107 "r" 108 "s" 109 "t" 110 "u" 111 "v" 112 "w" 113 "x" 114 "y" 115 "z" ;
VAL_ 758 RDS_MessageData4 49 "1" 50 "2" 51 "3" 52 "4" 53 "5" 54 "6" 55 "7" 56 "8" 57 "9" 58 "10" 59 "11" 60 "12" 61 "13" 62 "14" 63 "15" 65 "A" 66 "B" 67 "C" 68 "D" 69 "E" 70 "F" 71 "G" 72 "H" 73 "I" 74 "J" 75 "K" 76 "L" 77 "M" 78 "N" 79 "O" 80 "P" 81 "Q" 82 "R" 83 "S" 84 "T" 85 "U" 86 "V" 87 "W" 88 "X" 89 "Y" 90 "Z" 91 "a" 92 "b" 93 "c" 94 "d" 95 "e" 96 "f" 97 "g" 98 "h" 99 "i" 100 "j" 101 "l" 102 "m" 103 "n" 104 "o" 105 "p" 106 "q" 107 "r" 108 "s" 109 "t" 110 "u" 111 "v" 112 "w" 113 "x" 114 "y" 115 "z" ;
VAL_ 758 RDS_MessageData5 49 "1" 50 "2" 51 "3" 52 "4" 53 "5" 54 "6" 55 "7" 56 "8" 57 "9" 58 "10" 59 "11" 60 "12" 61 "13" 62 "14" 63 "15" 65 "A" 66 "B" 67 "C" 68 "D" 69 "E" 70 "F" 71 "G" 72 "H" 73 "I" 74 "J" 75 "K" 76 "L" 77 "M" 78 "N" 79 "O" 80 "P" 81 "Q" 82 "R" 83 "S" 84 "T" 85 "U" 86 "V" 87 "W" 88 "X" 89 "Y" 90 "Z" 91 "a" 92 "b" 93 "c" 94 "d" 95 "e" 96 "f" 97 "g" 98 "h" 99 "i" 100 "j" 101 "l" 102 "m" 103 "n" 104 "o" 105 "p" 106 "q" 107 "r" 108 "s" 109 "t" 110 "u" 111 "v" 112 "w" 113 "x" 114 "y" 115 "z" ;
VAL_ 758 RDS_MessageData6 49 "1" 50 "2" 51 "3" 52 "4" 53 "5" 54 "6" 55 "7" 56 "8" 57 "9" 58 "10" 59 "11" 60 "12" 61 "13" 62 "14" 63 "15" 65 "A" 66 "B" 67 "C" 68 "D" 69 "E" 70 "F" 71 "G" 72 "H" 73 "I" 74 "J" 75 "K" 76 "L" 77 "M" 78 "N" 79 "O" 80 "P" 81 "Q" 82 "R" 83 "S" 84 "T" 85 "U" 86 "V" 87 "W" 88 "X" 89 "Y" 90 "Z" 91 "a" 92 "b" 93 "c" 94 "d" 95 "e" 96 "f" 97 "g" 98 "h" 99 "i" 100 "j" 101 "l" 102 "m" 103 "n" 104 "o" 105 "p" 106 "q" 107 "r" 108 "s" 109 "t" 110 "u" 111 "v" 112 "w" 113 "x" 114 "y" 115 "z" ;
VAL_ 758 RDS_MessageData7 49 "1" 50 "2" 51 "3" 52 "4" 53 "5" 54 "6" 55 "7" 56 "8" 57 "9" 58 "10" 59 "11" 60 "12" 61 "13" 62 "14" 63 "15" 65 "A" 66 "B" 67 "C" 68 "D" 69 "E" 70 "F" 71 "G" 72 "H" 73 "I" 74 "J" 75 "K" 76 "L" 77 "M" 78 "N" 79 "O" 80 "P" 81 "Q" 82 "R" 83 "S" 84 "T" 85 "U" 86 "V" 87 "W" 88 "X" 89 "Y" 90 "Z" 91 "a" 92 "b" 93 "c" 94 "d" 95 "e" 96 "f" 97 "g" 98 "h" 99 "i" 100 "j" 101 "l" 102 "m" 103 "n" 104 "o" 105 "p" 106 "q" 107 "r" 108 "s" 109 "t" 110 "u" 111 "v" 112 "w" 113 "x" 114 "y" 115 "z" ;
VAL_ 764 InteriorCommandCentre_MessageData0 1 "MenuSwitch" 4 "SeekUpSwitch" 8 "SeekDownSwitch" 32 "AmFmSwitch" 64 "ScanSwitch" 128 "CdAuxSwitch" ;
VAL_ 764 InteriorCommandCentre_MessageData1 128 "EjectCdSwitch" 64 "LoadSwitch" 0 "NoDescription" ;
VAL_ 764 InteriorCommandCentre_MessageData2 0 "" 33 "OkSwitch" ;
VAL_ 764 InteriorCommandCentre_MessageData3 0 "" 65 "VolumeUpRotEncoder" 129 "VolumeDownRotEncoder" ;
VAL_ 764 InteriorCommandCentre_MessageData4 0 "" ;
VAL_ 764 InteriorCommandCentre_MessageData5 0 "" ;
VAL_ 764 InteriorCommandCentre_MessageData6 0 "" ;
VAL_ 764 InteriorCommandCentre_MessageData7 0 "" ;
VAL_ 775 Reset_Trip_Timer 1 "On" 0 "Off" ;
VAL_ 775 Reset_Avg_Fuel 1 "On" 0 "Off" ;
VAL_ 775 Reset_Avg_Speed 1 "On" 0 "Off" ;
VAL_ 775 Overspeed_Down 1 "On" 0 "Off" ;
VAL_ 775 Overspeed_Up 1 "On" 0 "Off" ;
VAL_ 775 M_Overspeed_On 1 "On" 0 "Off" ;
VAL_ 775 Overspeed_Active_Adjust 1 "On" 0 "Off" ;
VAL_ 775 Diff_Lock_Switch 1 "On" 0 "Off" ;
VAL_ 775 Traction_VDC_Switch 1 "On" 0 "Off" ;
VAL_ 775 Driver_Temp_Down_Switch 1 "On" 0 "Off" ;
VAL_ 775 Driver_Temp_Up_Switch 1 "On" 0 "Off" ;
VAL_ 775 Pass_Temp_Down_Switch 1 "On" 0 "Off" ;
VAL_ 775 Pass_Temp_Up_Switch 1 "On" 0 "Off" ;
VAL_ 775 Fan_Spd_Down_Switch 1 "On" 0 "Off" ;
VAL_ 775 Fan_Spd_Up_Switch 1 "On" 0 "Off" ;
VAL_ 775 Climate_Ctrl_Off_Switch 1 "On" 0 "Off" ;
VAL_ 775 Auto_ACC_On_Switch 1 "On" 0 "Off" ;
VAL_ 775 Air_Dist_Down_Switch 1 "On" 0 "Off" ;
VAL_ 775 Air_Dist_Up_Switch 1 "On" 0 "Off" ;
VAL_ 775 Screen_Floor_Switch 1 "On" 0 "Off" ;
VAL_ 775 Screen_Switch 1 "On" 0 "Off" ;
VAL_ 775 Face_Floor_Switch 1 "On" 0 "Off" ;
VAL_ 775 Floor_Switch 1 "On" 0 "Off" ;
VAL_ 775 Face_Switch 1 "On" 0 "Off" ;
VAL_ 775 Recirc_Switch 1 "On" 0 "Off" ;
VAL_ 775 AC_Switch 1 "On" 0 "Off" ;
VAL_ 775 InteriorCommandCentreBem_MessageData0 2 "WindowDefogFront" 32 "RearDemisterToggle" 64 "CloseCabinOpenCabin" 128 "AirConditioningToggle" ;
VAL_ 775 InteriorCommandCentreBem_MessageData1 4 "FanSpeedIncrease" 8 "FanSpeedDecrease" 16 "Off" 32 "AutoAirConditioning" 128 "CycleVentConfiguration" 0 "NoActiveSwitch" ;
VAL_ 775 InteriorCommandCentreBem_MessageData2 1 "HazardLightSwitch" 64 "ACTempDownSwitch" 128 "ACTempUpSwitch" ;
VAL_ 775 InteriorCommandCentreBem_MessageData3 160 "InteriorLights" 144 "DSCTractionControlButton" 192 "LockButton" 132 "UnlockButton" ;
VAL_ 775 InteriorCommandCentreBem_MessageData4 0 "" ;
VAL_ 775 InteriorCommandCentreBem_MessageData5 0 "" ;
VAL_ 775 InteriorCommandCentreBem_MessageData6 0 "" ;
VAL_ 775 InteriorCommandCentreBem_MessageData7 0 "" ;
VAL_ 781 CD_PlayingNow 0 "No" ;
VAL_ 781 CD_TrackNumber 0 "No" ;
VAL_ 781 CD_Type 0 "" 0 "No" ;
VAL_ 789 CycleLockSetting 4 "CycleTwoStageLocking" 8 "CycleTwoStageLocking" 32 "CycleConfirmLockingWithHorn" 64 "CycleDriveAwayLocking" 128 "CycleConfirmLockingWithIndicators" ;
VAL_ 789 Ignition 0 "" ;
VAL_ 789 FollowMeHomeLighting 0 "Off" 1 "Min" 2 "" 3 "" 4 "" 5 "Mid" 6 "" 7 "" 8 "" 9 "" 10 "Max" ;
VAL_ 789 InteriorLightStatus 0 "" ;
VAL_ 789 CabLightSetting 32 "CycleCabinLightsOnWithUnlockCar" 64 "CabinLightsResetSettings" 128 "CycleCabinLightsOnWithDoorOpen" ;
VAL_ 789 IgnitionState 4 "CycleCabinLightsOnWithIgnitionOff" 32 "CycleCabinLightsOnWithKeyOut" ;
VAL_ 789 AutoHeadlightAdjustment 0 "" 16 "Auto" 32 "Auto" 48 "Auto" 64 "Auto" 80 "Auto" 96 "Auto" 112 "Auto" 128 "" 0 "Off" 1 "Off" 2 "Off" 3 "Off" 4 "Off" 5 "Off" 6 "Off" 7 "Off" 8 "Off" ;
VAL_ 791 VIN 0 "No" ;
VAL_ 851 AC_Max_Request 1 "On" 0 "Off" ;
VAL_ 851 AC_Clutch_Request 1 "On" 0 "Off" ;
VAL_ 851 Off_Seg 1 "On" 0 "Off" ;
VAL_ 851 Semi_Seg 1 "On" 0 "Off" ;
VAL_ 851 Auto_Seg 1 "On" 0 "Off" ;
VAL_ 851 Driver_Seg 1 "On" 0 "Off" ;
VAL_ 851 Pass_Seg 1 "On" 0 "Off" ;
VAL_ 851 Driver_Temp_Seg 1 "On" 0 "Off" ;
VAL_ 851 Pass_Temp_Seg 1 "On" 0 "Off" ;
VAL_ 851 OS_Temp_Seg 1 "On" 0 "Off" ;
VAL_ 851 Fanblade_Seg 1 "On" 0 "Off" ;
VAL_ 851 Person_Seg 1 "On" 0 "Off" ;
VAL_ 851 Screen_Seg 1 "On" 0 "Off" ;
VAL_ 851 Floor_Seg 1 "On" 0 "Off" ;
VAL_ 851 Face_Seg 1 "On" 0 "Off" ;
VAL_ 851 Fresh_Seg 1 "On" 0 "Off" ;
VAL_ 851 Recirc_Seg 1 "On" 0 "Off" ;
VAL_ 851 AC_Seg 1 "On" 0 "Off" ;
VAL_ 864 RC_DIST 0 "EchoValueForRightCornerSensor" ;
VAL_ 864 REAR_SENS 0 "ParkingAidRearSensorStatus" 255 "Active" ;
VAL_ 864 REAR_TONE 0 "ParkingAidSounder" ;
VAL_ 864 VBAT 0 "BatteryVoltage" ;
VAL_ 864 TRAILINS 0 "TrailerInstalled" ;
VAL_ 864 TRANSRV 0 "TransmissionInREVERSE" ;
VAL_ 864 SYS_OZ 0 "SystemOutputZone" ;
VAL_ 864 RM_DIST 0 "EchoValueForRightMiddleSensor" ;
VAL_ 864 PARK_SYS 0 "ParkingAidSystemInactive" 5 "ParkingAidSystemActive" ;
VAL_ 869 ReverseGearSelected 5 "Reverse" ;
VAL_ 1001 Gear_Position_Target 15 "Invalid" 12 "Reverse" 6 "Sixth" 5 "Fifth" 4 "Fourth" 3 "Third" 2 "Second" 1 "First" 0 "Neutral" ;
VAL_ 1001 J_Gate_Selection_Fault 1 "True" 0 "False" ;
VAL_ 1001 Trans_Malfunction 1 "True" 0 "False" ;
VAL_ 1001 TCM_Config_Flag 1 "Not Required" 0 "Required" ;
VAL_ 1001 Torque_Converter_Status 1 "Engaged" 0 "Disengaged" ;
VAL_ 1001 Gear_Selection_Fault 1 "On" 0 "Off" ;
VAL_ 1001 Idle_Neutral_Control 1 "On" 0 "Off" ;
VAL_ 1001 Perf_Mode_Indication 1 "On" 0 "Off" ;
VAL_ 1001 TCM_DTC_MIL_Status 1 "On" 0 "Off" ;
VAL_ 1001 OBD_TCM_Clear_Ack 1 "On" 0 "Off" ;
VAL_ 1001 Transmission_Shift_Map 7 "Cruise " 6 "Manual" 5 "Traction" 4 "Gradient" 3 "Hot" 2 "Not Used" 1 "Sports" 0 "Normal" ;
VAL_ 1001 Gear_Position_Actual 15 "Gear Shift In Progress" 12 "Reverse" 6 "Sixth" 5 "Fifth" 4 "Fourth" 3 "Third" 2 "Second" 1 "First" 0 "Neutral" ;
VAL_ 1001 Gear_Position_Selected 15 "Intermediate" 7 "Fifth" 6 "Second" 5 "Third" 4 "Fourth" 3 "Drive" 2 "Neutral" 1 "Reverse" 0 "Park" ;
VAL_ 1001 TCM_Config_Flag 1 "Not" 0 "Required" ;
VAL_ 1001 Transmission_Shift_Map 7 "Cruise" 6 "Manual" 5 "Traction" 4 "Gradient" 3 "Hot" 2 "Not" 1 "Sports" 0 "Normal" ;
VAL_ 1001 Gear_Position_Actual 15 "Gear" 12 "Reverse" 6 "Sixth" 5 "Fifth" 4 "Fourth" 3 "Third" 2 "Second" 1 "First" 0 "Neutral" ;
VAL_ 1027 Priority_Key_1 1 "On" 0 "Off" ;
VAL_ 1027 Priority_Key_2 1 "On" 0 "Off" ;
VAL_ 1027 Lights_On_Warning 1 "On" 0 "Off" ;
VAL_ 1027 Trailer_Connected 1 "On" 0 "Off" ;
VAL_ 1027 Accessories_Switch 1 "On" 0 "Off" ;
VAL_ 1027 Rear_Demist 1 "On" 0 "Off" ;
VAL_ 1027 Rear_Door_Ajar 1 "On" 0 "Off" ;
VAL_ 1027 LR_Door_Ajar 1 "On" 0 "Off" ;
VAL_ 1027 RR_Door_Ajar 1 "On" 0 "Off" ;
VAL_ 1027 LF_Door_Ajar 1 "On" 0 "Off" ;
VAL_ 1027 RF_Door_Ajar 1 "On" 0 "Off" ;
VAL_ 1030 SeatBeltStatusFrontRight 0 "No" ;
VAL_ 1030 SeatBeltStatusFrontLeft 0 "No" 0 "No" ;
VAL_ 1030 SeatBeltStatusRearLeft 0 "No" ;
VAL_ 1030 SeatBeltStatusRearRight 0 "No" ;
VAL_ 1030 IgnitionState 1 "IgnitionOff" 2 "AccessoryOn" 4 "IgnitionOn" 0 "No" 1 "IgnitionOff" 2 "AccessoryOn" 4 "IgnitionOn" 0 "No" ;
VAL_ 1030 InteriorLightStatus 8 "InteriorLightsOn" 0 "InteriorLightsOff" 8 "InteriorLightsOn" 0 "InteriorLightsOff" ;
VAL_ 1061 Cruise_Set 1 "On" 0 "Off" ;
VAL_ 1061 Cruise_Enable 1 "On" 0 "Off" ;
VAL_ 1063 Immobiliser_Ind 2 "Flash" 1 "On" 0 "Off" ;
VAL_ 1063 DTC_Logging 1 "On" 0 "Off" ;
VAL_ 1063 AC_Shed_Load 1 "True" 0 "False" ;
VAL_ 1063 MIL_Ind 2 "Flash" 1 "On" 0 "Off" ;
VAL_ 1063 ETC_Warning_Ind 2 "Flash" 1 "On" 0 "Off" ;
VAL_ 1063 AC_Compressor_State 1 "On" 0 "Off" ;
VAL_ 1063 Idle_Mode 1 "On" 0 "Off" ;
VAL_ 1063 Diff_Lock_Ind 1 "On" 0 "Off" ;
VAL_ 1063 Engine_Overheat_Warn_Ind 1 "On" 0 "Off" ;
VAL_ 1063 Oil_Pressure_Warn_Ind 1 "On" 0 "Off" ;
VAL_ 1063 Alternator_Fail_Ind 1 "On" 0 "Off" ;
VAL_ 1063 Cruise_Set_Ind 1 "On" 0 "Off" ;
VAL_ 1063 Oil_Low_Ind 1 "On" 0 "Off" ;
VAL_ 1063 AC_Pressure 0 "" ;
VAL_ 1079 MIL_Strategy_On 1 "On" 0 "Off" ;
VAL_ 1079 Park_Brake_Ind 1 "On" 0 "Off" ;
VAL_ 1079 Park_Lights 1 "On" 0 "Off" ;
VAL_ 1079 Fuel_Sender_Fault 1 "True" 0 "False" ;
VAL_ 1079 Low_Fuel_Ind 1 "On" 0 "Off" ;
VAL_ 1101 MIL_Status 1 "On" 0 "Off" ;
VAL_ 1101 CylinderHeadTemp4 0 "" ;
VAL_ 1101 CylinderHeadTemp5 0 "" ;
VAL_ 1101 EngineOilTemperature6 0 "" ;
VAL_ 1101 AtmosphericAbsolutePressure7 0 "" ;
VAL_ 1107 Odometer 0 "0_KM" 1 "1_KM" 10 "10KM" 100 "100KM" 1000 "1000KM" 10000 "10000KM" 100000 "100000KM" 200000 "200000KM" ;
VAL_ 1292 KeepAliveACM 0 "AcmKeepAliveSignal" ;
VAL_ 1363 Inst_Econ_Mode 1 "L per Hr" 0 "L per 100Km" ;
VAL_ 1363 Inst_Econ_Mode 1 "L" 0 "L" ;
VAL_ 1372 KeepAliveFDIM 0 "0" ;
VAL_ 1571 RWD_Flag 1 "True" 0 "False" ;
VAL_ 1571 Fuel_Type_And_Delivery 12 "Petrol LPG Dual Fuel" 11 "LPG EFI" 2 "Petrol EFI" ;
VAL_ 1571 Induction_Type 9 "Unknown" 4 "None" 3 "Supercharged" 2 "Turbocharged" 1 "Naturally Aspirated" ;
VAL_ 1571 Fuel_Type_And_Delivery 12 "Petrol" 11 "LPG" 2 "Petrol" ;
VAL_ 1571 Induction_Type 9 "Unknown" 4 "None" 3 "Supercharged" 2 "Turbocharged" 1 "Naturally" ;
VAL_ 1600 RWD_Flag 1 "True" 0 "False" ;
VAL_ 1600 Transmission_Configuration 1 "Copperhead" 0 "Barra_E265" ;
VAL_ 1600 AutoTransTCMControl_Flag 1 "True" 0 "False" ;
VAL_ 1600 AutoTransPCMControl_Flag 1 "True" 0 "False" ;
VAL_ 1600 ManualTrans_Flag 1 "True" 0 "False" ;
VAL_ 1600 AWD_Flag 1 "True" 0 "False" ;
VAL_ 1600 FWD_Flag 1 "True" 0 "False" ;
